VERSION "2021.24.4"

NS_ :

BS_:

BU_: VEH CH Receiver X

BO_ 22 DI_bmsRequest: 1 VEH
 SG_ DI_bmsOpenContactorsRequest : 4|1@1+ (1,0) [0|1] ""  Receiver
 SG_ DI_bmsRequestInterfaceVersion : 0|4@1+ (1,0) [0|15] ""  Receiver

BO_ 470 DI_limits: 5 VEH
 SG_ DI_limitBaseSpeed : 15|1@1+ (1,0) [0|1] ""  Receiver
 SG_ DI_limitClutch : 28|1@1+ (1,0) [0|1] ""  Receiver
 SG_ DI_limitDcCapTemp : 17|1@1+ (1,0) [0|1] ""  Receiver
 SG_ DI_limitDeltaFluidTemp : 5|1@1+ (1,0) [0|1] ""  Receiver
 SG_ DI_limitDiff : 22|1@1+ (1,0) [0|1] ""  Receiver
 SG_ DI_limitDischargePower : 6|1@1+ (1,0) [0|1] ""  Receiver
 SG_ DI_limitDriveTorque : 10|1@1+ (1,0) [0|1] ""  Receiver
 SG_ DI_limitGracefulPowerOff : 23|1@1+ (1,0) [0|1] ""  Receiver
 SG_ DI_limitIBat : 16|1@1+ (1,0) [0|1] ""  Receiver
 SG_ DI_limitIGBTJunctTemp : 24|1@1+ (1,0) [0|1] ""  Receiver
 SG_ DI_limitInverterTemp : 1|1@1+ (1,0) [0|1] ""  Receiver
 SG_ DI_limitLimpMode : 4|1@1+ (1,0) [0|1] ""  Receiver
 SG_ DI_limitMotorCurrent : 8|1@1+ (1,0) [0|1] ""  Receiver
 SG_ DI_limitMotorSpeed : 20|1@1+ (1,0) [0|1] ""  Receiver
 SG_ DI_limitMotorVoltage : 9|1@1+ (1,0) [0|1] ""  Receiver
 SG_ DI_limitObstacleDetection : 29|1@1+ (1,0) [0|1] ""  Receiver
 SG_ DI_limitOilPumpFluidTemp : 26|1@1+ (1,0) [0|1] ""  Receiver
 SG_ DI_limitPCBTemp : 0|1@1+ (1,0) [0|1] ""  Receiver
 SG_ DI_limitPoleTemp : 3|1@1+ (1,0) [0|1] ""  Receiver
 SG_ DI_limitRegenPower : 7|1@1+ (1,0) [0|1] ""  Receiver
 SG_ DI_limitRegenTorque : 11|1@1+ (1,0) [0|1] ""  Receiver
 SG_ DI_limitRotorTemp : 36|1@1+ (1,0) [0|1] ""  Receiver
 SG_ DI_limitShift : 14|1@1+ (1,0) [0|1] ""  Receiver
 SG_ DI_limitShockTorque : 25|1@1+ (1,0) [0|1] ""  Receiver
 SG_ DI_limitStatorFrequency : 27|1@1+ (1,0) [0|1] ""  Receiver
 SG_ DI_limitStatorTemp : 2|1@1+ (1,0) [0|1] ""  Receiver
 SG_ DI_limitTCDrive : 12|1@1+ (1,0) [0|1] ""  Receiver
 SG_ DI_limitTCRegen : 13|1@1+ (1,0) [0|1] ""  Receiver
 SG_ DI_limitVBatHigh : 19|1@1+ (1,0) [0|1] ""  Receiver
 SG_ DI_limitVBatLow : 18|1@1+ (1,0) [0|1] ""  Receiver
 SG_ DI_limitVehicleSpeed : 21|1@1+ (1,0) [0|1] ""  Receiver
 SG_ DI_limitdcLinkCapTemp : 33|1@1+ (1,0) [0|1] ""  Receiver
 SG_ DI_limithvDcCableTemp : 37|1@1+ (1,0) [0|1] ""  Receiver
 SG_ DI_limitnegDcBusbarTemp : 34|1@1+ (1,0) [0|1] ""  Receiver
 SG_ DI_limitphaseOutBusBarWeldTemp : 31|1@1+ (1,0) [0|1] ""  Receiver
 SG_ DI_limitphaseOutBusbarTemp : 30|1@1+ (1,0) [0|1] ""  Receiver
 SG_ DI_limitphaseOutLugTemp : 32|1@1+ (1,0) [0|1] ""  Receiver
 SG_ DI_limitposDcBusbarTemp : 35|1@1+ (1,0) [0|1] ""  Receiver

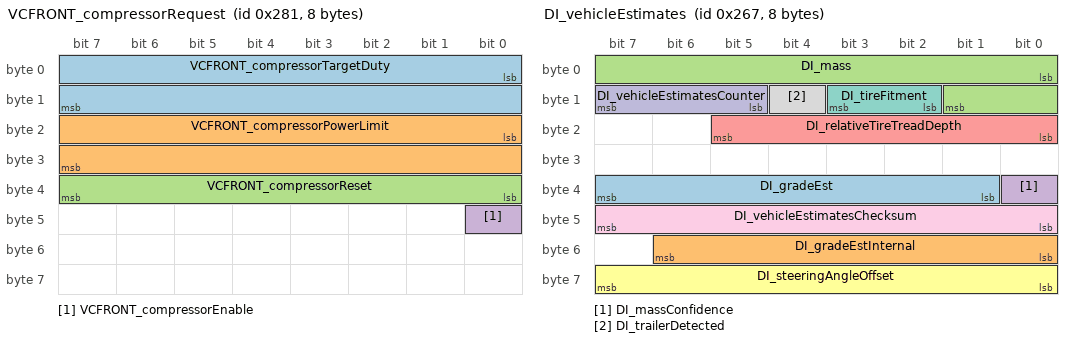
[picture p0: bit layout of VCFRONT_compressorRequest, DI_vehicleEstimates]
BO_ 641 VCFRONT_compressorRequest: 8 VEH
 SG_ VCFRONT_compressorTargetDuty : 0|16@1+ (0.1,0) [0|100] "%"  Receiver
 SG_ VCFRONT_compressorPowerLimit : 16|16@1+ (1,0) [0|65534] "W"  Receiver
 SG_ VCFRONT_compressorReset : 32|8@1+ (1,0) [0|255] ""  Receiver
 SG_ VCFRONT_compressorEnable : 40|1@1+ (1,0) [0|1] ""  Receiver

BO_ 603 APP_environment: 1 CH
 SG_ APP_environmentRainy : 0|1@1+ (1,0) [0|1] "" X
 SG_ APP_environmentSnowy : 1|1@1+ (1,0) [0|1] "" X

BO_ 615 DI_vehicleEstimates: 8 VEH
 SG_ DI_gradeEst : 33|7@1- (1,0) [-40|40] "%"  Receiver
 SG_ DI_gradeEstInternal : 48|7@1- (1,0) [-40|40] "%"  Receiver
 SG_ DI_mass : 0|10@1+ (5,1900) [1900|7010] "kg"  Receiver
 SG_ DI_massConfidence : 32|1@1+ (1,0) [0|1] ""  Receiver
 SG_ DI_relativeTireTreadDepth : 16|6@1- (0.2,0) [-6.2|6.2] "mm"  Receiver
 SG_ DI_steeringAngleOffset : 56|8@1- (0.2,0) [-25.6|25.4] "Deg"  Receiver
 SG_ DI_tireFitment : 10|2@1+ (1,0) [0|3] ""  Receiver
 SG_ DI_trailerDetected : 12|1@1+ (1,0) [0|1] ""  Receiver
 SG_ DI_vehicleEstimatesChecksum : 40|8@1+ (1,0) [0|255] ""  Receiver
 SG_ DI_vehicleEstimatesCounter : 13|3@1+ (1,0) [0|7] ""  Receiver

BO_ 322 VCLEFT_liftgateStatus: 8 VEH
 SG_ VCLEFT_liftgateStatusIndex M : 0|2@1+ (1,0) [0|2] "" X
 SG_ VCLEFT_liftgateLatchRequest m0 : 61|3@1+ (1,0) [0|4] "" X
 SG_ VCLEFT_liftgateMvmntNotAllowedCo m0 : 14|3@1+ (1,0) [0|5] "" X
 SG_ VCLEFT_liftgatePhysicalChimeRequ m0 : 21|3@1+ (1,0) [0|4] "" X
 SG_ VCLEFT_liftgatePosition m1 : 21|7@1- (1,46) [-5|95] "deg" X
 SG_ VCLEFT_liftgatePositionCalibrate m0 : 17|1@1+ (1,0) [0|1] "" X
 SG_ VCLEFT_liftgateRequestSource m0 : 7|3@1+ (1,0) [0|7] "" X
 SG_ VCLEFT_liftgateSpeed m1 : 28|10@1- (0.1,0) [-30|30] "deg/s" X
 SG_ VCLEFT_liftgateState m0 : 3|4@1+ (1,0) [0|12] "" X
 SG_ VCLEFT_liftgateStoppingCondition m0 : 10|4@1+ (1,0) [0|11] "" X
 SG_ VCLEFT_liftgateStrutCurrent m1 : 11|10@1- (0.1,0) [-30|30] "A" X
 SG_ VCLEFT_liftgateStrutDutyCycle m1 : 3|8@1- (1,0) [-100|100] "%" X
 SG_ VCLEFT_liftgateUIChimeRequest m0 : 18|3@1+ (1,0) [0|4] "" X

BO_ 537 VCSEC_TPMSData: 5 CH
 SG_ VCSEC_TPMSDataIndex M : 0|2@1+ (1,0) [0|3] ""  Receiver
 SG_ VCSEC_TPMSBatVoltage0 m0 : 24|8@1+ (0.01,1.5) [1.5|4.04] "V" X
 SG_ VCSEC_TPMSBatVoltage1 m1 : 24|8@1+ (0.01,1.5) [1.5|4.04] "V" X
 SG_ VCSEC_TPMSBatVoltage2 m2 : 24|8@1+ (0.01,1.5) [1.5|4.04] "V" X
 SG_ VCSEC_TPMSBatVoltage3 m3 : 24|8@1+ (0.01,1.5) [1.5|4.04] "V" X
 SG_ VCSEC_TPMSLocation0 m0 : 32|3@1+ (1,0) [0|4] "" X
 SG_ VCSEC_TPMSLocation1 m1 : 32|3@1+ (1,0) [0|4] "" X
 SG_ VCSEC_TPMSLocation2 m2 : 32|3@1+ (1,0) [0|4] "" X
 SG_ VCSEC_TPMSLocation3 m3 : 32|3@1+ (1,0) [0|4] "" X
 SG_ VCSEC_TPMSPressure0 m0 : 8|8@1+ (0.025,0) [0|6.35] "bar" X
 SG_ VCSEC_TPMSPressure1 m1 : 8|8@1+ (0.025,0) [0|6.35] "bar" X
 SG_ VCSEC_TPMSPressure2 m2 : 8|8@1+ (0.025,0) [0|6.35] "bar" X
 SG_ VCSEC_TPMSPressure3 m3 : 8|8@1+ (0.025,0) [0|6.35] "bar" X
 SG_ VCSEC_TPMSTemperature0 m0 : 16|8@1+ (1,-40) [-40|214] "C" X
 SG_ VCSEC_TPMSTemperature1 m1 : 16|8@1+ (1,-40) [-40|214] "C" X
 SG_ VCSEC_TPMSTemperature2 m2 : 16|8@1+ (1,-40) [-40|214] "C" X
 SG_ VCSEC_TPMSTemperature3 m3 : 16|8@1+ (1,-40) [-40|214] "C" X

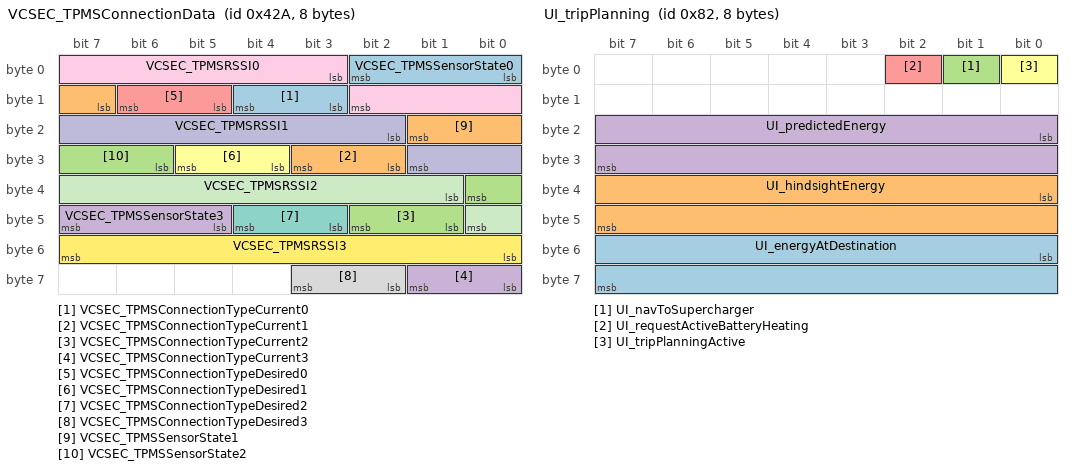
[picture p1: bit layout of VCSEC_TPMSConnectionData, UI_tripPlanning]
BO_ 1066 VCSEC_TPMSConnectionData: 8 VEH
 SG_ VCSEC_TPMSConnectionTypeCurrent0 : 11|2@1+ (1,0) [0|2] "" X
 SG_ VCSEC_TPMSConnectionTypeCurrent1 : 26|2@1+ (1,0) [0|2] "" X
 SG_ VCSEC_TPMSConnectionTypeCurrent2 : 41|2@1+ (1,0) [0|2] "" X
 SG_ VCSEC_TPMSConnectionTypeCurrent3 : 56|2@1+ (1,0) [0|2] "" X
 SG_ VCSEC_TPMSConnectionTypeDesired0 : 13|2@1+ (1,0) [0|2] "" X
 SG_ VCSEC_TPMSConnectionTypeDesired1 : 28|2@1+ (1,0) [0|2] "" X
 SG_ VCSEC_TPMSConnectionTypeDesired2 : 43|2@1+ (1,0) [0|2] "" X
 SG_ VCSEC_TPMSConnectionTypeDesired3 : 58|2@1+ (1,0) [0|2] "" X
 SG_ VCSEC_TPMSRSSI0 : 3|8@1- (1,0) [-127|0] "dBm" X
 SG_ VCSEC_TPMSRSSI1 : 18|8@1- (1,0) [-127|0] "dBm" X
 SG_ VCSEC_TPMSRSSI2 : 33|8@1- (1,0) [-127|0] "dBm" X
 SG_ VCSEC_TPMSRSSI3 : 48|8@1- (1,0) [-127|0] "dBm" X
 SG_ VCSEC_TPMSSensorState0 : 0|3@1+ (1,0) [0|4] "" X
 SG_ VCSEC_TPMSSensorState1 : 15|3@1+ (1,0) [0|4] "" X
 SG_ VCSEC_TPMSSensorState2 : 30|3@1+ (1,0) [0|4] "" X
 SG_ VCSEC_TPMSSensorState3 : 45|3@1+ (1,0) [0|4] "" X

BO_ 994 VCLEFT_lightStatus: 7 VEH
 SG_ VCLEFT_FLMapLightStatus : 6|2@1+ (1,0) [0|3] "" X
 SG_ VCLEFT_FLMapLightSwitchPressed : 14|1@1+ (1,0) [0|1] "" X
 SG_ VCLEFT_FRMapLightStatus : 8|2@1+ (1,0) [0|3] "" X
 SG_ VCLEFT_FRMapLightSwitchPressed : 15|1@1+ (1,0) [0|1] "" X
 SG_ VCLEFT_RLMapLightStatus : 10|2@1+ (1,0) [0|3] "" X
 SG_ VCLEFT_RLMapLightSwitchPressed : 16|1@1+ (1,0) [0|1] "" X
 SG_ VCLEFT_RRMapLightStatus : 12|2@1+ (1,0) [0|3] "" X
 SG_ VCLEFT_RRMapLightSwitchPressed : 17|1@1+ (1,0) [0|1] "" X
 SG_ VCLEFT_brakeLightStatus : 0|2@1+ (1,0) [0|3] "" X
 SG_ VCLEFT_brakeTrailerLightStatus : 22|2@1+ (1,0) [0|3] "" X
 SG_ VCLEFT_dynamicBrakeLightStatus : 44|2@1+ (1,0) [0|2] "" X
 SG_ VCLEFT_fogTrailerLightStatus : 26|2@1+ (1,0) [0|3] "" X
 SG_ VCLEFT_frontRideHeight : 28|8@1- (1,0) [-127|127] "mm" X
 SG_ VCLEFT_leftTurnTrailerLightStatus : 18|2@1+ (1,0) [0|3] "" X
 SG_ VCLEFT_rearRideHeight : 36|8@1- (1,0) [-127|127] "mm" X
 SG_ VCLEFT_reverseTrailerLightStatus : 49|2@1+ (1,0) [0|3] "" X
 SG_ VCLEFT_rideHeightSensorFault : 48|1@1+ (1,0) [0|1] "" X
 SG_ VCLEFT_rightTrnTrailerLightStatus : 20|2@1+ (1,0) [0|3] "" X
 SG_ VCLEFT_tailLightStatus : 2|2@1+ (1,0) [0|3] "" X
 SG_ VCLEFT_tailTrailerLightStatus : 24|2@1+ (1,0) [0|3] "" X
 SG_ VCLEFT_trailerDetected : 46|2@1+ (1,0) [0|3] "" X
 SG_ VCLEFT_turnSignalStatus : 4|2@1+ (1,0) [0|3] "" X

BO_ 513 VCFRONT_logging10Hz2: 8 VEH
 SG_ VCFRONT_logging10Hz2 M : 0|3@1+ (1,0) [0|7] "" X
 SG_ VCFRONT_activeLouverOpenPos m1 : 16|7@1+ (1,0) [0|100] "%" X
 SG_ VCFRONT_activeLouverOpenPosTarg m1 : 8|7@1+ (1,0) [0|100] "%" X
 SG_ VCFRONT_cclExvFlow m3 : 44|10@1+ (0.1,0) [0|100] "%" X
 SG_ VCFRONT_cclExvFlowTarget m5 : 44|10@1+ (0.1,0) [0|100] "%" X
 SG_ VCFRONT_cclExvState m6 : 20|3@1+ (1,0) [0|7] "" X
 SG_ VCFRONT_ccrExvFlow m3 : 54|10@1+ (0.1,0) [0|100] "%" X
 SG_ VCFRONT_ccrExvFlowTarget m5 : 54|10@1+ (0.1,0) [0|100] "%" X
 SG_ VCFRONT_ccrExvState m6 : 24|4@1+ (1,0) [0|7] "" X
 SG_ VCFRONT_chillerExvFlow m3 : 3|10@1+ (0.1,0) [0|100] "%" X
 SG_ VCFRONT_chillerExvFlowTarget m5 : 3|10@1+ (0.1,0) [0|100] "%" X
 SG_ VCFRONT_chillerExvState m6 : 3|4@1+ (1,0) [0|7] "" X
 SG_ VCFRONT_compDemandChiller m2 : 39|7@1+ (1,0) [0|100] "%" X
 SG_ VCFRONT_compDemandEvap m2 : 26|7@1+ (1,0) [0|100] "%" X
 SG_ VCFRONT_compressorState m2 : 24|2@1+ (1,0) [0|3] "" X
 SG_ VCFRONT_coolantValveMode m2 : 61|2@1+ (1,0) [0|3] "" X
 SG_ VCFRONT_evapExvFlow m3 : 13|10@1+ (0.1,0) [0|100] "%" X
 SG_ VCFRONT_evapExvFlowTarget m5 : 13|10@1+ (0.1,0) [0|100] "%" X
 SG_ VCFRONT_evapExvState m6 : 8|4@1+ (1,0) [0|7] "" X
 SG_ VCFRONT_exvFlowTarget m0 : 54|10@1+ (0.1,0) [0|100] "%" X
 SG_ VCFRONT_exvState m2 : 33|4@1+ (1,0) [0|7] "" X
 SG_ VCFRONT_fanDemand m2 : 16|7@1+ (1,0) [0|100] "%" X
 SG_ VCFRONT_hpBatteryLoadType m4 : 16|2@1+ (1,0) [0|2] "" X
 SG_ VCFRONT_hpBlendType m4 : 11|2@1+ (1,0) [0|2] "" X
 SG_ VCFRONT_hpCabinLoadType m4 : 14|2@1+ (1,0) [0|3] "" X
 SG_ VCFRONT_hpDominantLoad m4 : 8|3@1+ (1,0) [0|6] "" X
 SG_ VCFRONT_hpHighSideHX m4 : 3|2@1+ (1,0) [0|3] "" X
 SG_ VCFRONT_hpLowSideHX m4 : 5|2@1+ (1,0) [0|3] "" X
 SG_ VCFRONT_hpQuietModeEnabled m4 : 13|1@1+ (1,0) [0|1] "" X
 SG_ VCFRONT_hpReqCoolantMode m4 : 18|3@1+ (1,0) [0|4] "" X
 SG_ VCFRONT_lccExvFlow m3 : 34|10@1+ (0.1,0) [0|100] "%" X
 SG_ VCFRONT_lccExvFlowTarget m5 : 34|10@1+ (0.1,0) [0|100] "%" X
 SG_ VCFRONT_lccExvState m6 : 16|4@1+ (1,0) [0|8] "" X
 SG_ VCFRONT_pressureRefrigDischargeV m2 : 53|8@1+ (0.125,0) [0|31.75] "bar" X
 SG_ VCFRONT_pressureRefrigLiquid m1 : 40|8@1+ (0.125,0) [0|31.75] "bar" X
 SG_ VCFRONT_pressureRefrigSuctionVit m2 : 46|7@1+ (0.125,0) [0|11.5] "bar" X
 SG_ VCFRONT_pumpBatteryRPMActual m0 : 3|10@1+ (10,0) [0|10000] "rpm" X
 SG_ VCFRONT_pumpPowertrainRPMActual m0 : 13|10@1+ (10,0) [0|10000] "rpm" X
 SG_ VCFRONT_radiatorFanRPMActual m0 : 24|10@1+ (10,0) [0|10000] "rpm" X
 SG_ VCFRONT_recircExvFlow m3 : 24|10@1+ (0.1,0) [0|100] "%" X
 SG_ VCFRONT_recircExvFlowTarget m5 : 24|10@1+ (0.1,0) [0|100] "%" X
 SG_ VCFRONT_recircExvState m6 : 12|3@1+ (1,0) [0|7] "" X
 SG_ VCFRONT_solenoidEvapState m2 : 37|2@1+ (1,0) [0|3] "" X
 SG_ VCFRONT_tempRefrigDischarge m2 : 3|11@1+ (0.125,-40) [-40|150] "C" X
 SG_ VCFRONT_tempRefrigLiquid m1 : 24|11@1+ (0.125,-40) [-40|150] "C" X
 SG_ VCFRONT_tempSuperheatActFiltered m1 : 48|8@1- (0.25,26.5) [-5|58] "C" X
 SG_ VCFRONT_tempSuperheatActual m0 : 34|10@1+ (0.1,-20) [-20|80] "C" X
 SG_ VCFRONT_tempSuperheatTarget m0 : 44|10@1+ (0.1,0) [0|60] "C" X

BO_ 130 UI_tripPlanning: 8 VEH
 SG_ UI_energyAtDestination : 48|16@1- (0.01,0) [-327.67|327.67] "kWh" X
 SG_ UI_hindsightEnergy : 32|16@1- (0.01,0) [-327.67|327.67] "kWh" X
 SG_ UI_navToSupercharger : 1|1@1+ (1,0) [0|1] "" X
 SG_ UI_predictedEnergy : 16|16@1- (0.01,0) [-327.67|327.67] "kWh" X
 SG_ UI_requestActiveBatteryHeating : 2|1@1+ (1,0) [0|1] "" X
 SG_ UI_tripPlanningActive : 0|1@1+ (1,0) [0|1] "" X

BO_ 139 UI_tripPlanning2: 6 VEH
 SG_ UI_maxSpeedToReachDestination : 0|16@1+ (0.01,0) [0|655.34] "m/s" X
 SG_ UI_remainingWeightedRMSSpeed : 16|16@1+ (0.01,0) [0|655.34] "m/s" X
 SG_ UI_timeToDestination : 32|16@1+ (1,0) [0|65534] "s" X

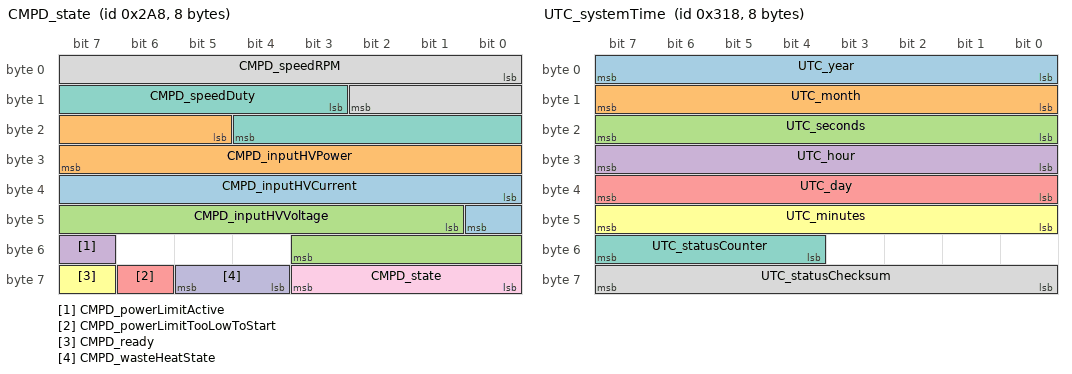
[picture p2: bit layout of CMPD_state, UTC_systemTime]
BO_ 680 CMPD_state: 8 VEH
 SG_ CMPD_inputHVCurrent : 32|9@1+ (0.1,0) [0|50] "A" X
 SG_ CMPD_inputHVPower : 21|11@1+ (10,0) [0|20000] "W" X
 SG_ CMPD_inputHVVoltage : 41|11@1+ (0.5,0) [0|1000] "V" X
 SG_ CMPD_powerLimitActive : 55|1@1+ (1,0) [0|1] "" X
 SG_ CMPD_powerLimitTooLowToStart : 62|1@1+ (1,0) [0|1] "" X
 SG_ CMPD_ready : 63|1@1+ (1,0) [0|1] "" X
 SG_ CMPD_speedDuty : 11|10@1+ (0.1,0) [0|100] "%" X
 SG_ CMPD_speedRPM : 0|11@1+ (10,0) [0|20000] "RPM" X
 SG_ CMPD_state : 56|4@1+ (1,0) [0|15] "" X
 SG_ CMPD_wasteHeatState : 60|2@1+ (1,0) [0|3] "" X

BO_ 1029 VIN_info: 8 VEH
 SG_ VIN_infoIndex M : 0|8@1+ (1,0) [0|255] "" X
 SG_ VIN_B405 m17 : 8|56@1+ (1,0) [0|7.2057594038E+016] "" X
 SG_ VIN_C405 m18 : 8|56@1+ (1,0) [0|7.2057594038E+016] "" X
 SG_ VIN_A405 m16 : 8|56@1+ (1,0) [0|7.2057594038E+016] "" X

BO_ 1025 BMS_brickVoltages: 8 VEH
 SG_ BMS_brickIndex M : 0|8@1+ (1,0) [0|0] ""  Receiver
 SG_ BMS_brickStatus : 8|8@1+ (1,0) [0|0] ""  Receiver
 SG_ BMS_brick0 m0 : 16|16@1+ (0.0001,0) [0|0] "V"  Receiver
 SG_ BMS_brick1 m0 : 32|16@1+ (0.0001,0) [0|0] "V"  Receiver
 SG_ BMS_brick2 m0 : 48|16@1+ (0.0001,0) [0|0] "V"  Receiver
 SG_ BMS_brick3 m1 : 16|16@1+ (0.0001,0) [0|0] "V"  Receiver
 SG_ BMS_brick4 m1 : 32|16@1+ (0.0001,0) [0|0] "V"  Receiver
 SG_ BMS_brick5 m1 : 48|16@1+ (0.0001,0) [0|0] "V"  Receiver
 SG_ BMS_brick6 m2 : 16|16@1+ (0.0001,0) [0|0] "V"  Receiver
 SG_ BMS_brick7 m2 : 32|16@1+ (0.0001,0) [0|0] "V"  Receiver
 SG_ BMS_brick8 m2 : 48|16@1+ (0.0001,0) [0|0] "V"  Receiver
 SG_ BMS_brick9 m3 : 16|16@1+ (0.0001,0) [0|0] "V"  Receiver
 SG_ BMS_brick10 m3 : 32|16@1+ (0.0001,0) [0|0] "V"  Receiver
 SG_ BMS_brick11 m3 : 48|16@1+ (0.0001,0) [0|0] "V"  Receiver
 SG_ BMS_brick12 m4 : 16|16@1+ (0.0001,0) [0|0] "V"  Receiver
 SG_ BMS_brick13 m4 : 32|16@1+ (0.0001,0) [0|0] "V"  Receiver
 SG_ BMS_brick14 m4 : 48|16@1+ (0.0001,0) [0|0] "V"  Receiver
 SG_ BMS_brick15 m5 : 16|16@1+ (0.0001,0) [0|0] "V"  Receiver
 SG_ BMS_brick16 m5 : 32|16@1+ (0.0001,0) [0|0] "V"  Receiver
 SG_ BMS_brick17 m5 : 48|16@1+ (0.0001,0) [0|0] "V"  Receiver
 SG_ BMS_brick18 m6 : 16|16@1+ (0.0001,0) [0|0] "V"  Receiver
 SG_ BMS_brick19 m6 : 32|16@1+ (0.0001,0) [0|0] "V"  Receiver
 SG_ BMS_brick20 m6 : 48|16@1+ (0.0001,0) [0|0] "V"  Receiver
 SG_ BMS_brick21 m7 : 16|16@1+ (0.0001,0) [0|0] "V"  Receiver
 SG_ BMS_brick22 m7 : 32|16@1+ (0.0001,0) [0|0] "V"  Receiver
 SG_ BMS_brick23 m7 : 48|16@1+ (0.0001,0) [0|0] "V"  Receiver
 SG_ BMS_brick24 m8 : 16|16@1+ (0.0001,0) [0|0] "V"  Receiver
 SG_ BMS_brick25 m8 : 32|16@1+ (0.0001,0) [0|0] "V"  Receiver
 SG_ BMS_brick26 m8 : 48|16@1+ (0.0001,0) [0|0] "V"  Receiver
 SG_ BMS_brick27 m9 : 16|16@1+ (0.0001,0) [0|0] "V"  Receiver
 SG_ BMS_brick28 m9 : 32|16@1+ (0.0001,0) [0|0] "V"  Receiver
 SG_ BMS_brick29 m9 : 48|16@1+ (0.0001,0) [0|0] "V"  Receiver
 SG_ BMS_brick30 m10 : 16|16@1+ (0.0001,0) [0|0] "V"  Receiver
 SG_ BMS_brick31 m10 : 32|16@1+ (0.0001,0) [0|0] "V"  Receiver
 SG_ BMS_brick32 m10 : 48|16@1+ (0.0001,0) [0|0] "V"  Receiver
 SG_ BMS_brick34 m11 : 16|16@1+ (0.0001,0) [0|0] "V"  Receiver
 SG_ BMS_brick33 m11 : 32|16@1+ (0.0001,0) [0|0] "V"  Receiver
 SG_ BMS_brick35 m11 : 48|16@1+ (0.0001,0) [0|0] "V"  Receiver
 SG_ BMS_brick36 m12 : 16|16@1+ (0.0001,0) [0|0] "V"  Receiver
 SG_ BMS_brick37 m12 : 32|16@1+ (0.0001,0) [0|0] "V"  Receiver
 SG_ BMS_brick38 m12 : 48|16@1+ (0.0001,0) [0|0] "V"  Receiver
 SG_ BMS_brick39 m13 : 16|16@1+ (0.0001,0) [0|0] "V"  Receiver
 SG_ BMS_brick40 m13 : 32|16@1+ (0.0001,0) [0|0] "V"  Receiver
 SG_ BMS_brick41 m13 : 48|16@1+ (0.0001,0) [0|0] "V"  Receiver
 SG_ BMS_brick42 m14 : 16|16@1+ (0.0001,0) [0|0] "V"  Receiver
 SG_ BMS_brick43 m14 : 32|16@1+ (0.0001,0) [0|0] "V"  Receiver
 SG_ BMS_brick44 m14 : 48|16@1+ (0.0001,0) [0|0] "V"  Receiver
 SG_ BMS_brick45 m15 : 16|16@1+ (0.0001,0) [0|0] "V"  Receiver
 SG_ BMS_brick46 m15 : 32|16@1+ (0.0001,0) [0|0] "V"  Receiver
 SG_ BMS_brick47 m15 : 48|16@1+ (0.0001,0) [0|0] "V"  Receiver
 SG_ BMS_brick48 m16 : 16|16@1+ (0.0001,0) [0|0] "V"  Receiver
 SG_ BMS_brick49 m16 : 32|16@1+ (0.0001,0) [0|0] "V"  Receiver
 SG_ BMS_brick50 m16 : 48|16@1+ (0.0001,0) [0|0] "V"  Receiver
 SG_ BMS_brick51 m17 : 16|16@1+ (0.0001,0) [0|0] "V"  Receiver
 SG_ BMS_brick52 m17 : 32|16@1+ (0.0001,0) [0|0] "V"  Receiver
 SG_ BMS_brick53 m17 : 48|16@1+ (0.0001,0) [0|0] "V"  Receiver
 SG_ BMS_brick54 m18 : 16|16@1+ (0.0001,0) [0|0] "V"  Receiver
 SG_ BMS_brick55 m18 : 32|16@1+ (0.0001,0) [0|0] "V"  Receiver
 SG_ BMS_brick56 m18 : 48|16@1+ (0.0001,0) [0|0] "V"  Receiver
 SG_ BMS_brick57 m19 : 16|16@1+ (0.0001,0) [0|0] "V"  Receiver
 SG_ BMS_brick58 m19 : 32|16@1+ (0.0001,0) [0|0] "V"  Receiver
 SG_ BMS_brick59 m19 : 48|16@1+ (0.0001,0) [0|0] "V"  Receiver
 SG_ BMS_brick60 m20 : 16|16@1+ (0.0001,0) [0|0] "V"  Receiver
 SG_ BMS_brick61 m20 : 32|16@1+ (0.0001,0) [0|0] "V"  Receiver
 SG_ BMS_brick62 m20 : 48|16@1+ (0.0001,0) [0|0] "V"  Receiver
 SG_ BMS_brick63 m21 : 16|16@1+ (0.0001,0) [0|0] "V"  Receiver
 SG_ BMS_brick64 m21 : 32|16@1+ (0.0001,0) [0|0] "V"  Receiver
 SG_ BMS_brick65 m21 : 48|16@1+ (0.0001,0) [0|0] "V"  Receiver
 SG_ BMS_brick66 m22 : 16|16@1+ (0.0001,0) [0|0] "V"  Receiver
 SG_ BMS_brick67 m22 : 32|16@1+ (0.0001,0) [0|0] "V"  Receiver
 SG_ BMS_brick68 m22 : 48|16@1+ (0.0001,0) [0|0] "V"  Receiver
 SG_ BMS_brick69 m23 : 16|16@1+ (0.0001,0) [0|0] "V"  Receiver
 SG_ BMS_brick70 m23 : 32|16@1+ (0.0001,0) [0|0] "V"  Receiver
 SG_ BMS_brick71 m23 : 48|16@1+ (0.0001,0) [0|0] "V"  Receiver
 SG_ BMS_brick72 m24 : 16|16@1+ (0.0001,0) [0|0] "V"  Receiver
 SG_ BMS_brick73 m24 : 32|16@1+ (0.0001,0) [0|0] "V"  Receiver
 SG_ BMS_brick74 m24 : 48|16@1+ (0.0001,0) [0|0] "V"  Receiver
 SG_ BMS_brick75 m25 : 16|16@1+ (0.0001,0) [0|0] "V"  Receiver
 SG_ BMS_brick76 m25 : 32|16@1+ (0.0001,0) [0|0] "V"  Receiver
 SG_ BMS_brick77 m25 : 48|16@1+ (0.0001,0) [0|0] "V"  Receiver
 SG_ BMS_brick78 m26 : 16|16@1+ (0.0001,0) [0|0] "V"  Receiver
 SG_ BMS_brick79 m26 : 32|16@1+ (0.0001,0) [0|0] "V"  Receiver
 SG_ BMS_brick80 m26 : 48|16@1+ (0.0001,0) [0|0] "V"  Receiver
 SG_ BMS_brick81 m27 : 16|16@1+ (0.0001,0) [0|0] "V"  Receiver
 SG_ BMS_brick82 m27 : 32|16@1+ (0.0001,0) [0|0] "V"  Receiver
 SG_ BMS_brick83 m27 : 48|16@1+ (0.0001,0) [0|0] "V"  Receiver
 SG_ BMS_brick84 m28 : 16|16@1+ (0.0001,0) [0|0] "V"  Receiver
 SG_ BMS_brick85 m28 : 32|16@1+ (0.0001,0) [0|0] "V"  Receiver
 SG_ BMS_brick86 m28 : 48|16@1+ (0.0001,0) [0|0] "V"  Receiver
 SG_ BMS_brick87 m29 : 16|16@1+ (0.0001,0) [0|0] "V"  Receiver
 SG_ BMS_brick88 m29 : 32|16@1+ (0.0001,0) [0|0] "V"  Receiver
 SG_ BMS_brick89 m29 : 48|16@1+ (0.0001,0) [0|0] "V"  Receiver
 SG_ BMS_brick90 m30 : 16|16@1+ (0.0001,0) [0|0] "V"  Receiver
 SG_ BMS_brick91 m30 : 32|16@1+ (0.0001,0) [0|0] "V"  Receiver
 SG_ BMS_brick92 m30 : 48|16@1+ (0.0001,0) [0|0] "V"  Receiver
 SG_ BMS_brick93 m31 : 16|16@1+ (0.0001,0) [0|0] "V"  Receiver
 SG_ BMS_brick94 m31 : 32|16@1+ (0.0001,0) [0|0] "V"  Receiver
 SG_ BMS_brick95 m31 : 48|16@1+ (0.0001,0) [0|0] "V"  Receiver
 SG_ BMS_brick96 m32 : 16|16@1+ (0.0001,0) [0|0] "V"  Receiver
 SG_ BMS_brick97 m32 : 32|16@1+ (0.0001,0) [0|0] "V"  Receiver
 SG_ BMS_brick98 m32 : 48|16@1+ (0.0001,0) [0|0] "V"  Receiver
 SG_ BMS_brick99 m33 : 16|16@1+ (0.0001,0) [0|0] "V"  Receiver
 SG_ BMS_brick100 m33 : 32|16@1+ (0.0001,0) [0|0] "V"  Receiver
 SG_ BMS_brick101 m33 : 48|16@1+ (0.0001,0) [0|0] "V"  Receiver
 SG_ BMS_brick102 m34 : 16|16@1+ (0.0001,0) [0|0] "V"  Receiver
 SG_ BMS_brick103 m34 : 32|16@1+ (0.0001,0) [0|0] "V"  Receiver
 SG_ BMS_brick104 m34 : 48|16@1+ (0.0001,0) [0|0] "V"  Receiver
 SG_ BMS_brick105 m35 : 16|16@1+ (0.0001,0) [0|0] "V"  Receiver
 SG_ BMS_brick106 m35 : 32|16@1+ (0.0001,0) [0|0] "V"  Receiver
 SG_ BMS_brick107 m35 : 48|16@1+ (0.0001,0) [0|0] "V"  Receiver

BO_ 792 UTC_systemTime: 8 VEH
 SG_ UTC_year: 0|8@1+ (1,0) [0|0] "" X
 SG_ UTC_month: 8|8@1+ (1,0) [0|0] "" X
 SG_ UTC_seconds: 16|8@1+ (1,0) [0|0] "" X
 SG_ UTC_hour: 24|8@1+ (1,0) [0|0] "" X
 SG_ UTC_day: 32|8@1+ (1,0) [0|0] "" X
 SG_ UTC_minutes: 40|8@1+ (1,0) [0|0] "" X
 SG_ UTC_statusCounter: 52|4@1+ (1,0) [0|0] "" X
 SG_ UTC_statusChecksum: 56|8@1+ (1,0) [0|0] "" X

BO_ 1320 UTC_unixTime: 4 VEH
 SG_ UTC_unixTime : 0|32@0+ (1,0) [0|0] "sec" X

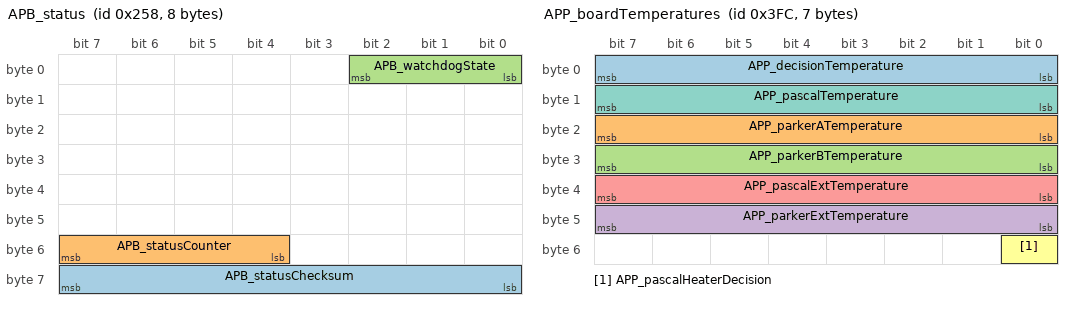
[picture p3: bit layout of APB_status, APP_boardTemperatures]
BO_ 600 APB_status: 8 CH
 SG_ APB_statusChecksum: 56|8@1+ (1,0) [0|0] "" X
 SG_ APB_statusCounter: 52|4@1+ (1,0) [0|0] "" X
 SG_ APB_watchdogState: 0|3@1+ (1,0) [0|0] "" X

BO_ 1020 APP_boardTemperatures: 7 CH
 SG_ APP_decisionTemperature: 0|8@1+ (1,-128) [0|0] "C" X
 SG_ APP_parkerATemperature: 16|8@1+ (1,-128) [0|0] "C" X
 SG_ APP_parkerBTemperature: 24|8@1+ (1,-128) [0|0] "C" X
 SG_ APP_parkerExtTemperature: 40|8@1+ (1,-128) [0|0] "C" X
 SG_ APP_pascalExtTemperature: 32|8@1+ (1,-128) [0|0] "C" X
 SG_ APP_pascalHeaterDecision: 48|1@1+ (1,0) [0|0] "" X
 SG_ APP_pascalTemperature: 8|8@1+ (1,-128) [0|0] "C" X

BO_ 1012 APP_camCalibrationStatus: 6 CH
 SG_ APP_cameraPosition M: 0|4@1+ (1,0) [0|0] "" X
 SG_ APP_mainCamExtPitchCal m1: 8|9@1+ (0.05,-12.5) [0|0] "deg" X
 SG_ APP_mainCamExtYawCal m1: 17|9@1+ (0.05,-12.5) [0|0] "deg" X
 SG_ APP_mainCalibTime m1: 26|7@1+ (1,0) [0|0] "min" X
 SG_ APP_mainCalibProgress m1: 33|7@1+ (1,0) [0|0] "percent" X
 SG_ APP_mainCalibrated m1: 40|1@1+ (1,0) [0|0] "" X
 SG_ APP_narrowCamExtPitchCal m2: 8|9@1+ (0.05,-12.5) [0|0] "deg" X
 SG_ APP_narrowCamExtYawCal m2: 17|9@1+ (0.05,-12.5) [0|0] "deg" X
 SG_ APP_narrowCalibTime m2: 26|7@1+ (1,0) [0|0] "min" X
 SG_ APP_narrowCalibProgress m2: 33|7@1+ (1,0) [0|0] "percent" X
 SG_ APP_narrowCalibrated m2: 40|1@1+ (1,0) [0|0] "" X
 SG_ APP_fisheyeCamExtPitchCal m3: 8|9@1+ (0.05,-12.5) [0|0] "deg" X
 SG_ APP_fisheyeCamExtYawCal m3: 17|9@1+ (0.05,-12.5) [0|0] "deg" X
 SG_ APP_fisheyeCalibTime m3: 26|7@1+ (1,0) [0|0] "min" X
 SG_ APP_fisheyeCalibProgress m3: 33|7@1+ (1,0) [0|0] "percent" X
 SG_ APP_fisheyeCalibrated m3: 40|1@1+ (1,0) [0|0] "" X
 SG_ APP_lPillarCamExtPitchCal m4: 8|9@1+ (0.05,-12.5) [0|0] "deg" X
 SG_ APP_lPillarCamExtYawCal m4: 17|9@1+ (0.05,-12.5) [0|0] "deg" X
 SG_ APP_lPillarCalibTime m4: 26|7@1+ (1,0) [0|0] "min" X
 SG_ APP_lPillarCalibProgress m4: 33|7@1+ (1,0) [0|0] "percent" X
 SG_ APP_lPillarCalibrated m4: 40|1@1+ (1,0) [0|0] "" X
 SG_ APP_rPillarCamExtPitchCal m5: 8|9@1+ (0.05,-12.5) [0|0] "deg" X
 SG_ APP_rPillarCamExtYawCal m5: 17|9@1+ (0.05,-12.5) [0|0] "deg" X
 SG_ APP_rPillarCalibTime m5: 26|7@1+ (1,0) [0|0] "min" X
 SG_ APP_rPillarCalibProgress m5: 33|7@1+ (1,0) [0|0] "percent" X
 SG_ APP_rPillarCalibrated m5: 40|1@1+ (1,0) [0|0] "" X
 SG_ APP_lRepeatCamExtPitchCal m6: 8|9@1+ (0.05,-12.5) [0|0] "deg" X
 SG_ APP_lRepeatCamExtYawCal m6: 17|9@1+ (0.05,-12.5) [0|0] "deg" X
 SG_ APP_lRepeatCalibTime m6: 26|7@1+ (1,0) [0|0] "min" X
 SG_ APP_lRepeatCalibProgress m6: 33|7@1+ (1,0) [0|0] "percent" X
 SG_ APP_lRepeatCalibrated m6: 40|1@1+ (1,0) [0|0] "" X
 SG_ APP_rRepeatCamExtPitchCal m7: 8|9@1+ (0.05,-12.5) [0|0] "deg" X
 SG_ APP_rRepeatCamExtYawCal m7: 17|9@1+ (0.05,-12.5) [0|0] "deg" X
 SG_ APP_rRepeatCalibTime m7: 26|7@1+ (1,0) [0|0] "min" X
 SG_ APP_rRepeatCalibProgress m7: 33|7@1+ (1,0) [0|0] "percent" X
 SG_ APP_rRepeatCalibrated m7: 40|1@1+ (1,0) [0|0] "" X
 SG_ APP_backupCamExtPitchCal m8: 8|9@1+ (0.05,-12.5) [0|0] "deg" X
 SG_ APP_backupCamExtYawCal m8: 17|9@1+ (0.05,-12.5) [0|0] "deg" X
 SG_ APP_backupCalibTime m8: 26|7@1+ (1,0) [0|0] "min" X
 SG_ APP_backupCalibProgress m8: 33|7@1+ (1,0) [0|0] "percent" X
 SG_ APP_backupCalibrated m8: 40|1@1+ (1,0) [0|0] "" X

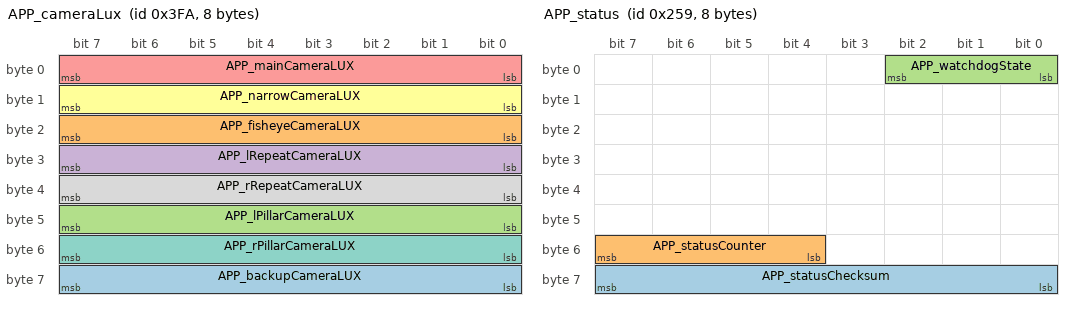
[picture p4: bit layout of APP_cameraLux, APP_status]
BO_ 1018 APP_cameraLux: 8 CH
 SG_ APP_backupCameraLUX: 56|8@1+ (50,0) [0|0] "lux" X
 SG_ APP_fisheyeCameraLUX: 16|8@1+ (50,0) [0|0] "lux" X
 SG_ APP_lPillarCameraLUX: 40|8@1+ (50,0) [0|0] "lux" X
 SG_ APP_lRepeatCameraLUX: 24|8@1+ (50,0) [0|0] "lux" X
 SG_ APP_mainCameraLUX: 0|8@1+ (50,0) [0|0] "lux" X
 SG_ APP_narrowCameraLUX: 8|8@1+ (50,0) [0|0] "lux" X
 SG_ APP_rPillarCameraLUX: 48|8@1+ (50,0) [0|0] "lux" X
 SG_ APP_rRepeatCameraLUX: 32|8@1+ (50,0) [0|0] "lux" X

BO_ 1040 APP_cameraStatus: 1 CH
 SG_ APP_backupCameraFeedGood: 0|1@1+ (1,0) [0|0] "" X
 SG_ APP_backupCameraFrameRate: 1|6@1+ (1,0) [0|0] "" X

BO_ 1353 APP_info: 8 CH
 SG_ APP_infoIndex M: 0|8@1+ (1,0) [0|0] "" X
 SG_ APP_buildType m0: 8|8@1+ (1,0) [0|0] "" X
 SG_ APP_infoAppFwGitHashBytes m1: 10|54@1+ (4,0) [0|0] "" X
 SG_ APP_infoAppApGitHashBytes m2: 10|54@1+ (4,0) [0|0] "" X

BO_ 601 APP_status: 8 CH
 SG_ APP_statusChecksum: 56|8@1+ (1,0) [0|0] "" X
 SG_ APP_statusCounter: 52|4@1+ (1,0) [0|0] "" X
 SG_ APP_watchdogState: 0|3@1+ (1,0) [0|0] "" X

BO_ 809 APP_warningMatrix0: 8 CH
 SG_ APP_w001_DEPRECATED: 0|1@1+ (1,0) [0|0] "" X
 SG_ APP_w002_ldwDisabled: 1|1@1+ (1,0) [0|0] "" X
 SG_ APP_w003_isaDisabled: 2|1@1+ (1,0) [0|0] "" X
 SG_ APP_w004_accDisabled: 3|1@1+ (1,0) [0|0] "" X
 SG_ APP_w005_fcwCancelled: 4|1@1+ (1,0) [0|0] "" X
 SG_ APP_w006_aebCancelled: 5|1@1+ (1,0) [0|0] "" X
 SG_ APP_w007_ahlbDisabled: 6|1@1+ (1,0) [0|0] "" X
 SG_ APP_w008_parkDisabled: 7|1@1+ (1,0) [0|0] "" X
 SG_ APP_w009_aebFault: 8|1@1+ (1,0) [0|0] "" X
 SG_ APP_w010_radcCalibIssue: 9|1@1+ (1,0) [0|0] "" X
 SG_ APP_w011_scaEvent: 10|1@1+ (1,0) [0|0] "" X
 SG_ APP_w012_Cam_BootFailure: 11|1@1+ (1,0) [0|0] "" X
 SG_ APP_w013_Cam_Watchdog: 12|1@1+ (1,0) [0|0] "" X
 SG_ APP_w014_swAssert: 13|1@1+ (1,0) [0|0] "" X
 SG_ APP_w015_Camera_Failsafes: 14|1@1+ (1,0) [0|0] "" X
 SG_ APP_w016_aeb_e_event: 15|1@1+ (1,0) [0|0] "" X
 SG_ APP_w017_Cam_Msg_MIA: 16|1@1+ (1,0) [0|0] "" X
 SG_ APP_w018_ECU_Power_Issue: 17|1@1+ (1,0) [0|0] "" X
 SG_ APP_w019_ECU_Stack_Overflow: 18|1@1+ (1,0) [0|0] "" X
 SG_ APP_w020_ECU_checkstopError: 19|1@1+ (1,0) [0|0] "" X
 SG_ APP_w021_ECU_Temperature_Issue: 20|1@1+ (1,0) [0|0] "" X
 SG_ APP_w022_ECU_EEPROM_Failure: 21|1@1+ (1,0) [0|0] "" X
 SG_ APP_w023_ECU_Cam_Statemismatc: 22|1@1+ (1,0) [0|0] "" X
 SG_ APP_w024_ECU_Watchdog_Reset: 23|1@1+ (1,0) [0|0] "" X
 SG_ APP_w025_LC_Steering_Override: 24|1@1+ (1,0) [0|0] "" X
 SG_ APP_w026_ECU_timingIssue: 25|1@1+ (1,0) [0|0] "" X
 SG_ APP_w027_ECU_Reset_Fault: 26|1@1+ (1,0) [0|0] "" X
 SG_ APP_w028_spi_rx_error: 27|1@1+ (1,0) [0|0] "" X
 SG_ APP_w029_spi_tx_error: 28|1@1+ (1,0) [0|0] "" X
 SG_ APP_w030_Heater_Issue: 29|1@1+ (1,0) [0|0] "" X
 SG_ APP_w031_canRxError: 30|1@1+ (1,0) [0|0] "" X
 SG_ APP_w032_canTxError: 31|1@1+ (1,0) [0|0] "" X
 SG_ APP_w033_gtwMia: 32|1@1+ (1,0) [0|0] "" X
 SG_ APP_w034_sccmMia: 33|1@1+ (1,0) [0|0] "" X
 SG_ APP_w035_espMia: 34|1@1+ (1,0) [0|0] "" X
 SG_ APP_w036_bdyMia: 35|1@1+ (1,0) [0|0] "" X
 SG_ APP_w037_camTacIssue: 36|1@1+ (1,0) [0|0] "" X
 SG_ APP_w038_camFailure: 37|1@1+ (1,0) [0|0] "" X
 SG_ APP_w039_sdm_rcm_Mia: 38|1@1+ (1,0) [0|0] "" X
 SG_ APP_w040_autopilotAngleSaturated: 39|1@1+ (1,0) [0|0] "" X
 SG_ APP_w041_autopilotRateSaturated: 40|1@1+ (1,0) [0|0] "" X
 SG_ APP_w042_autopilotAborting: 41|1@1+ (1,0) [0|0] "" X
 SG_ APP_w043_camLongRunTime: 42|1@1+ (1,0) [0|0] "" X
 SG_ APP_w044_appMobileyeFailure: 43|1@1+ (1,0) [0|0] "" X
 SG_ APP_w045_radMia: 44|1@1+ (1,0) [0|0] "" X
 SG_ APP_w046_eepromRecordAbsent: 45|1@1+ (1,0) [0|0] "" X
 SG_ APP_w047_edrEvent: 46|1@1+ (1,0) [0|0] "" X
 SG_ APP_w048_APP_Features_Disabled: 47|1@1+ (1,0) [0|0] "" X
 SG_ APP_w049_eyeqVersionMismatch: 48|1@1+ (1,0) [0|0] "" X
 SG_ APP_w050_aeb_event: 49|1@1+ (1,0) [0|0] "" X
 SG_ APP_w051_radcEcuIssue: 50|1@1+ (1,0) [0|0] "" X
 SG_ APP_w052_radcSensorIssue: 51|1@1+ (1,0) [0|0] "" X
 SG_ APP_w053_radcCommIssue: 52|1@1+ (1,0) [0|0] "" X
 SG_ APP_w054_camAutofix: 53|1@1+ (1,0) [0|0] "" X
 SG_ APP_w055_radcVersionMismatch: 54|1@1+ (1,0) [0|0] "" X
 SG_ APP_w056_diMia: 55|1@1+ (1,0) [0|0] "" X
 SG_ APP_w057_mcuMia: 56|1@1+ (1,0) [0|0] "" X
 SG_ APP_w058_epbMia: 57|1@1+ (1,0) [0|0] "" X
 SG_ APP_w059_parkMia: 58|1@1+ (1,0) [0|0] "" X
 SG_ APP_w060_fcw_event: 59|1@1+ (1,0) [0|0] "" X
 SG_ APP_w061_airSuspensionMia: 60|1@1+ (1,0) [0|0] "" X
 SG_ APP_w062_radcAlignment: 61|1@1+ (1,0) [0|0] "" X
 SG_ APP_w063_parkVersionMismatch: 62|1@1+ (1,0) [0|0] "" X
 SG_ APP_w064_epasMia: 63|1@1+ (1,0) [0|0] "" X

BO_ 873 APP_warningMatrix1: 8 CH
 SG_ APP_w065_deserializerOvercurrent: 0|1@1+ (1,0) [0|0] "" X
 SG_ APP_w066_deserializerLockLost: 1|1@1+ (1,0) [0|0] "" X
 SG_ APP_w067_steeringAlignment: 2|1@1+ (1,0) [0|0] "" X
 SG_ APP_w068_vlInconsistency: 3|1@1+ (1,0) [0|0] "" X
 SG_ APP_w069_apcSpaceMasked: 4|1@1+ (1,0) [0|0] "" X
 SG_ APP_w070_apcIncompleteCal: 5|1@1+ (1,0) [0|0] "" X
 SG_ APP_w071_selfparkStarted: 6|1@1+ (1,0) [0|0] "" X
 SG_ APP_w072_selfparkComplete: 7|1@1+ (1,0) [0|0] "" X
 SG_ APP_w073_issueEscalatedLDW: 8|1@1+ (1,0) [0|0] "" X
 SG_ APP_w074_inPathStationaryObst: 9|1@1+ (1,0) [0|0] "" X
 SG_ APP_w075_scMia: 10|1@1+ (1,0) [0|0] "" X
 SG_ APP_w076_mobilEyeSetC: 11|1@1+ (1,0) [0|0] "" X
 SG_ APP_w077_pmmActive: 12|1@1+ (1,0) [0|0] "" X
 SG_ APP_w078_pmmActive2: 13|1@1+ (1,0) [0|0] "" X
 SG_ APP_w079_edrAvailable: 14|1@1+ (1,0) [0|0] "" X
 SG_ APP_w080_accFailedActivation: 15|1@1+ (1,0) [0|0] "" X
 SG_ APP_w081_pmmActiveBraking: 16|1@1+ (1,0) [0|0] "" X
 SG_ APP_w082_inPathFSviolation: 17|1@1+ (1,0) [0|0] "" X
 SG_ APP_w083_inPathRADObject: 18|1@1+ (1,0) [0|0] "" X
 SG_ APP_w084_pmmIPSO: 19|1@1+ (1,0) [0|0] "" X
 SG_ APP_w085_pmmSteering: 20|1@1+ (1,0) [0|0] "" X
 SG_ APP_w086_robCollision: 21|1@1+ (1,0) [0|0] "" X
 SG_ APP_w087_DEPRECATED: 22|1@1+ (1,0) [0|0] "" X
 SG_ APP_w088_DEPRECATED: 23|1@1+ (1,0) [0|0] "" X
 SG_ APP_w089_DEPRECATED: 24|1@1+ (1,0) [0|0] "" X
 SG_ APP_w090_DEPRECATED: 25|1@1+ (1,0) [0|0] "" X
 SG_ APP_w091_DEPRECATED: 26|1@1+ (1,0) [0|0] "" X
 SG_ APP_w092_DEPRECATED: 27|1@1+ (1,0) [0|0] "" X
 SG_ APP_w093_DEPRECATED: 28|1@1+ (1,0) [0|0] "" X
 SG_ APP_w094_DEPRECATED: 29|1@1+ (1,0) [0|0] "" X
 SG_ APP_w095_DEPRECATED: 30|1@1+ (1,0) [0|0] "" X
 SG_ APP_w096_DEPRECATED: 31|1@1+ (1,0) [0|0] "" X
 SG_ APP_w097_DEPRECATED: 32|1@1+ (1,0) [0|0] "" X
 SG_ APP_w098_DEPRECATED: 33|1@1+ (1,0) [0|0] "" X
 SG_ APP_w099_DEPRECATED: 34|1@1+ (1,0) [0|0] "" X
 SG_ APP_w100_DEPRECATED: 35|1@1+ (1,0) [0|0] "" X
 SG_ APP_w101_DEPRECATED: 36|1@1+ (1,0) [0|0] "" X
 SG_ APP_w102_DEPRECATED: 37|1@1+ (1,0) [0|0] "" X
 SG_ APP_w103_robExperimentalAEB: 38|1@1+ (1,0) [0|0] "" X
 SG_ APP_w104_DEPRECATED: 39|1@1+ (1,0) [0|0] "" X
 SG_ APP_w105_DEPRECATED: 40|1@1+ (1,0) [0|0] "" X
 SG_ APP_w106_torsionBarOffset: 41|1@1+ (1,0) [0|0] "" X

BO_ 1065 APP_warningMatrix2: 8 CH
 SG_ APP_w129_mainCamExtNotCal: 0|1@1+ (1,0) [0|0] "" X
 SG_ APP_w130_narrowCamExtNotCal: 1|1@1+ (1,0) [0|0] "" X
 SG_ APP_w131_mainCamCalSaved: 2|1@1+ (1,0) [0|0] "" X
 SG_ APP_w132_narrowCamCalSaved: 3|1@1+ (1,0) [0|0] "" X
 SG_ APP_w133_mainCamInitFault: 4|1@1+ (1,0) [0|0] "" X
 SG_ APP_w134_narrowCamInitFault: 5|1@1+ (1,0) [0|0] "" X
 SG_ APP_w135_fisheyeCamInitFault: 6|1@1+ (1,0) [0|0] "" X
 SG_ APP_w136_lPillarCamInitFault: 7|1@1+ (1,0) [0|0] "" X
 SG_ APP_w137_rPillarCamInitFault: 8|1@1+ (1,0) [0|0] "" X
 SG_ APP_w138_lRepeatCamInitFault: 9|1@1+ (1,0) [0|0] "" X
 SG_ APP_w139_rRepeatCamInitFault: 10|1@1+ (1,0) [0|0] "" X
 SG_ APP_w140_backupCamInitFault: 11|1@1+ (1,0) [0|0] "" X
 SG_ APP_w141_ECU_Thermal_Issue: 12|1@1+ (1,0) [0|0] "" X
 SG_ APP_w142_fwdCamPitchProblem: 13|1@1+ (1,0) [0|0] "" X
 SG_ APP_w143_IDF_event: 14|1@1+ (1,0) [0|0] "" X
 SG_ APP_w144_fanctrldError: 15|1@1+ (1,0) [0|0] "" X
 SG_ APP_w145_camSelfCalIssue: 16|1@1+ (1,0) [0|0] "" X
 SG_ APP_w146_telemetryProblem: 17|1@1+ (1,0) [0|0] "" X
 SG_ APP_w147_selfieCamInitFault: 18|1@1+ (1,0) [0|0] "" X
 SG_ APP_w148_overlayActive: 19|1@1+ (1,0) [0|0] "" X
 SG_ APP_w149_diskFull: 20|1@1+ (1,0) [0|0] "" X
 SG_ APP_w150_diMiaPartyBus: 21|1@1+ (1,0) [0|0] "" X
 SG_ APP_w151_epasMiaPartyBus: 22|1@1+ (1,0) [0|0] "" X
 SG_ APP_w152_espMiaPartyBus: 23|1@1+ (1,0) [0|0] "" X
 SG_ APP_w153_rcmMiaPartyBus: 24|1@1+ (1,0) [0|0] "" X
 SG_ APP_w154_vcleftMiaPartyBus: 25|1@1+ (1,0) [0|0] "" X
 SG_ APP_w155_vcrightMiaPartyBus: 26|1@1+ (1,0) [0|0] "" X
 SG_ APP_w156_epblMiaVehBus: 27|1@1+ (1,0) [0|0] "" X
 SG_ APP_w157_sccmMiaVehBus: 28|1@1+ (1,0) [0|0] "" X
 SG_ APP_w158_vcfrontMiaVehBus: 29|1@1+ (1,0) [0|0] "" X
 SG_ APP_w159_vcleftMiaVehBus: 30|1@1+ (1,0) [0|0] "" X
 SG_ APP_w160_vcrightMiaVehBus: 31|1@1+ (1,0) [0|0] "" X
 SG_ APP_w161_backupCameraUnavailable: 32|1@1+ (1,0) [0|0] "" X
 SG_ APP_w162_mainCameraTypeError: 33|1@1+ (1,0) [0|0] "" X
 SG_ APP_w163_narrowCameraTypeError: 34|1@1+ (1,0) [0|0] "" X
 SG_ APP_w164_fisheyeCameraTypeError: 35|1@1+ (1,0) [0|0] "" X
 SG_ APP_w165_lPillarCameraTypeError: 36|1@1+ (1,0) [0|0] "" X
 SG_ APP_w166_rPillarCameraTypeError: 37|1@1+ (1,0) [0|0] "" X
 SG_ APP_w167_lRepeatCameraTypeError: 38|1@1+ (1,0) [0|0] "" X
 SG_ APP_w168_rRepeatCameraTypeError: 39|1@1+ (1,0) [0|0] "" X
 SG_ APP_w169_backupCameraTypeError: 40|1@1+ (1,0) [0|0] "" X
 SG_ APP_w170_selfieCameraTypeError: 41|1@1+ (1,0) [0|0] "" X
 SG_ APP_w171_appHighCoolantFlowReq: 42|1@1+ (1,0) [0|0] "" X
 SG_ APP_w172_fisheyeCamExtNotCal: 43|1@1+ (1,0) [0|0] "" X
 SG_ APP_w173_lPillarCamExtNotCal: 44|1@1+ (1,0) [0|0] "" X
 SG_ APP_w174_rPillarCamExtNotCal: 45|1@1+ (1,0) [0|0] "" X
 SG_ APP_w175_lRepeatCamExtNotCal: 46|1@1+ (1,0) [0|0] "" X
 SG_ APP_w176_rRepeatCamExtNotCal: 47|1@1+ (1,0) [0|0] "" X
 SG_ APP_w177_fisheyeCamCalSaved: 48|1@1+ (1,0) [0|0] "" X
 SG_ APP_w178_lPillarCamCalSaved: 49|1@1+ (1,0) [0|0] "" X
 SG_ APP_w179_rPillarCamCalSaved: 50|1@1+ (1,0) [0|0] "" X
 SG_ APP_w180_lRepeatCamCalSaved: 51|1@1+ (1,0) [0|0] "" X
 SG_ APP_w181_rRepeatCamCalSaved: 52|1@1+ (1,0) [0|0] "" X
 SG_ APP_w182_mainCameraStreamExit: 53|1@1+ (1,0) [0|0] "" X
 SG_ APP_w183_narrowCameraStreamExit: 54|1@1+ (1,0) [0|0] "" X
 SG_ APP_w184_fisheyeCameraStreamExit: 55|1@1+ (1,0) [0|0] "" X
 SG_ APP_w185_lPillarCameraStreamExit: 56|1@1+ (1,0) [0|0] "" X
 SG_ APP_w186_rPillarCameraStreamExit: 57|1@1+ (1,0) [0|0] "" X
 SG_ APP_w187_lRepeatCameraStreamExit: 58|1@1+ (1,0) [0|0] "" X
 SG_ APP_w188_rRepeatCameraStreamExit: 59|1@1+ (1,0) [0|0] "" X
 SG_ APP_w189_backupCameraStreamExit: 60|1@1+ (1,0) [0|0] "" X
 SG_ APP_w190_selfieCameraStreamExit: 61|1@1+ (1,0) [0|0] "" X
 SG_ APP_w191_autopilotAborting: 62|1@1+ (1,0) [0|0] "" X
 SG_ APP_w192_emergencySpeakerFail: 63|1@1+ (1,0) [0|0] "" X

BO_ 1081 APP_warningMatrix3: 8 CH
 SG_ APP_w193_camWindshieldUnclean: 0|1@1+ (1,0) [0|0] "" X
 SG_ APP_w194_accDriverResumeRqrd: 1|1@1+ (1,0) [0|0] "" X
 SG_ APP_w195_scwUnavailable: 2|1@1+ (1,0) [0|0] "" X
 SG_ APP_w196_stopSignWarning: 3|1@1+ (1,0) [0|0] "" X
 SG_ APP_w197_redLightWarning: 4|1@1+ (1,0) [0|0] "" X
 SG_ APP_w198_tsrUnavailable: 5|1@1+ (1,0) [0|0] "" X
 SG_ APP_w199_apcAbort: 6|1@1+ (1,0) [0|0] "" X
 SG_ APP_w200_lcSlowdown: 7|1@1+ (1,0) [0|0] "" X
 SG_ APP_w201_lcAborting: 8|1@1+ (1,0) [0|0] "" X
 SG_ APP_w202_scwNoisyEnvironment: 9|1@1+ (1,0) [0|0] "" X
 SG_ APP_w203_apcActivation: 10|1@1+ (1,0) [0|0] "" X
 SG_ APP_w204_apcFinalFront: 11|1@1+ (1,0) [0|0] "" X
 SG_ APP_w205_apcFinalRear: 12|1@1+ (1,0) [0|0] "" X
 SG_ APP_w206_autosteerNotEnabled: 13|1@1+ (1,0) [0|0] "" X
 SG_ APP_w207_autosteerUnavailable: 14|1@1+ (1,0) [0|0] "" X
 SG_ APP_w208_rackDetected: 15|1@1+ (1,0) [0|0] "" X
 SG_ APP_w209_autoSummonRequest: 16|1@1+ (1,0) [0|0] "" X
 SG_ APP_w210_camObstrcted: 17|1@1+ (1,0) [0|0] "" X
 SG_ APP_w211_accNoSeatBelt: 18|1@1+ (1,0) [0|0] "" X
 SG_ APP_w212_lcUnavailableStrikeOut: 19|1@1+ (1,0) [0|0] "" X
 SG_ APP_w213_autosteerStruckOut: 20|1@1+ (1,0) [0|0] "" X
 SG_ APP_w214_driverNotIntracting: 21|1@1+ (1,0) [0|0] "" X
 SG_ APP_w215_contDriverNotIntracting: 22|1@1+ (1,0) [0|0] "" X
 SG_ APP_w216_driverOverriding: 23|1@1+ (1,0) [0|0] "" X
 SG_ APP_w217_lcUnavailableSpeeding: 24|1@1+ (1,0) [0|0] "" X
 SG_ APP_w218_lcSpeedExceededLimit: 25|1@1+ (1,0) [0|0] "" X
 SG_ APP_w219_lcTempUnavailableSpeed: 26|1@1+ (1,0) [0|0] "" X
 SG_ APP_w220_lcTempUnavailableRoad: 27|1@1+ (1,0) [0|0] "" X
 SG_ APP_w221_accRadarBlind: 28|1@1+ (1,0) [0|0] "" X
 SG_ APP_w222_accCameraBlind: 29|1@1+ (1,0) [0|0] "" X
 SG_ APP_w223_accObjectInPath: 30|1@1+ (1,0) [0|0] "" X
 SG_ APP_w224_accCameraCalibration: 31|1@1+ (1,0) [0|0] "" X
 SG_ APP_w225_lcDegradedVisSpeedLmt: 32|1@1+ (1,0) [0|0] "" X
 SG_ APP_w226_lcCamCalNeededSpeedLmt: 33|1@1+ (1,0) [0|0] "" X
 SG_ APP_w227_virtualWallBlocked: 34|1@1+ (1,0) [0|0] "" X
 SG_ APP_w228_DEPRECATED: 35|1@1+ (1,0) [0|0] "" X
 SG_ APP_w229_alcUltrasoundDamaged: 36|1@1+ (1,0) [0|0] "" X
 SG_ APP_w230_alcUltrasoundBlocked: 37|1@1+ (1,0) [0|0] "" X

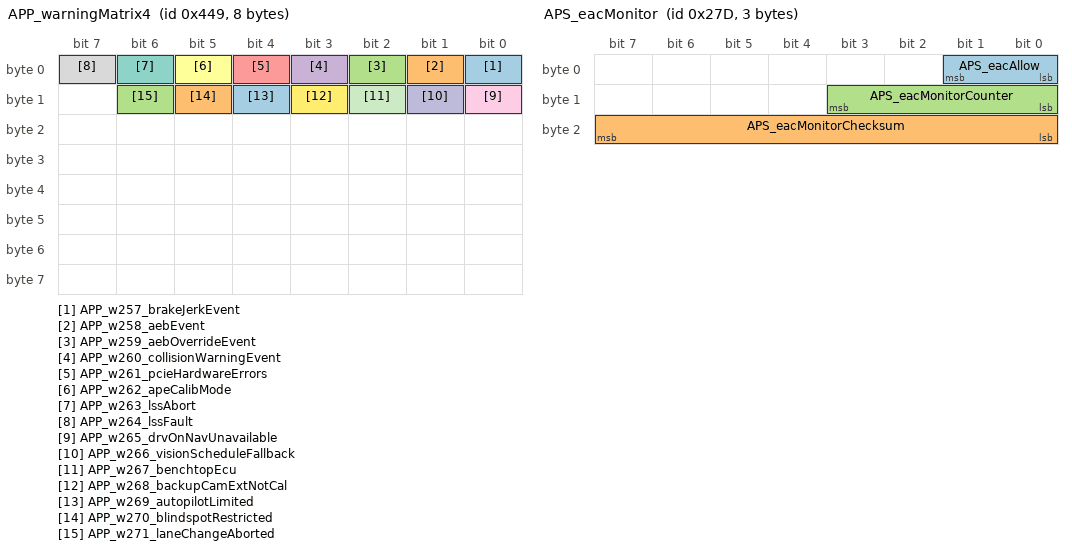
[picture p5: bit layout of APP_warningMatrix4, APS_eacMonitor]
BO_ 1097 APP_warningMatrix4: 8 CH
 SG_ APP_w257_brakeJerkEvent: 0|1@1+ (1,0) [0|0] "" X
 SG_ APP_w258_aebEvent: 1|1@1+ (1,0) [0|0] "" X
 SG_ APP_w259_aebOverrideEvent: 2|1@1+ (1,0) [0|0] "" X
 SG_ APP_w260_collisionWarningEvent: 3|1@1+ (1,0) [0|0] "" X
 SG_ APP_w261_pcieHardwareErrors: 4|1@1+ (1,0) [0|0] "" X
 SG_ APP_w262_apeCalibMode: 5|1@1+ (1,0) [0|0] "" X
 SG_ APP_w263_lssAbort: 6|1@1+ (1,0) [0|0] "" X
 SG_ APP_w264_lssFault: 7|1@1+ (1,0) [0|0] "" X
 SG_ APP_w265_drvOnNavUnavailable: 8|1@1+ (1,0) [0|0] "" X
 SG_ APP_w266_visionScheduleFallback: 9|1@1+ (1,0) [0|0] "" X
 SG_ APP_w267_benchtopEcu: 10|1@1+ (1,0) [0|0] "" X
 SG_ APP_w268_backupCamExtNotCal: 11|1@1+ (1,0) [0|0] "" X
 SG_ APP_w269_autopilotLimited: 12|1@1+ (1,0) [0|0] "" X
 SG_ APP_w270_blindspotRestricted: 13|1@1+ (1,0) [0|0] "" X
 SG_ APP_w271_laneChangeAborted: 14|1@1+ (1,0) [0|0] "" X

BO_ 637 APS_eacMonitor: 3 VEH
 SG_ APS_eacAllow: 0|2@1+ (1,0) [0|0] "" X
 SG_ APS_eacMonitorChecksum: 16|8@1+ (1,0) [0|0] "" X
 SG_ APS_eacMonitorCounter: 8|4@1+ (1,0) [0|0] "" X

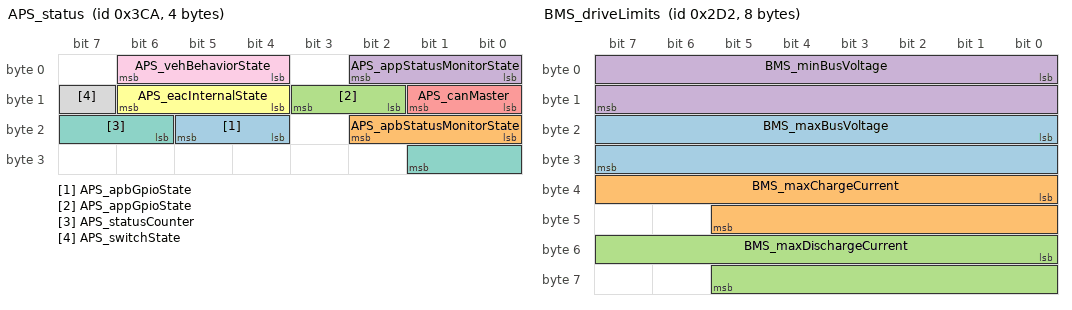
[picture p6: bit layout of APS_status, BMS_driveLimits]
BO_ 970 APS_status: 4 CH
 SG_ APS_apbGpioState: 20|2@1+ (1,0) [0|0] "" X
 SG_ APS_apbStatusMonitorState: 16|3@1+ (1,0) [0|0] "" X
 SG_ APS_appGpioState: 10|2@1+ (1,0) [0|0] "" X
 SG_ APS_appStatusMonitorState: 0|3@1+ (1,0) [0|0] "" X
 SG_ APS_canMaster: 8|2@1+ (1,0) [0|0] "" X
 SG_ APS_eacInternalState: 12|3@1+ (1,0) [0|0] "" X
 SG_ APS_statusCounter: 22|4@1+ (1,0) [0|0] "" X
 SG_ APS_switchState: 15|1@1+ (1,0) [0|0] "" X
 SG_ APS_vehBehaviorState: 4|3@1+ (1,0) [0|0] "" X

BO_ 811 APS_warningMatrix0: 8 CH
 SG_ APS_w001_DEPRECATED: 0|1@1+ (1,0) [0|0] "" X
 SG_ APS_w002_ldwDisabled: 1|1@1+ (1,0) [0|0] "" X
 SG_ APS_w003_isaDisabled: 2|1@1+ (1,0) [0|0] "" X
 SG_ APS_w004_accDisabled: 3|1@1+ (1,0) [0|0] "" X
 SG_ APS_w005_fcwCancelled: 4|1@1+ (1,0) [0|0] "" X
 SG_ APS_w006_aebCancelled: 5|1@1+ (1,0) [0|0] "" X
 SG_ APS_w007_ahlbDisabled: 6|1@1+ (1,0) [0|0] "" X
 SG_ APS_w008_parkDisabled: 7|1@1+ (1,0) [0|0] "" X
 SG_ APS_w009_aebFault: 8|1@1+ (1,0) [0|0] "" X
 SG_ APS_w010_radcCalibIssue: 9|1@1+ (1,0) [0|0] "" X
 SG_ APS_w011_scaEvent: 10|1@1+ (1,0) [0|0] "" X
 SG_ APS_w012_Cam_BootFailure: 11|1@1+ (1,0) [0|0] "" X
 SG_ APS_w013_Cam_Watchdog: 12|1@1+ (1,0) [0|0] "" X
 SG_ APS_w014_swAssert: 13|1@1+ (1,0) [0|0] "" X
 SG_ APS_w015_Camera_Failsafes: 14|1@1+ (1,0) [0|0] "" X
 SG_ APS_w016_aeb_e_event: 15|1@1+ (1,0) [0|0] "" X
 SG_ APS_w017_Cam_Msg_MIA: 16|1@1+ (1,0) [0|0] "" X
 SG_ APS_w018_ECU_Power_Issue: 17|1@1+ (1,0) [0|0] "" X
 SG_ APS_w019_ECU_Stack_Overflow: 18|1@1+ (1,0) [0|0] "" X
 SG_ APS_w020_ECU_checkstopError: 19|1@1+ (1,0) [0|0] "" X
 SG_ APS_w021_ECU_Temperature_Issue: 20|1@1+ (1,0) [0|0] "" X
 SG_ APS_w022_ECU_EEPROM_Failure: 21|1@1+ (1,0) [0|0] "" X
 SG_ APS_w023_ECU_Cam_Statemismatc: 22|1@1+ (1,0) [0|0] "" X
 SG_ APS_w024_ECU_Watchdog_Reset: 23|1@1+ (1,0) [0|0] "" X
 SG_ APS_w025_LC_Steering_Override: 24|1@1+ (1,0) [0|0] "" X
 SG_ APS_w026_ECU_timingIssue: 25|1@1+ (1,0) [0|0] "" X
 SG_ APS_w027_ECU_Reset_Fault: 26|1@1+ (1,0) [0|0] "" X
 SG_ APS_w028_spi_rx_error: 27|1@1+ (1,0) [0|0] "" X
 SG_ APS_w029_spi_tx_error: 28|1@1+ (1,0) [0|0] "" X
 SG_ APS_w030_Heater_Issue: 29|1@1+ (1,0) [0|0] "" X
 SG_ APS_w031_canRxError: 30|1@1+ (1,0) [0|0] "" X
 SG_ APS_w032_canTxError: 31|1@1+ (1,0) [0|0] "" X
 SG_ APS_w033_gtwMia: 32|1@1+ (1,0) [0|0] "" X
 SG_ APS_w034_sccmMia: 33|1@1+ (1,0) [0|0] "" X
 SG_ APS_w035_espMia: 34|1@1+ (1,0) [0|0] "" X
 SG_ APS_w036_bdyMia: 35|1@1+ (1,0) [0|0] "" X
 SG_ APS_w037_camTacIssue: 36|1@1+ (1,0) [0|0] "" X
 SG_ APS_w038_camFailure: 37|1@1+ (1,0) [0|0] "" X
 SG_ APS_w039_sdm_rcm_Mia: 38|1@1+ (1,0) [0|0] "" X
 SG_ APS_w040_autopilotAngleSaturated: 39|1@1+ (1,0) [0|0] "" X
 SG_ APS_w041_autopilotRateSaturated: 40|1@1+ (1,0) [0|0] "" X
 SG_ APS_w042_autopilotAborting: 41|1@1+ (1,0) [0|0] "" X
 SG_ APS_w043_camLongRunTime: 42|1@1+ (1,0) [0|0] "" X
 SG_ APS_w044_appMobileyeFailure: 43|1@1+ (1,0) [0|0] "" X
 SG_ APS_w045_radMia: 44|1@1+ (1,0) [0|0] "" X
 SG_ APS_w046_eepromRecordAbsent: 45|1@1+ (1,0) [0|0] "" X
 SG_ APS_w047_edrEvent: 46|1@1+ (1,0) [0|0] "" X
 SG_ APS_w048_DAS_Features_Disabled: 47|1@1+ (1,0) [0|0] "" X
 SG_ APS_w049_eyeqVersionMismatch: 48|1@1+ (1,0) [0|0] "" X
 SG_ APS_w050_aeb_event: 49|1@1+ (1,0) [0|0] "" X
 SG_ APS_w051_radcEcuIssue: 50|1@1+ (1,0) [0|0] "" X
 SG_ APS_w052_radcSensorIssue: 51|1@1+ (1,0) [0|0] "" X
 SG_ APS_w053_radcCommIssue: 52|1@1+ (1,0) [0|0] "" X
 SG_ APS_w054_camAutofix: 53|1@1+ (1,0) [0|0] "" X
 SG_ APS_w055_radcVersionMismatch: 54|1@1+ (1,0) [0|0] "" X
 SG_ APS_w056_diMia: 55|1@1+ (1,0) [0|0] "" X
 SG_ APS_w057_mcuMia: 56|1@1+ (1,0) [0|0] "" X
 SG_ APS_w058_epbMia: 57|1@1+ (1,0) [0|0] "" X
 SG_ APS_w059_parkMia: 58|1@1+ (1,0) [0|0] "" X
 SG_ APS_w060_fcw_event: 59|1@1+ (1,0) [0|0] "" X
 SG_ APS_w061_tasMia: 60|1@1+ (1,0) [0|0] "" X
 SG_ APS_w062_radcAlignment: 61|1@1+ (1,0) [0|0] "" X
 SG_ APS_w063_parkVersionMismatch: 62|1@1+ (1,0) [0|0] "" X
 SG_ APS_w064_epasMia: 63|1@1+ (1,0) [0|0] "" X

BO_ 876 APS_warningMatrix1: 8 CH
 SG_ APS_w065_deserializerOvercurrent: 0|1@1+ (1,0) [0|0] "" X
 SG_ APS_w066_deserializerLockLost: 1|1@1+ (1,0) [0|0] "" X
 SG_ APS_w067_steeringAlignment: 2|1@1+ (1,0) [0|0] "" X
 SG_ APS_w068_vlInconsistency: 3|1@1+ (1,0) [0|0] "" X
 SG_ APS_w069_apcSpaceMasked: 4|1@1+ (1,0) [0|0] "" X
 SG_ APS_w070_apcIncompleteCal: 5|1@1+ (1,0) [0|0] "" X
 SG_ APS_w071_selfparkStarted: 6|1@1+ (1,0) [0|0] "" X
 SG_ APS_w072_selfparkComplete: 7|1@1+ (1,0) [0|0] "" X
 SG_ APS_w073_issueEscalatedLDW: 8|1@1+ (1,0) [0|0] "" X
 SG_ APS_w074_inPathStationaryObst: 9|1@1+ (1,0) [0|0] "" X
 SG_ APS_w075_scMia: 10|1@1+ (1,0) [0|0] "" X
 SG_ APS_w076_mobilEyeSetC: 11|1@1+ (1,0) [0|0] "" X
 SG_ APS_w077_pmmActive: 12|1@1+ (1,0) [0|0] "" X
 SG_ APS_w078_pmmActive2: 13|1@1+ (1,0) [0|0] "" X
 SG_ APS_w079_edrAvailable: 14|1@1+ (1,0) [0|0] "" X
 SG_ APS_w080_accFailedActivation: 15|1@1+ (1,0) [0|0] "" X
 SG_ APS_w081_pmmActiveBraking: 16|1@1+ (1,0) [0|0] "" X
 SG_ APS_w082_inPathFSviolation: 17|1@1+ (1,0) [0|0] "" X
 SG_ APS_w083_inPathRADObject: 18|1@1+ (1,0) [0|0] "" X
 SG_ APS_w084_pmmIPSO: 19|1@1+ (1,0) [0|0] "" X
 SG_ APS_w085_pmmSteering: 20|1@1+ (1,0) [0|0] "" X
 SG_ APS_w086_robCollision: 21|1@1+ (1,0) [0|0] "" X
 SG_ APS_w087_DEPRECATED: 22|1@1+ (1,0) [0|0] "" X
 SG_ APS_w088_DEPRECATED: 23|1@1+ (1,0) [0|0] "" X
 SG_ APS_w089_DEPRECATED: 24|1@1+ (1,0) [0|0] "" X
 SG_ APS_w090_DEPRECATED: 25|1@1+ (1,0) [0|0] "" X
 SG_ APS_w091_DEPRECATED: 26|1@1+ (1,0) [0|0] "" X
 SG_ APS_w092_DEPRECATED: 27|1@1+ (1,0) [0|0] "" X
 SG_ APS_w093_DEPRECATED: 28|1@1+ (1,0) [0|0] "" X
 SG_ APS_w094_DEPRECATED: 29|1@1+ (1,0) [0|0] "" X
 SG_ APS_w095_DEPRECATED: 30|1@1+ (1,0) [0|0] "" X
 SG_ APS_w096_DEPRECATED: 31|1@1+ (1,0) [0|0] "" X
 SG_ APS_w097_DEPRECATED: 32|1@1+ (1,0) [0|0] "" X
 SG_ APS_w098_DEPRECATED: 33|1@1+ (1,0) [0|0] "" X
 SG_ APS_w099_DEPRECATED: 34|1@1+ (1,0) [0|0] "" X
 SG_ APS_w100_DEPRECATED: 35|1@1+ (1,0) [0|0] "" X
 SG_ APS_w101_DEPRECATED: 36|1@1+ (1,0) [0|0] "" X
 SG_ APS_w102_DEPRECATED: 37|1@1+ (1,0) [0|0] "" X
 SG_ APS_w103_robExperimentalAEB: 38|1@1+ (1,0) [0|0] "" X
 SG_ APS_w104_DEPRECATED: 39|1@1+ (1,0) [0|0] "" X
 SG_ APS_w105_DEPRECATED: 40|1@1+ (1,0) [0|0] "" X
 SG_ APS_w106_torsionBarOffset: 41|1@1+ (1,0) [0|0] "" X

BO_ 1113 APS_warningMatrix2: 8 CH
 SG_ APS_w129_ECU_Power_Issue: 0|1@1+ (1,0) [0|0] "" X
 SG_ APS_w130_ECU_Thermal_Issue: 1|1@1+ (1,0) [0|0] "" X
 SG_ APS_w131_trap_exception: 2|1@1+ (1,0) [0|0] "" X
 SG_ APS_w132_appVersionMismatch: 3|1@1+ (1,0) [0|0] "" X
 SG_ APS_w133_VEHSwitchError: 4|1@1+ (1,0) [0|0] "" X
 SG_ APS_w134_appMia: 5|1@1+ (1,0) [0|0] "" X
 SG_ APS_w135_appCritical: 6|1@1+ (1,0) [0|0] "" X
 SG_ APS_w136_gpsDisabled: 7|1@1+ (1,0) [0|0] "" X
 SG_ APS_w137_gpsFaultReset: 8|1@1+ (1,0) [0|0] "" X
 SG_ APS_w138_gpsComIssue: 9|1@1+ (1,0) [0|0] "" X
 SG_ APS_w139_udpBufferOverflow: 10|1@1+ (1,0) [0|0] "" X
 SG_ APS_w140_vcfrontMiaVEH: 11|1@1+ (1,0) [0|0] "" X
 SG_ APS_w141_rcmMiaPartyBus: 12|1@1+ (1,0) [0|0] "" X
 SG_ APS_w142_diMiaPartyBus: 13|1@1+ (1,0) [0|0] "" X
 SG_ APS_w143_espMiaPartyBus: 14|1@1+ (1,0) [0|0] "" X
 SG_ APS_w144_vcleftMiaPartyBus: 15|1@1+ (1,0) [0|0] "" X
 SG_ APS_w145_vcrightMiaPartyBus: 16|1@1+ (1,0) [0|0] "" X
 SG_ APS_w146_epas3pMiaPartyBus: 17|1@1+ (1,0) [0|0] "" X
 SG_ APS_w147_vcleftMiaVehBus: 18|1@1+ (1,0) [0|0] "" X
 SG_ APS_w148_vcrightMiaVehBus: 19|1@1+ (1,0) [0|0] "" X
 SG_ APS_w149_epblMiaVehBus: 20|1@1+ (1,0) [0|0] "" X
 SG_ APS_w150_sccmMiaVehBus: 21|1@1+ (1,0) [0|0] "" X
 SG_ APS_w151_apRecovered: 22|1@1+ (1,0) [0|0] "" X
 SG_ APS_w152_gpsFusionStatus: 23|1@1+ (1,0) [0|0] "" X
 SG_ APS_w153_eacInhibit: 24|1@1+ (1,0) [0|0] "" X
 SG_ APS_w155_VEHLwipError: 26|1@1+ (1,0) [0|0] "" X
 SG_ APS_w156_lwipAssert: 27|1@1+ (1,0) [0|0] "" X
 SG_ APS_w157_autopilotReboot: 28|1@1+ (1,0) [0|0] "" X
 SG_ APS_w158_apbMia: 29|1@1+ (1,0) [0|0] "" X
 SG_ APS_w159_apbCritical: 30|1@1+ (1,0) [0|0] "" X
 SG_ APS_w160_apbVersionMismatch: 31|1@1+ (1,0) [0|0] "" X
 SG_ APS_w161_gpsAntennaDisconnected: 32|1@1+ (1,0) [0|0] "" X

BO_ 848 APS_warningMatrix3: 8 CH
 SG_ APS_w193_camWindshieldUnclean: 0|1@1+ (1,0) [0|0] "" X
 SG_ APS_w194_accDriverResumeRqrd: 1|1@1+ (1,0) [0|0] "" X
 SG_ APS_w195_scwUnavailable: 2|1@1+ (1,0) [0|0] "" X
 SG_ APS_w196_stopSignWarning: 3|1@1+ (1,0) [0|0] "" X
 SG_ APS_w197_redLightWarning: 4|1@1+ (1,0) [0|0] "" X
 SG_ APS_w198_tsrUnavailable: 5|1@1+ (1,0) [0|0] "" X
 SG_ APS_w199_apcAbort: 6|1@1+ (1,0) [0|0] "" X
 SG_ APS_w200_lcSlowdown: 7|1@1+ (1,0) [0|0] "" X
 SG_ APS_w201_lcAborting: 8|1@1+ (1,0) [0|0] "" X
 SG_ APS_w202_scwNoisyEnvironment: 9|1@1+ (1,0) [0|0] "" X
 SG_ APS_w203_apcActivation: 10|1@1+ (1,0) [0|0] "" X
 SG_ APS_w204_apcFinalFront: 11|1@1+ (1,0) [0|0] "" X
 SG_ APS_w205_apcFinalRear: 12|1@1+ (1,0) [0|0] "" X
 SG_ APS_w206_autosteerNotEnabled: 13|1@1+ (1,0) [0|0] "" X
 SG_ APS_w207_autosteerUnavailable: 14|1@1+ (1,0) [0|0] "" X
 SG_ APS_w208_rackDetected: 15|1@1+ (1,0) [0|0] "" X
 SG_ APS_w209_autoSummonRequest: 16|1@1+ (1,0) [0|0] "" X
 SG_ APS_w210_camObstrcted: 17|1@1+ (1,0) [0|0] "" X
 SG_ APS_w211_accNoSeatBelt: 18|1@1+ (1,0) [0|0] "" X
 SG_ APS_w212_lcUnavailableStrikeOut: 19|1@1+ (1,0) [0|0] "" X
 SG_ APS_w213_autosteerStruckOut: 20|1@1+ (1,0) [0|0] "" X
 SG_ APS_w214_driverNotIntracting: 21|1@1+ (1,0) [0|0] "" X
 SG_ APS_w215_contDriverNotIntracting: 22|1@1+ (1,0) [0|0] "" X
 SG_ APS_w216_driverOverriding: 23|1@1+ (1,0) [0|0] "" X
 SG_ APS_w217_lcUnavailableSpeeding: 24|1@1+ (1,0) [0|0] "" X
 SG_ APS_w218_lcSpeedExceededLimit: 25|1@1+ (1,0) [0|0] "" X
 SG_ APS_w219_lcTempUnavailableSpeed: 26|1@1+ (1,0) [0|0] "" X
 SG_ APS_w220_lcTempUnavailableRoad: 27|1@1+ (1,0) [0|0] "" X
 SG_ APS_w221_accRadarBlind: 28|1@1+ (1,0) [0|0] "" X
 SG_ APS_w222_accCameraBlind: 29|1@1+ (1,0) [0|0] "" X
 SG_ APS_w223_accObjectInPath: 30|1@1+ (1,0) [0|0] "" X
 SG_ APS_w224_accCameraCalibration: 31|1@1+ (1,0) [0|0] "" X
 SG_ APS_w225_lcDegradedVisSpeedLmt: 32|1@1+ (1,0) [0|0] "" X
 SG_ APS_w226_lcCamCalNeededSpeedLmt: 33|1@1+ (1,0) [0|0] "" X
 SG_ APS_w227_virtualWallBlocked: 34|1@1+ (1,0) [0|0] "" X
 SG_ APS_w228_DEPRECATED: 35|1@1+ (1,0) [0|0] "" X
 SG_ APS_w229_alcUltrasoundDamaged: 36|1@1+ (1,0) [0|0] "" X
 SG_ APS_w230_alcUltrasoundBlocked: 37|1@1+ (1,0) [0|0] "" X

BO_ 800 BMS_alertMatrix: 8 VEH
 SG_ BMS_matrixIndex M: 0|4@1+ (1,0) [0|0] "" X
 SG_ BMS_a017_SW_Brick_OV m0: 20|1@1+ (1,0) [0|0] "" X
 SG_ BMS_a018_SW_Brick_UV m0: 21|1@1+ (1,0) [0|0] "" X
 SG_ BMS_a019_SW_Module_OT m0: 22|1@1+ (1,0) [0|0] "" X
 SG_ BMS_a021_SW_Dr_Limits_Regulation m0: 24|1@1+ (1,0) [0|0] "" X
 SG_ BMS_a022_SW_Over_Current m0: 25|1@1+ (1,0) [0|0] "" X
 SG_ BMS_a023_SW_Stack_OV m0: 26|1@1+ (1,0) [0|0] "" X
 SG_ BMS_a024_SW_Islanded_Brick m0: 27|1@1+ (1,0) [0|0] "" X
 SG_ BMS_a025_SW_PwrBalance_Anomaly m0: 28|1@1+ (1,0) [0|0] "" X
 SG_ BMS_a026_SW_HFCurrent_Anomaly m0: 29|1@1+ (1,0) [0|0] "" X
 SG_ BMS_a034_SW_Passive_Isolation m0: 37|1@1+ (1,0) [0|0] "" X
 SG_ BMS_a035_SW_Isolation m0: 38|1@1+ (1,0) [0|0] "" X
 SG_ BMS_a036_SW_HvpHvilFault m0: 39|1@1+ (1,0) [0|0] "" X
 SG_ BMS_a037_SW_Flood_Port_Open m0: 40|1@1+ (1,0) [0|0] "" X
 SG_ BMS_a039_SW_DC_Link_Over_Voltage m0: 42|1@1+ (1,0) [0|0] "" X
 SG_ BMS_a041_SW_Power_On_Reset m0: 44|1@1+ (1,0) [0|0] "" X
 SG_ BMS_a042_SW_MPU_Error m0: 45|1@1+ (1,0) [0|0] "" X
 SG_ BMS_a043_SW_Watch_Dog_Reset m0: 46|1@1+ (1,0) [0|0] "" X
 SG_ BMS_a044_SW_Assertion m0: 47|1@1+ (1,0) [0|0] "" X
 SG_ BMS_a045_SW_Exception m0: 48|1@1+ (1,0) [0|0] "" X
 SG_ BMS_a046_SW_Task_Stack_Usage m0: 49|1@1+ (1,0) [0|0] "" X
 SG_ BMS_a047_SW_Task_Stack_Overflow m0: 50|1@1+ (1,0) [0|0] "" X
 SG_ BMS_a048_SW_Log_Upload_Request m0: 51|1@1+ (1,0) [0|0] "" X
 SG_ BMS_a050_SW_Brick_Voltage_MIA m0: 53|1@1+ (1,0) [0|0] "" X
 SG_ BMS_a051_SW_HVC_Vref_Bad m0: 54|1@1+ (1,0) [0|0] "" X
 SG_ BMS_a052_SW_PCS_MIA m0: 55|1@1+ (1,0) [0|0] "" X
 SG_ BMS_a053_SW_ThermalModel_Sanity m0: 56|1@1+ (1,0) [0|0] "" X
 SG_ BMS_a054_SW_Ver_Supply_Fault m0: 57|1@1+ (1,0) [0|0] "" X
 SG_ BMS_a059_SW_Pack_Voltage_Sensing m0: 62|1@1+ (1,0) [0|0] "" X
 SG_ BMS_a060_SW_Leakage_Test_Failure m0: 63|1@1+ (1,0) [0|0] "" X
 SG_ BMS_a061_robinBrickOverVoltage m1: 4|1@1+ (1,0) [0|0] "" X
 SG_ BMS_a062_SW_BrickV_Imbalance m1: 5|1@1+ (1,0) [0|0] "" X
 SG_ BMS_a063_SW_ChargePort_Fault m1: 6|1@1+ (1,0) [0|0] "" X
 SG_ BMS_a064_SW_SOC_Imbalance m1: 7|1@1+ (1,0) [0|0] "" X
 SG_ BMS_a069_SW_Low_Power m1: 12|1@1+ (1,0) [0|0] "" X
 SG_ BMS_a071_SW_SM_TransCon_Not_Met m1: 14|1@1+ (1,0) [0|0] "" X
 SG_ BMS_a075_SW_Chg_Disable_Failure m1: 18|1@1+ (1,0) [0|0] "" X
 SG_ BMS_a076_SW_Dch_While_Charging m1: 19|1@1+ (1,0) [0|0] "" X
 SG_ BMS_a077_SW_Charger_Regulation m1: 20|1@1+ (1,0) [0|0] "" X
 SG_ BMS_a081_SW_Ctr_Close_Blocked m1: 24|1@1+ (1,0) [0|0] "" X
 SG_ BMS_a082_SW_Ctr_Force_Open m1: 25|1@1+ (1,0) [0|0] "" X
 SG_ BMS_a083_SW_Ctr_Close_Failure m1: 26|1@1+ (1,0) [0|0] "" X
 SG_ BMS_a084_SW_Sleep_Wake_Aborted m1: 27|1@1+ (1,0) [0|0] "" X
 SG_ BMS_a087_SW_Feim_Test_Blocked m1: 30|1@1+ (1,0) [0|0] "" X
 SG_ BMS_a088_SW_VcFront_MIA_InDrive m1: 31|1@1+ (1,0) [0|0] "" X
 SG_ BMS_a089_SW_VcFront_MIA m1: 32|1@1+ (1,0) [0|0] "" X
 SG_ BMS_a090_SW_Gateway_MIA m1: 33|1@1+ (1,0) [0|0] "" X
 SG_ BMS_a091_SW_ChargePort_MIA m1: 34|1@1+ (1,0) [0|0] "" X
 SG_ BMS_a092_SW_ChargePort_Mia_On_Hvs m1: 35|1@1+ (1,0) [0|0] "" X
 SG_ BMS_a094_SW_Drive_Inverter_MIA m1: 37|1@1+ (1,0) [0|0] "" X
 SG_ BMS_a099_SW_BMB_Communication m1: 42|1@1+ (1,0) [0|0] "" X
 SG_ BMS_a105_SW_One_Module_Tsense m1: 48|1@1+ (1,0) [0|0] "" X
 SG_ BMS_a106_SW_All_Module_Tsense m1: 49|1@1+ (1,0) [0|0] "" X
 SG_ BMS_a107_SW_Stack_Voltage_MIA m1: 50|1@1+ (1,0) [0|0] "" X
 SG_ BMS_a121_SW_NVRAM_Config_Error m2: 4|1@1+ (1,0) [0|0] "" X
 SG_ BMS_a122_SW_BMS_Therm_Irrational m2: 5|1@1+ (1,0) [0|0] "" X
 SG_ BMS_a123_SW_Internal_Isolation m2: 6|1@1+ (1,0) [0|0] "" X
 SG_ BMS_a127_SW_shunt_SNA m2: 10|1@1+ (1,0) [0|0] "" X
 SG_ BMS_a128_SW_shunt_MIA m2: 11|1@1+ (1,0) [0|0] "" X
 SG_ BMS_a129_SW_VSH_Failure m2: 12|1@1+ (1,0) [0|0] "" X
 SG_ BMS_a130_IO_CAN_Error m2: 13|1@1+ (1,0) [0|0] "" X
 SG_ BMS_a131_Bleed_FET_Failure m2: 14|1@1+ (1,0) [0|0] "" X
 SG_ BMS_a132_HW_BMB_OTP_Uncorrctbl m2: 15|1@1+ (1,0) [0|0] "" X
 SG_ BMS_a134_SW_Delayed_Ctr_Off m2: 17|1@1+ (1,0) [0|0] "" X
 SG_ BMS_a136_SW_Module_OT_Warning m2: 19|1@1+ (1,0) [0|0] "" X
 SG_ BMS_a137_SW_Brick_UV_Warning m2: 20|1@1+ (1,0) [0|0] "" X
 SG_ BMS_a138_SW_Brick_OV_Warning m2: 21|1@1+ (1,0) [0|0] "" X
 SG_ BMS_a139_SW_DC_Link_V_Irrational m2: 22|1@1+ (1,0) [0|0] "" X
 SG_ BMS_a141_SW_BMB_Status_Warning m2: 24|1@1+ (1,0) [0|0] "" X
 SG_ BMS_a144_Hvp_Config_Mismatch m2: 27|1@1+ (1,0) [0|0] "" X
 SG_ BMS_a145_SW_SOC_Change m2: 28|1@1+ (1,0) [0|0] "" X
 SG_ BMS_a146_SW_Brick_Overdischarged m2: 29|1@1+ (1,0) [0|0] "" X
 SG_ BMS_a149_SW_Missing_Config_Block m2: 32|1@1+ (1,0) [0|0] "" X
 SG_ BMS_a151_SW_external_isolation m2: 34|1@1+ (1,0) [0|0] "" X
 SG_ BMS_a156_SW_BMB_Vref_bad m2: 39|1@1+ (1,0) [0|0] "" X
 SG_ BMS_a157_SW_HVP_HVS_Comms m2: 40|1@1+ (1,0) [0|0] "" X
 SG_ BMS_a158_SW_HVP_HVI_Comms m2: 41|1@1+ (1,0) [0|0] "" X
 SG_ BMS_a159_SW_HVP_ECU_Error m2: 42|1@1+ (1,0) [0|0] "" X
 SG_ BMS_a161_SW_DI_Open_Request m2: 44|1@1+ (1,0) [0|0] "" X
 SG_ BMS_a162_SW_No_Power_For_Support m2: 45|1@1+ (1,0) [0|0] "" X
 SG_ BMS_a163_SW_Contactor_Mismatch m2: 46|1@1+ (1,0) [0|0] "" X
 SG_ BMS_a164_SW_Uncontrolled_Regen m2: 47|1@1+ (1,0) [0|0] "" X
 SG_ BMS_a165_SW_Pack_Partial_Weld m2: 48|1@1+ (1,0) [0|0] "" X
 SG_ BMS_a166_SW_Pack_Full_Weld m2: 49|1@1+ (1,0) [0|0] "" X
 SG_ BMS_a167_SW_FC_Partial_Weld m2: 50|1@1+ (1,0) [0|0] "" X
 SG_ BMS_a168_SW_FC_Full_Weld m2: 51|1@1+ (1,0) [0|0] "" X
 SG_ BMS_a169_SW_FC_Pack_Weld m2: 52|1@1+ (1,0) [0|0] "" X
 SG_ BMS_a170_SW_Limp_Mode m2: 53|1@1+ (1,0) [0|0] "" X
 SG_ BMS_a171_SW_Stack_Voltage_Sense m2: 54|1@1+ (1,0) [0|0] "" X
 SG_ BMS_a174_SW_Charge_Failure m2: 57|1@1+ (1,0) [0|0] "" X
 SG_ BMS_a176_SW_GracefulPowerOff m2: 59|1@1+ (1,0) [0|0] "" X
 SG_ BMS_a179_SW_Hvp_12V_Fault m2: 62|1@1+ (1,0) [0|0] "" X
 SG_ BMS_a180_SW_ECU_reset_blocked m2: 63|1@1+ (1,0) [0|0] "" X

BO_ 818 BMS_bmbMinMax: 6 VEH
 SG_ BMS_bmbMinMaxMultiplexer M: 0|2@1+ (1,0) [0|0] "" X
 SG_ BMS_thermistorNumTMax m0: 2|4@1+ (1,0) [0|0] "" X
 SG_ BMS_thermistorNumTMin m0: 8|4@1+ (1,0) [0|0] "" X
 SG_ BMS_thermistorTMax m0: 16|8@1+ (0.5,-40) [0|0] "DegC" X
 SG_ BMS_thermistorTMin m0: 24|8@1+ (0.5,-40) [0|0] "DegC" X
 SG_ BMS_modelTMax m0: 32|8@1+ (0.5,-40) [0|0] "DegC" X
 SG_ BMS_modelTMin m0: 40|8@1+ (0.5,-40) [0|0] "DegC" X
 SG_ BMS_brickVoltageMax m1: 2|12@1+ (0.002,0) [0|0] "V" X
 SG_ BMS_brickVoltageMin m1: 16|12@1+ (0.002,0) [0|0] "V" X
 SG_ BMS_brickNumVoltageMax m1: 32|7@1+ (1,1) [0|0] "" X
 SG_ BMS_brickNumVoltageMin m1: 40|7@1+ (1,1) [0|0] "" X

BO_ 690 BMS_chargerRequest: 3 VEH
 SG_ BMS_acChargeEnable: 17|1@1+ (1,0) [0|0] "" X
 SG_ BMS_acChargePowerRequest: 0|16@1+ (0.001,0) [0|0] "kW" X
 SG_ BMS_pcsClearFaultRequest: 16|1@1+ (1,0) [0|0] "" X

BO_ 722 BMS_driveLimits: 8 VEH
 SG_ BMS_maxBusVoltage: 16|16@1+ (0.01,0) [0|0] "V" X
 SG_ BMS_maxChargeCurrent: 32|14@1+ (0.1,0) [0|0] "A" X
 SG_ BMS_maxDischargeCurrent: 48|14@1+ (0.128,0) [0|0] "A" X
 SG_ BMS_minBusVoltage: 0|16@1+ (0.01,0) [0|0] "V" X

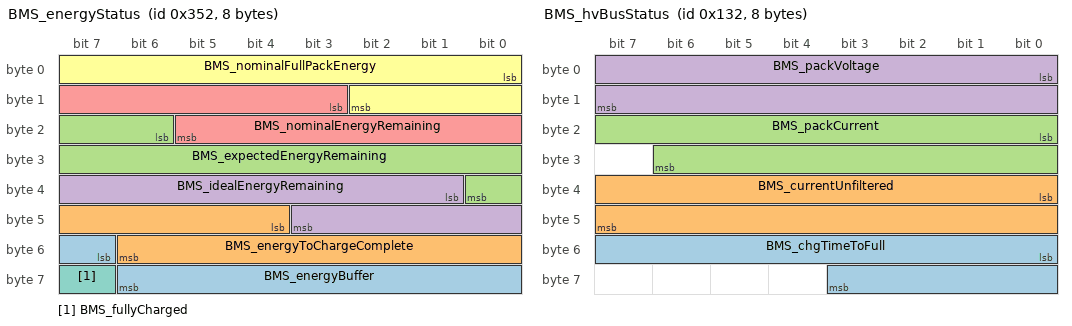
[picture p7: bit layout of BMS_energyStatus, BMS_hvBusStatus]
BO_ 850 BMS_energyStatus: 8 VEH
 SG_ BMS_energyBuffer: 55|8@1+ (0.1,0) [0|0] "KWh" X
 SG_ BMS_energyToChargeComplete: 44|11@1+ (0.1,0) [0|0] "KWh" X
 SG_ BMS_expectedEnergyRemaining: 22|11@1+ (0.1,0) [0|0] "KWh" X
 SG_ BMS_idealEnergyRemaining: 33|11@1+ (0.1,0) [0|0] "KWh" X
 SG_ BMS_nominalEnergyRemaining: 11|11@1+ (0.1,0) [0|0] "KWh" X
 SG_ BMS_nominalFullPackEnergy: 0|11@1+ (0.1,0) [0|0] "KWh" X
 SG_ BMS_fullyCharged : 63|1@1+ (1,0) [0|1] "" X

BO_ 306 BMS_hvBusStatus: 8 VEH
 SG_ BMS_chgTimeToFull: 48|12@1+ (0.0166667,0) [0|0] "Hours" X
 SG_ BMS_currentUnfiltered: 32|16@1- (-0.05,822) [0|0] "A" X
 SG_ BMS_packCurrent: 16|15@1- (-0.1,0) [0|0] "A" X
 SG_ BMS_packVoltage: 0|16@1+ (0.01,0) [0|0] "V" X

BO_ 768 BMS_info: 8 VEH
 SG_ BMS_infoIndex M: 0|8@1+ (1,0) [0|0] "" X
 SG_ BMS_buildType m10: 8|3@1+ (1,0) [0|0] "" X
 SG_ BMS_buildConfigId m10: 16|16@1+ (1,0) [0|0] "" X
 SG_ BMS_hardwareId m10: 32|16@1+ (1,0) [0|0] "" X
 SG_ BMS_componentId m10: 48|16@1+ (1,0) [0|0] "" X
 SG_ BMS_pcbaId m11: 16|8@1+ (1,0) [0|0] "" X
 SG_ BMS_assemblyId m11: 24|8@1+ (1,0) [0|0] "" X
 SG_ BMS_usageId m11: 32|16@1+ (1,0) [0|0] "" X
 SG_ BMS_subUsageId m11: 48|16@1+ (1,0) [0|0] "" X
 SG_ BMS_platformType m13: 8|8@1+ (1,0) [0|0] "" X
 SG_ BMS_appCrc m13: 32|32@1+ (1,0) [0|0] "" X
 SG_ BMS_appGitHash m17: 10|54@1+ (4,0) [0|0] "" X
 SG_ BMS_bootGitHash m18: 10|54@1+ (4,0) [0|0] "" X
 SG_ BMS_bootUdsProtoVersion m20: 8|8@1+ (1,0) [0|0] "" X
 SG_ BMS_bootCrc m20: 32|32@1+ (1,0) [0|0] "" X

BO_ 978 BMS_kwhCounter: 8 VEH
 SG_ BMS_kwhChargeTotal: 32|32@1+ (0.001,0) [0|0] "KWh" X
 SG_ BMS_kwhDischargeTotal: 0|32@1+ (0.001,0) [0|0] "KWh" X

BO_ 1010 BMS_kwhCountersMultiplexed: 8 VEH
 SG_ BMS_kwhCounter_Id M: 0|4@1+ (1,0) [0|0] "" X
 SG_ BMS_acChargerKwhTotal m0: 8|32@1+ (0.001,0) [0|0] "KWh" X
 SG_ BMS_dcChargerKwhTotal m1: 8|32@1+ (0.001,0) [0|0] "KWh" X
 SG_ BMS_kwhRegenChargeTotal m2: 8|32@1+ (0.001,0) [0|0] "KWh" X
 SG_ BMS_kwhDriveDischargeTotal m3: 8|32@1+ (0.001,0) [0|0] "KWh" X

BO_ 594 BMS_powerAvailable: 8 VEH
 SG_ BMS_hvacPowerBudget: 50|10@1+ (0.02,0) [0|0] "kW" X
 SG_ BMS_maxDischargePower: 16|16@1+ (0.01,0) [0|0] "kW" X
 SG_ BMS_maxRegenPower: 0|16@1+ (0.01,0) [0|0] "kW" X
 SG_ BMS_maxStationaryHeatPower: 32|10@1+ (0.01,0) [0|0] "kW" X
 SG_ BMS_powerLimitsState: 48|1@1+ (1,0) [0|0] "" X
 SG_ BMS_inverterTQF : 56|2@1+ (1,0) [0|3] "" X

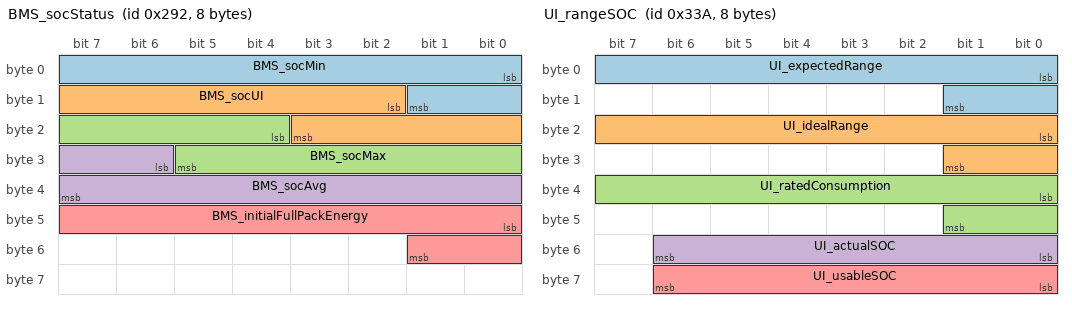
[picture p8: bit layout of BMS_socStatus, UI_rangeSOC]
BO_ 658 BMS_socStatus: 8 VEH
 SG_ BMS_socMin: 0|10@1+ (0.1,0) [0|0] "%" X
 SG_ BMS_socUI: 10|10@1+ (0.1,0) [0|0] "%" X
 SG_ BMS_socMax: 20|10@1+ (0.1,0) [0|0] "%" X
 SG_ BMS_socAvg: 30|10@1+ (0.1,0) [0|0] "%" X
 SG_ BMS_initialFullPackEnergy: 40|10@1+ (0.1,0) [0|102.3] "kWh" X

BO_ 826 UI_rangeSOC: 8 VEH
 SG_ UI_expectedRange : 0|10@1+ (1.6,0) [0|1023] "km" X
 SG_ UI_idealRange : 16|10@1+ (1.6,0) [0|1023] "km" X
 SG_ UI_ratedConsumption : 32|10@1+ (0.625,0) [0|1023] "Wh/km" X
 SG_ UI_actualSOC : 48|7@1+ (1,0) [0|127] "%" X
 SG_ UI_usableSOC : 56|7@1+ (1,0) [0|127] "%" X

BO_ 530 BMS_status: 8 VEH
 SG_ BMS_activeHeatingWorthwhile: 5|1@1+ (1,0) [0|0] "" X
 SG_ BMS_chargeRequest: 29|1@1+ (1,0) [0|0] "" X
 SG_ BMS_chargeRetryCount: 49|4@1+ (1,0) [0|0] "" X
 SG_ BMS_chgPowerAvailable: 38|11@1+ (0.125,0) [0|0] "kW" X
 SG_ BMS_contactorState: 8|3@1+ (1,0) [0|0] "" X
 SG_ BMS_cpMiaOnHvs: 6|1@1+ (1,0) [0|0] "" X
 SG_ BMS_diLimpRequest: 35|1@1+ (1,0) [0|0] "" X
 SG_ BMS_ecuLogUploadRequest: 54|2@1+ (1,0) [0|0] "" X
 SG_ BMS_hvState: 16|3@1+ (1,0) [0|0] "" X
 SG_ BMS_hvacPowerRequest: 0|1@1+ (1,0) [0|0] "" X
 SG_ BMS_isolationResistance: 19|10@1+ (10,0) [0|0] "kOhm" X
 SG_ BMS_keepWarmRequest: 30|1@1+ (1,0) [0|0] "" X
 SG_ BMS_minPackTemperature: 56|8@1+ (0.5,-40) [0|0] "DegC" X
 SG_ BMS_notEnoughPowerForDrive: 1|1@1+ (1,0) [0|0] "" X
 SG_ BMS_notEnoughPowerForSupport: 2|1@1+ (1,0) [0|0] "" X
 SG_ BMS_okToShipByAir: 36|1@1+ (1,0) [0|0] "" X
 SG_ BMS_okToShipByLand: 37|1@1+ (1,0) [0|0] "" X
 SG_ BMS_pcsPwmEnabled: 53|1@1+ (1,0) [0|0] "" X
 SG_ BMS_preconditionAllowed: 3|1@1+ (1,0) [0|0] "" X
 SG_ BMS_state: 11|4@1+ (1,0) [0|0] "" X
 SG_ BMS_uiChargeStatus: 32|3@1+ (1,0) [0|0] "" X
 SG_ BMS_updateAllowed: 4|1@1+ (1,0) [0|0] "" X

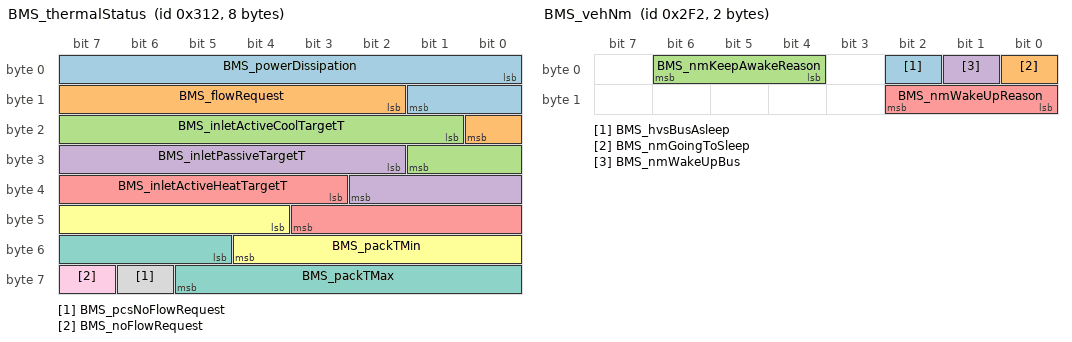
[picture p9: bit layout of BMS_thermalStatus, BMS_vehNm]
BO_ 786 BMS_thermalStatus: 8 VEH
 SG_ BMS_powerDissipation: 0|10@1+ (0.02,0) [0|0] "kW" X
 SG_ BMS_flowRequest: 10|7@1+ (0.3,0) [0|0] "LPM" X
 SG_ BMS_inletActiveCoolTargetT: 17|9@1+ (0.25,-25) [0|0] "DegC" X
 SG_ BMS_inletPassiveTargetT: 26|9@1+ (0.25,-25) [0|0] "DegC" X
 SG_ BMS_inletActiveHeatTargetT: 35|9@1+ (0.25,-25) [0|0] "DegC" X
 SG_ BMS_packTMin : 44|9@1+ (0.25,-25) [-25|100] "DegC" X
 SG_ BMS_packTMax : 53|9@1+ (0.25,-25) [-25|100] "DegC" X
 SG_ BMS_pcsNoFlowRequest: 62|1@1+ (1,0) [0|0] "" X
 SG_ BMS_noFlowRequest: 63|1@1+ (1,0) [0|0] "" X

BO_ 754 BMS_vehNm: 2 VEH
 SG_ BMS_hvsBusAsleep: 2|1@1+ (1,0) [0|0] "" X
 SG_ BMS_nmGoingToSleep: 0|1@1+ (1,0) [0|0] "" X
 SG_ BMS_nmKeepAwakeReason: 4|3@1+ (1,0) [0|0] "" X
 SG_ BMS_nmWakeUpBus: 1|1@1+ (1,0) [0|0] "" X
 SG_ BMS_nmWakeUpReason: 8|3@1+ (1,0) [0|0] "" X

BO_ 1132 CC_alertMatrix1: 8 VEH
 SG_ CC_a001_gndMonIntrptLineSide: 0|1@1+ (1,0) [0|0] "" X
 SG_ CC_a002_gndMonIntrptLoadSide: 1|1@1+ (1,0) [0|0] "" X
 SG_ CC_a003_CCIDTripped: 2|1@1+ (1,0) [0|0] "" X
 SG_ CC_a004_CCIDSelfTestFault: 3|1@1+ (1,0) [0|0] "" X
 SG_ CC_a005_groundedNeutral: 4|1@1+ (1,0) [0|0] "" X
 SG_ CC_a006_inputOverCurrent: 5|1@1+ (1,0) [0|0] "" X
 SG_ CC_a007_inputOverVoltage: 6|1@1+ (1,0) [0|0] "" X
 SG_ CC_a008_inputUnderVoltage: 7|1@1+ (1,0) [0|0] "" X
 SG_ CC_a009_inputMiswired: 8|1@1+ (1,0) [0|0] "" X
 SG_ CC_a010_contactorWelded: 9|1@1+ (1,0) [0|0] "" X
 SG_ CC_a011_ambientOT: 10|1@1+ (1,0) [0|0] "" X
 SG_ CC_a012_wallPlugOT: 11|1@1+ (1,0) [0|0] "" X
 SG_ CC_a013_vehConnOT: 12|1@1+ (1,0) [0|0] "" X
 SG_ CC_a014_mcuSelfTestFault: 13|1@1+ (1,0) [0|0] "" X
 SG_ CC_a015_PilotAFault: 14|1@1+ (1,0) [0|0] "" X
 SG_ CC_a016_PilotBFault: 15|1@1+ (1,0) [0|0] "" X
 SG_ CC_a017_PilotCFault: 16|1@1+ (1,0) [0|0] "" X
 SG_ CC_a018_PilotDFault: 17|1@1+ (1,0) [0|0] "" X
 SG_ CC_a019_proxDisconnected: 18|1@1+ (1,0) [0|0] "" X
 SG_ CC_a020_3vRailIncorrect: 19|1@1+ (1,0) [0|0] "" X
 SG_ CC_a021_CB_noMaster: 20|1@1+ (1,0) [0|0] "" X
 SG_ CC_a022_CB_tooManyMasters: 21|1@1+ (1,0) [0|0] "" X
 SG_ CC_a023_CB_tooManySlaves: 22|1@1+ (1,0) [0|0] "" X
 SG_ CC_a024_CB_masterISetTooLow: 23|1@1+ (1,0) [0|0] "" X
 SG_ CC_a025_evseTemp: 24|1@1+ (1,0) [0|0] "" X
 SG_ CC_a026_wallPlugTemp: 25|1@1+ (1,0) [0|0] "" X
 SG_ CC_a027_vehicleHandleTemp: 26|1@1+ (1,0) [0|0] "" X
 SG_ CC_a028_CB_rotarySelect: 27|1@1+ (1,0) [0|0] "" X
 SG_ CC_a029_PilotFFault: 28|1@1+ (1,0) [0|0] "" X
 SG_ CC_a030_masterSlaveMismatch: 29|1@1+ (1,0) [0|0] "" X

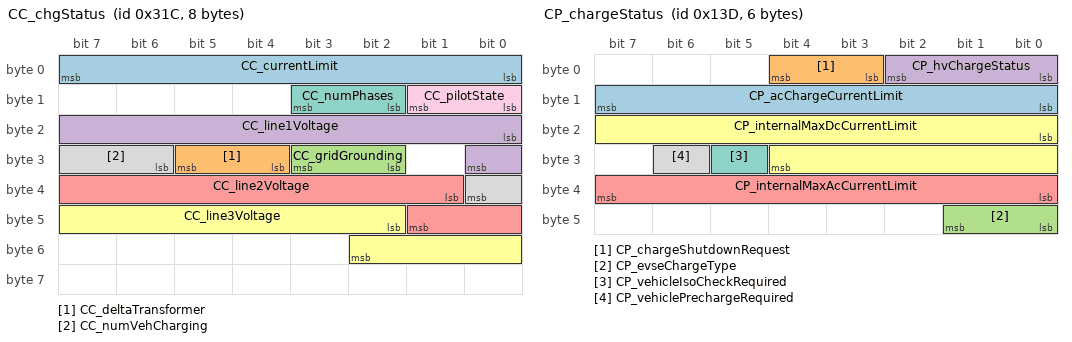
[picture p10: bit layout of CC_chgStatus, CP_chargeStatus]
BO_ 796 CC_chgStatus: 8 VEH
 SG_ CC_currentLimit: 0|8@1+ (0.5,0) [0|0] "A" X
 SG_ CC_deltaTransformer: 28|2@1+ (1,0) [0|0] "" X
 SG_ CC_gridGrounding: 26|2@1+ (1,0) [0|0] "" X
 SG_ CC_line1Voltage: 16|9@1+ (1,0) [0|0] "V" X
 SG_ CC_line2Voltage: 33|9@1+ (1,0) [0|0] "V" X
 SG_ CC_line3Voltage: 42|9@1+ (1,0) [0|0] "V" X
 SG_ CC_numPhases: 10|2@1+ (1,0) [0|0] "" X
 SG_ CC_numVehCharging: 30|3@1+ (1,0) [0|0] "" X
 SG_ CC_pilotState: 8|2@1+ (1,0) [0|0] "" X

BO_ 797 CC_chgStatus2: 8 VEH
 SG_ CC_chgStatus2Index M: 0|8@1+ (1,0) [0|0] "" X
 SG_ CC_buttonState m0: 8|1@1+ (1,0) [0|0] "" X

BO_ 812 CC_logData: 8 VEH
 SG_ CC_logIndex M: 0|8@1+ (1,0) [0|0] "" X
 SG_ CC_activeConnectorID m0: 8|8@1+ (1,0) [0|0] "" X
 SG_ CC_temperature1 m0: 16|8@1- (1,88) [0|0] "DegC" X
 SG_ CC_temperature2 m0: 24|8@1- (1,88) [0|0] "DegC" X
 SG_ CC_temperature3 m0: 32|8@1- (1,88) [0|0] "DegC" X
 SG_ CC_contactor1Closed m0: 40|2@1+ (1,0) [0|0] "" X
 SG_ CC_contactor2Closed m0: 42|2@1+ (1,0) [0|0] "" X
 SG_ CC_temperature4 m0: 44|8@1- (1,88) [0|0] "DegC" X
 SG_ CC_conn1Current m1: 8|8@1+ (0.5,0) [0|0] "A" X
 SG_ CC_conn2Current m2: 8|8@1+ (0.5,0) [0|0] "A" X
 SG_ CC_conn3Current m3: 8|8@1+ (0.5,0) [0|0] "A" X
 SG_ CC_conn4Current m4: 8|8@1+ (0.5,0) [0|0] "A" X
 SG_ CC_lifetimei2t m10: 32|32@1+ (0.1,0) [0|0] "A2h" X
 SG_ CC_lifetimeCtrCycles m11: 8|28@1+ (1,0) [0|0] "" X
 SG_ CC_lifetimeCtrCyclesLoaded m11: 36|28@1+ (1,0) [0|0] "" X
 SG_ CC_lifetimeAlertCount m12: 8|28@1+ (1,0) [0|0] "" X
 SG_ CC_lifetimVEHermalFoldbacks m12: 36|28@1+ (1,0) [0|0] "" X
 SG_ CC_lifetimeAvgStartupTemp m13: 36|28@1- (0.1,0) [0|0] "degC" X

BO_ 867 CMP_info: 8 VEH
 SG_ CMP_infoIndex M: 0|8@1+ (1,0) [0|0] "" X
 SG_ CMP_infoBuildType m10: 8|8@1+ (1,0) [0|0] "" X
 SG_ CMP_infoBuildConfigId m10: 16|16@1+ (1,0) [0|0] "" X
 SG_ CMP_infoHardwareId m10: 32|16@1+ (1,0) [0|0] "" X
 SG_ CMP_infoComponentId m10: 48|16@1+ (1,0) [0|0] "" X
 SG_ CMP_infoPcbaId m11: 16|8@1+ (1,0) [0|0] "" X
 SG_ CMP_infoAssemblyId m11: 24|8@1+ (1,0) [0|0] "" X
 SG_ CMP_infoUsageId m11: 32|16@1+ (1,0) [0|0] "" X
 SG_ CMP_infoSubUsageId m11: 48|16@1+ (1,0) [0|0] "" X
 SG_ CMP_infoBootUdsProtoVersion m20: 8|8@1+ (1,0) [0|0] "" X
 SG_ CMP_infoBootCrc m20: 32|32@1+ (1,0) [0|0] "" X
 SG_ CMP_infoPlatformType m13: 8|8@1+ (1,0) [0|0] "" X
 SG_ CMP_infoAppCrc m13: 32|32@1+ (1,0) [0|0] "" X

BO_ 798 CP_alertMatrix: 8 VEH
 SG_ CP_matrixIndex M: 0|4@1+ (1,0) [0|0] "" X
 SG_ CP_a001_canRx m0: 4|1@1+ (1,0) [0|0] "" X
 SG_ CP_a002_canTx m0: 5|1@1+ (1,0) [0|0] "" X
 SG_ CP_a003_canError m0: 6|1@1+ (1,0) [0|0] "" X
 SG_ CP_a004_proximityRationality m0: 7|1@1+ (1,0) [0|0] "" X
 SG_ CP_a005_gbdcLiveDisconnect m0: 8|1@1+ (1,0) [0|0] "" X
 SG_ CP_a006_lostCommsBMS m0: 9|1@1+ (1,0) [0|0] "" X
 SG_ CP_a007_watchdog m0: 10|1@1+ (1,0) [0|0] "" X
 SG_ CP_a008_memoryError m0: 11|1@1+ (1,0) [0|0] "" X
 SG_ CP_a009_coverOpen m0: 12|1@1+ (1,0) [0|0] "" X
 SG_ CP_a010_pilotRationality m0: 13|1@1+ (1,0) [0|0] "" X
 SG_ CP_a011_eeprom m0: 14|1@1+ (1,0) [0|0] "" X
 SG_ CP_a012_ledDriver m0: 15|1@1+ (1,0) [0|0] "" X
 SG_ CP_a013_lostCommsGTW m0: 16|1@1+ (1,0) [0|0] "" X
 SG_ CP_a014_lostCommsCHG m0: 17|1@1+ (1,0) [0|0] "" X
 SG_ CP_a015_apsVov m0: 18|1@1+ (1,0) [0|0] "" X
 SG_ CP_a016_apsVuv m0: 19|1@1+ (1,0) [0|0] "" X
 SG_ CP_a017_fiveVov m0: 20|1@1+ (1,0) [0|0] "" X
 SG_ CP_a018_fiveVuv m0: 21|1@1+ (1,0) [0|0] "" X
 SG_ CP_a019_threeVov m0: 22|1@1+ (1,0) [0|0] "" X
 SG_ CP_a020_threeVuv m0: 23|1@1+ (1,0) [0|0] "" X
 SG_ CP_a021_zeroVov m0: 24|1@1+ (1,0) [0|0] "" X
 SG_ CP_a022_zeroVuv m0: 25|1@1+ (1,0) [0|0] "" X
 SG_ CP_a023_gbdcSessionFailed m0: 26|1@1+ (1,0) [0|0] "" X
 SG_ CP_a024_ledsUC m0: 27|1@1+ (1,0) [0|0] "" X
 SG_ CP_a025_ledsOC m0: 28|1@1+ (1,0) [0|0] "" X
 SG_ CP_a026_networkManagement m0: 29|1@1+ (1,0) [0|0] "" X
 SG_ CP_a027_doorSensorOutOfSpec m0: 30|1@1+ (1,0) [0|0] "" X
 SG_ CP_a028_insertEnableMismatch m0: 31|1@1+ (1,0) [0|0] "" X
 SG_ CP_a029_doorClosedProxPilot m0: 32|1@1+ (1,0) [0|0] "" X
 SG_ CP_a030_busOff m0: 33|1@1+ (1,0) [0|0] "" X
 SG_ CP_a031_doorClosedCommandedOpen m0: 34|1@1+ (1,0) [0|0] "" X
 SG_ CP_a032_doorOpenExpectedClosed m0: 35|1@1+ (1,0) [0|0] "" X
 SG_ CP_a033_spiOpen m0: 36|1@1+ (1,0) [0|0] "" X
 SG_ CP_a034_calibrationIncomplete m0: 37|1@1+ (1,0) [0|0] "" X
 SG_ CP_a035_latchMovement_1 m0: 38|1@1+ (1,0) [0|0] "" X
 SG_ CP_a036_latchNotDisengaged m0: 39|1@1+ (1,0) [0|0] "" X
 SG_ CP_a037_latchNotEngaged m0: 40|1@1+ (1,0) [0|0] "" X
 SG_ CP_a038_latchNotBlocking m0: 41|1@1+ (1,0) [0|0] "" X
 SG_ CP_a039_latchMovement_2 m0: 42|1@1+ (1,0) [0|0] "" X
 SG_ CP_a040_doNotUse m0: 43|1@1+ (1,0) [0|0] "" X
 SG_ CP_a041_doorSensorUnplugged m0: 44|1@1+ (1,0) [0|0] "" X
 SG_ CP_a042_doorAssemblyBroken m0: 45|1@1+ (1,0) [0|0] "" X
 SG_ CP_a043_doorPotIrrational m0: 46|1@1+ (1,0) [0|0] "" X
 SG_ CP_a044_lostCommsHVP m0: 47|1@1+ (1,0) [0|0] "" X
 SG_ CP_a045_lostCommsVCSEC m0: 48|1@1+ (1,0) [0|0] "" X
 SG_ CP_a046_lostCommsEVSE m0: 49|1@1+ (1,0) [0|0] "" X
 SG_ CP_a047_lostCommsVCFRONT m0: 50|1@1+ (1,0) [0|0] "" X
 SG_ CP_a048_lostCommsUI m0: 51|1@1+ (1,0) [0|0] "" X
 SG_ CP_a049_multipleCablesDetected m0: 52|1@1+ (1,0) [0|0] "" X
 SG_ CP_a050_latchNotConnected m0: 53|1@1+ (1,0) [0|0] "" X
 SG_ CP_a051_doorInductiveSensorMIA m0: 54|1@1+ (1,0) [0|0] "" X
 SG_ CP_a052_evseNotSupported m0: 55|1@1+ (1,0) [0|0] "" X
 SG_ CP_a053_proxLatchedNoPilot m0: 56|1@1+ (1,0) [0|0] "" X
 SG_ CP_a054_cableNotSecured m0: 57|1@1+ (1,0) [0|0] "" X
 SG_ CP_a055_chargeStoppedNoPilot m0: 58|1@1+ (1,0) [0|0] "" X
 SG_ CP_a056_proxDisconnected m0: 59|1@1+ (1,0) [0|0] "" X
 SG_ CP_a057_evseFaulted m0: 60|1@1+ (1,0) [0|0] "" X
 SG_ CP_a058_acChargingBlocked m0: 61|1@1+ (1,0) [0|0] "" X
 SG_ CP_a059_swcanError m0: 62|1@1+ (1,0) [0|0] "" X
 SG_ CP_a060_lostCommsPCS m0: 63|1@1+ (1,0) [0|0] "" X
 SG_ CP_a061_uhfReceiverMIA m1: 4|1@1+ (1,0) [0|0] "" X
 SG_ CP_a062_scOutOfService m1: 5|1@1+ (1,0) [0|0] "" X
 SG_ CP_a063_scUpdateInProgress m1: 6|1@1+ (1,0) [0|0] "" X
 SG_ CP_a064_superchargingBlocked m1: 7|1@1+ (1,0) [0|0] "" X
 SG_ CP_a065_selfTestFailed m1: 8|1@1+ (1,0) [0|0] "" X
 SG_ CP_a066_proxLatchedIdlePilot m1: 9|1@1+ (1,0) [0|0] "" X
 SG_ CP_a067_gbdcConnFault m1: 10|1@1+ (1,0) [0|0] "" X
 SG_ CP_a068_doorSensorMismatch m1: 11|1@1+ (1,0) [0|0] "" X
 SG_ CP_a069_doorInductiveSensorError m1: 12|1@1+ (1,0) [0|0] "" X
 SG_ CP_a256_unused m1: 13|1@1+ (1,0) [0|0] "" X

BO_ 317 CP_chargeStatus: 6 VEH
 SG_ CP_acChargeCurrentLimit : 8|8@1+ (0.5,0) [0|127.5] "A"  Receiver
 SG_ CP_chargeShutdownRequest : 3|2@1+ (1,0) [0|2] ""  Receiver
 SG_ CP_evseChargeType : 40|2@1+ (1,0) [0|2] ""  Receiver
 SG_ CP_hvChargeStatus : 0|3@1+ (1,0) [0|6] ""  Receiver
 SG_ CP_internalMaxAcCurrentLimit : 32|8@1+ (0.5,0) [0|127.5] "A"  Receiver
 SG_ CP_internalMaxDcCurrentLimit : 16|13@1+ (0.146502,0) [0|1200] "A"  Receiver
 SG_ CP_vehicleIsoCheckRequired : 29|1@1+ (1,0) [0|1] ""  Receiver
 SG_ CP_vehiclePrechargeRequired : 30|1@1+ (1,0) [0|1] ""  Receiver

BO_ 541 CP_evseStatus: 8 VEH
 SG_ CP_acChargeRetriesExceeded: 41|1@1+ (1,0) [0|0] "" X
 SG_ CP_acChargeState: 60|2@1+ (1,0) [0|0] "" X
 SG_ CP_acNumRetries: 42|2@1+ (1,0) [0|0] "" X
 SG_ CP_cableCurrentLimit: 24|7@1+ (1,0) [0|0] "A" X
 SG_ CP_cableType: 16|3@1+ (1,0) [0|0] "" X
 SG_ CP_digitalCommsAttempts: 32|2@1+ (1,0) [0|0] "" X
 SG_ CP_digitalCommsEstablished: 37|1@1+ (1,0) [0|0] "" X
 SG_ CP_evseAccept: 0|1@1+ (1,0) [0|0] "" X
 SG_ CP_evseChargeType: 38|2@1+ (1,0) [0|0] "" X
 SG_ CP_evseRequest: 1|1@1+ (1,0) [0|0] "" X
 SG_ CP_gbState: 48|5@1+ (1,0) [0|0] "" X
 SG_ CP_gbdcChargeAttempts: 58|2@1+ (1,0) [0|0] "" X
 SG_ CP_gbdcFailureReason: 56|2@1+ (1,0) [0|0] "" X
 SG_ CP_gbdcStopChargeReason: 53|3@1+ (1,0) [0|0] "" X
 SG_ CP_lineVoltageRequested: 2|1@1+ (1,0) [0|0] "" X
 SG_ CP_pilot: 5|3@1+ (1,0) [0|0] "" X
 SG_ CP_pilotCurrent: 8|8@1+ (0.5,0) [0|0] "A" X
 SG_ CP_proximity: 3|2@1+ (1,0) [0|0] "" X
 SG_ CP_stopChargeRequest: 40|1@1+ (1,0) [0|0] "" X
 SG_ CP_teslaSwcanState: 34|3@1+ (1,0) [0|0] "" X
 SG_ CP_vehiclePrechargeRequired: 44|1@1+ (1,0) [0|0] "" X

BO_ 1342 CP_info: 8 VEH
 SG_ CP_infoIndex M: 0|8@1+ (1,0) [0|0] "" X
 SG_ CP_buildType m10: 8|3@1+ (1,0) [0|0] "" X
 SG_ CP_buildConfigId m10: 16|16@1+ (1,0) [0|0] "" X
 SG_ CP_hardwareId m10: 32|16@1+ (1,0) [0|0] "" X
 SG_ CP_componentId m10: 48|16@1+ (1,0) [0|0] "" X
 SG_ CP_pcbaId m11: 16|8@1+ (1,0) [0|0] "" X
 SG_ CP_assemblyId m11: 24|8@1+ (1,0) [0|0] "" X
 SG_ CP_usageId m11: 32|16@1+ (1,0) [0|0] "" X
 SG_ CP_subUsageId m11: 48|16@1+ (1,0) [0|0] "" X
 SG_ CP_platformType m13: 8|8@1+ (1,0) [0|0] "" X
 SG_ CP_appCrc m13: 32|32@1+ (1,0) [0|0] "" X
 SG_ CP_appGitHash m17: 10|54@1+ (4,0) [0|0] "" X
 SG_ CP_bootGitHash m18: 10|54@1+ (4,0) [0|0] "" X
 SG_ CP_bootUdsProtoVersion m20: 8|8@1+ (1,0) [0|0] "" X
 SG_ CP_bootCrc m20: 32|32@1+ (1,0) [0|0] "" X

BO_ 1885 CP_sensorData: 8 VEH
 SG_ CP_sensorDataSelect M : 0|4@1+ (1,0) [0|12] ""  Receiver
 SG_ CP_UHF_chipState m6 : 4|3@1+ (1,0) [0|7] ""  Receiver
 SG_ CP_UHF_fifoData m6 : 32|8@1+ (1,0) [0|255] ""  Receiver
 SG_ CP_UHF_rssi m6 : 8|8@1+ (1,0) [0|255] ""  Receiver
 SG_ CP_UHF_rxNumBytes m6 : 24|8@1+ (1,0) [0|255] ""  Receiver
 SG_ CP_UHF_rxOverflow m6 : 16|1@1+ (1,0) [0|1] ""  Receiver
 SG_ CP_UHF_selfTestRssi m6 : 40|8@1+ (1,0) [0|255] ""  Receiver
 SG_ CP_backCover2Counts m5 : 32|16@1+ (0.0015259,0) [0|100] "%"  Receiver
 SG_ CP_backCoverCounts m5 : 16|16@1+ (0.0015259,0) [0|100] "%"  Receiver
 SG_ CP_boardTemperature m1 : 32|8@1+ (1.29411764706,-50) [-50|280.0000000003] "C"  Receiver
 SG_ CP_doorCountsDebounced m0 : 24|16@1+ (0.00152590219,0) [0|100.00000002165] "%"  Receiver
 SG_ CP_doorCountsFiltered m0 : 8|16@1+ (0.00152590219,0) [0|100.00000002165] "%"  Receiver
 SG_ CP_doorI m2 : 16|12@1+ (0.0025,0) [0|10.2375] "A"  Receiver
 SG_ CP_doorLastRequestMaxI m2 : 28|12@1+ (0.0025,0) [0|10.2375] "A"  Receiver
 SG_ CP_doorPot m2 : 4|12@1+ (0.025,0) [0|100] "%"  Receiver
 SG_ CP_faultLineV m5 : 4|12@1+ (0.00114,0) [0|4.65524] "V"  Receiver
 SG_ CP_inductiveSensor_raw m4 : 4|28@1+ (1,0) [0|268435455] ""  Receiver
 SG_ CP_inlet1HarnessIdState m12 : 4|2@1+ (1,0) [0|2] ""  Receiver
 SG_ CP_inlet1HarnessIdValue m12 : 8|3@1+ (1,0) [0|7] ""  Receiver
 SG_ CP_inlet1HarnessV m12 : 16|14@1+ (0.001,0) [0|13.3] "V"  Receiver
 SG_ CP_inlet2HarnessIdState m12 : 30|2@1+ (1,0) [0|2] ""  Receiver
 SG_ CP_inlet2HarnessIdValue m12 : 32|3@1+ (1,0) [0|7] ""  Receiver
 SG_ CP_inlet2HarnessV m12 : 40|14@1+ (0.001,0) [0|13.3] "V"  Receiver
 SG_ CP_latch2I m3 : 16|12@1+ (0.0025,0) [0|10.2375] "A"  Receiver
 SG_ CP_latchI m3 : 4|12@1+ (0.0025,0) [0|10.2375] "A"  Receiver
 SG_ CP_pilotHighValue m9 : 40|12@1- (0.01,0) [-20.48|20.47] "V"  Receiver
 SG_ CP_pilotHighValue_intervalMax10s m10 : 28|12@1- (0.01,0) [-20.48|20.47] "V"  Receiver
 SG_ CP_pilotHighValue_intervalMin10s m10 : 40|12@1- (0.01,0) [-20.48|20.47] "V"  Receiver
 SG_ CP_pilotLowValue m9 : 28|12@1- (0.01,0) [-20.48|20.47] "V"  Receiver
 SG_ CP_pilotLowValue_intervalMax10s m10 : 4|12@1- (0.01,0) [-20.48|20.47] "V"  Receiver
 SG_ CP_pilotLowValue_intervalMin10s m10 : 16|12@1- (0.01,0) [-20.48|20.47] "V"  Receiver
 SG_ CP_pilotPeriod m9 : 16|12@1+ (1,0) [0|4095] ""  Receiver
 SG_ CP_pilotPulseWidth m9 : 4|12@1+ (1,0) [0|4095] ""  Receiver
 SG_ CP_pinTemperature1 m1 : 8|8@1+ (0.8039215686,-55) [-55|149.99] "C"  Receiver
 SG_ CP_pinTemperature2 m1 : 16|8@1+ (0.8039215686,-55) [-55|149.99] "C"  Receiver
 SG_ CP_pinTemperature3 m1 : 24|8@1+ (0.8039215686,-55) [-55|149.99] "C"  Receiver
 SG_ CP_proxConn1Sense m8 : 56|1@1+ (1,0) [0|1] ""  Receiver
 SG_ CP_proxEn m8 : 57|1@1+ (1,0) [0|1] ""  Receiver
 SG_ CP_proximityV m8 : 8|16@1+ (0.0001,0) [0|6.5535] "V"  Receiver
 SG_ CP_proximityV_GBCC1 m11 : 8|14@1+ (0.001,0) [0|13.3] "V"  Receiver
 SG_ CP_proximityV_GBCC2 m11 : 24|14@1+ (0.001,0) [0|13.3] "V"  Receiver
 SG_ CP_proximityV_intervalMax10s m8 : 40|16@1+ (0.0001,0) [0|6.5535] "V"  Receiver
 SG_ CP_proximityV_intervalMin10s m8 : 24|16@1+ (0.0001,0) [0|6.5535] "V"  Receiver
 SG_ CP_refVoltage m7 : 8|8@1+ (0.0070588235,0) [0|1.7999999925] "V"  Receiver

BO_ 605 CP_status: 8 VEH
 SG_ CP_UHF_controlState : 38|4@1+ (1,0) [0|10] ""  Receiver
 SG_ CP_UHF_handleFound : 42|1@1+ (1,0) [0|1] ""  Receiver
 SG_ CP_apsVoltage : 24|8@1+ (0.0715686,0) [0|18.249] "V" Vector__XXX
 SG_ CP_chargeCablePresent : 3|1@1+ (1,0) [0|1] ""  odin
 SG_ CP_chargeCableSecured : 4|1@1+ (1,0) [0|1] ""  Receiver
 SG_ CP_chargeCableState : 14|2@1+ (1,0) [0|2] ""  Receiver
 SG_ CP_chargeDoorOpen : 10|1@1+ (1,0) [0|1] ""  Receiver
 SG_ CP_chargeDoorOpenUI : 51|1@1+ (1,0) [0|1] ""  Receiver
 SG_ CP_coldWeatherMode : 60|1@1+ (1,0) [0|1] ""  Receiver
 SG_ CP_coverClosed : 63|1@1+ (1,0) [0|1] ""  Receiver
 SG_ CP_doorButtonPressed : 32|1@1+ (1,0) [0|1] ""  Receiver
 SG_ CP_doorControlState : 11|3@1+ (1,0) [0|6] ""  Receiver
 SG_ CP_doorOpenRequested : 43|1@1+ (1,0) [0|1] ""  Receiver
 SG_ CP_faultLineSensed : 44|1@1+ (1,0) [0|1] ""  Receiver
 SG_ CP_hvInletExposed : 61|1@1+ (1,0) [0|1] ""  Receiver
 SG_ CP_inductiveDoorState : 45|3@1+ (1,0) [0|7] ""  Receiver
 SG_ CP_inductiveSensorState : 48|3@1+ (1,0) [0|7] ""  Receiver
 SG_ CP_insertEnableLine : 2|1@1+ (1,0) [0|1] ""  Receiver
 SG_ CP_latch2ControlState : 19|3@1+ (1,0) [0|5] ""  Receiver
 SG_ CP_latch2State : 8|2@1+ (1,0) [0|3] ""  Receiver
 SG_ CP_latchControlState : 16|3@1+ (1,0) [0|5] ""  Receiver
 SG_ CP_latchEngaged : 62|1@1+ (1,0) [0|1] ""  Receiver
 SG_ CP_latchState : 5|2@1+ (1,0) [0|3] ""  Receiver
 SG_ CP_ledColor : 33|4@1+ (1,0) [0|10] ""  Receiver
 SG_ CP_numAlertsSet : 53|7@1+ (1,0) [0|127] ""  Receiver
 SG_ CP_permanentPowerRequest : 7|1@1+ (1,0) [0|1] ""  Receiver
 SG_ CP_swcanRelayClosed : 37|1@1+ (1,0) [0|1] ""  Receiver
 SG_ CP_type : 0|2@1+ (1,0) [0|3] ""  Receiver
 SG_ CP_vehicleUnlockRequest : 52|1@1+ (1,0) [0|1] ""  Receiver

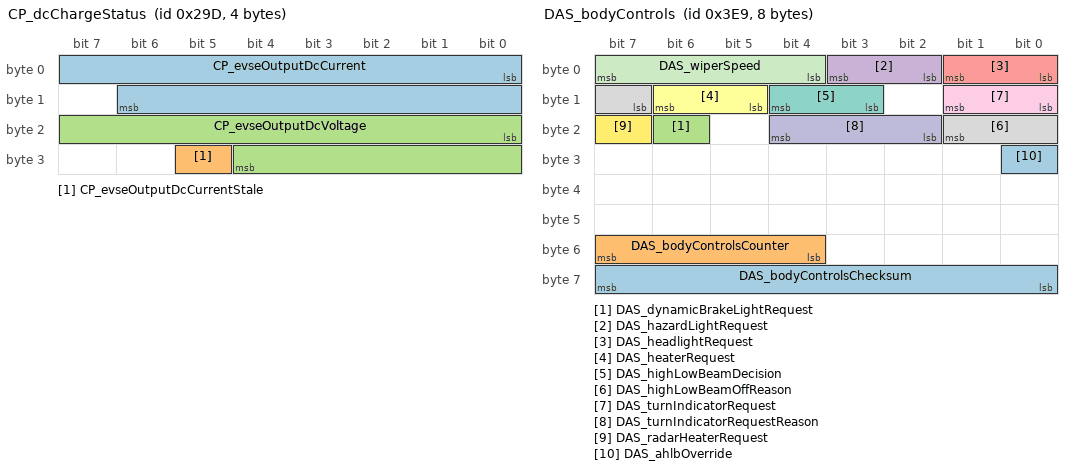
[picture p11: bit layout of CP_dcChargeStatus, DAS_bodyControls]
BO_ 669 CP_dcChargeStatus: 4 VEH
 SG_ CP_evseOutputDcCurrent : 0|15@1- (0.0732467,0) [-1200|1200] "A" X
 SG_ CP_evseOutputDcCurrentStale : 29|1@1+ (1,0) [0|1] "" X
 SG_ CP_evseOutputDcVoltage : 16|13@1+ (0.0732422,0) [0|599.927] "V" X

BO_ 583 DAS_autopilotDebug: 8 VEH
 SG_ DAS_autopilotAbortReason: 32|8@1+ (1,0) [0|255] "" X
 SG_ DAS_behaviorReport: 16|6@1+ (1,0) [0|43] "" X
 SG_ DAS_cameraContext: 30|2@1+ (1,0) [0|0] "" X
 SG_ DAS_constructionZone: 23|1@1+ (1,0) [0|0] "" X
 SG_ DAS_controlDistance: 24|6@1+ (2,0) [0|0] "m" X
 SG_ DAS_controlTarget: 12|1@1+ (1,0) [0|0] "" X
 SG_ DAS_controllerHealth: 21|2@1+ (1,0) [0|0] "" X
 SG_ DAS_controllerRef: 9|3@1+ (1,0) [0|0] "" X
 SG_ DAS_forkState: 45|5@1+ (1,0) [0|0] "" X
 SG_ DAS_laneChangeState: 50|6@1+ (1,0) [0|0] "" X
 SG_ DAS_lastWatchdogCode: 56|7@1+ (1,0) [0|0] "" X
 SG_ DAS_mapAvailability: 8|1@1+ (1,0) [0|0] "" X
 SG_ DAS_missionPlan: 0|2@1+ (1,0) [0|0] "" X
 SG_ DAS_roadEstimator: 0|2@1+ (1,0) [0|0] "" X
 SG_ DAS_arbiterBehavior : 2|3@1+ (1,0) [0|4] "" X
 SG_ DAS_rqstedBehaviorStatus: 40|5@1+ (1,0) [0|0] "" X

BO_ 1001 DAS_bodyControls: 8 VEH
 SG_ DAS_bodyControlsChecksum: 56|8@1+ (1,0) [0|0] "" X
 SG_ DAS_bodyControlsCounter: 52|4@1+ (1,0) [0|0] "" X
 SG_ DAS_dynamicBrakeLightRequest : 22|1@1+ (1,0) [0|1] "" X
 SG_ DAS_hazardLightRequest: 2|2@1+ (1,0) [0|0] "" X
 SG_ DAS_headlightRequest: 0|2@1+ (1,0) [0|0] "" X
 SG_ DAS_heaterRequest : 13|2@1+ (1,0) [0|2] "" X
 SG_ DAS_highLowBeamDecision: 11|2@1+ (1,0) [0|0] "" X
 SG_ DAS_highLowBeamOffReason: 15|3@1+ (1,0) [0|0] "" X
 SG_ DAS_turnIndicatorRequest: 8|2@1+ (1,0) [0|0] "" X
 SG_ DAS_turnIndicatorRequestReason: 18|3@1+ (1,0) [0|0] "" X
 SG_ DAS_wiperSpeed: 4|4@1+ (1,0) [0|0] "" X
 SG_ DAS_radarHeaterRequest : 23|1@1+ (1,0) [0|1] "" X
 SG_ DAS_ahlbOverride : 24|1@1+ (1,0) [0|1] "" X

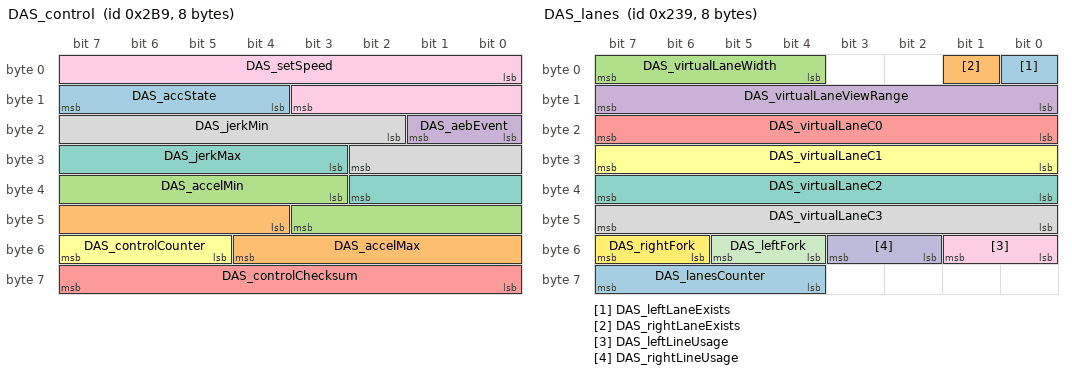
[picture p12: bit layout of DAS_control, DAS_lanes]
BO_ 697 DAS_control: 8 CH
 SG_ DAS_accState: 12|4@1+ (1,0) [0|0] "" X
 SG_ DAS_accelMax: 44|9@1+ (0.04,-15) [0|0] "m/s^2" X
 SG_ DAS_accelMin: 35|9@1+ (0.04,-15) [0|0] "m/s^2" X
 SG_ DAS_aebEvent: 16|2@1+ (1,0) [0|0] "" X
 SG_ DAS_controlChecksum: 56|8@1+ (1,0) [0|0] "" X
 SG_ DAS_controlCounter: 53|3@1+ (1,0) [0|0] "" X
 SG_ DAS_jerkMax: 27|8@1+ (0.034,0) [0|0] "m/s^3" X
 SG_ DAS_jerkMin: 18|9@1+ (0.018,-9.1) [0|0] "m/s^3" X
 SG_ DAS_setSpeed: 0|12@1+ (0.1,0) [0|0] "kph" X

BO_ 1337 DAS_info: 8 CH
 SG_ DAS_infoIndex M: 0|8@1+ (1,0) [0|0] "" X
 SG_ DAS_infoBuildType m10: 8|8@1+ (1,0) [0|0] "" X
 SG_ DAS_infoBuildConfigID m10: 16|16@1+ (1,0) [0|0] "" X
 SG_ DAS_infoHardwareID m10: 32|16@1+ (1,0) [0|0] "" X
 SG_ DAS_infoComponentID m10: 48|16@1+ (1,0) [0|0] "" X
 SG_ DAS_infoPcbaID m11: 16|8@1+ (1,0) [0|0] "" X
 SG_ DAS_infoAssemblyID m11: 24|8@1+ (1,0) [0|0] "" X
 SG_ DAS_infoUsageID m11: 32|16@1+ (1,0) [0|0] "" X
 SG_ DAS_infoSubUsageID m11: 48|16@1+ (1,0) [0|0] "" X
 SG_ DAS_infoApplicationCRC m13: 32|32@1+ (1,0) [0|0] "" X
 SG_ DAS_infoBootloaderSvnRevision m14: 8|24@1+ (1,0) [0|0] "" X
 SG_ DAS_infoEyeQBootCRC m16: 16|32@1+ (1,0) [0|0] "" X
 SG_ DAS_infoAppGitHashBytes m17: 10|54@1+ (4,0) [0|0] "" X
 SG_ DAS_infoBootGitHashBytes m18: 10|54@1+ (4,0) [0|0] "" X
 SG_ DAS_infoPlatformType m19: 8|8@1+ (1,0) [0|0] "" X
 SG_ DAS_infoMajorVersion m19: 16|8@1+ (1,0) [0|0] "" X
 SG_ DAS_infoBranchOrigin m19: 24|8@1+ (1,0) [0|0] "" X
 SG_ DAS_infoMaturity m19: 32|8@1+ (1,0) [0|0] "" X
 SG_ DAS_infoHardwareRevision m19: 40|8@1+ (1,0) [0|0] "" X
 SG_ DAS_infoBootUdsProtoVersion m20: 8|8@1+ (1,0) [0|0] "" X
 SG_ DAS_infoBootloaderCRC m20: 32|32@1+ (1,0) [0|0] "" X
 SG_ DAS_infoEyeQAppCRC m23: 16|32@1+ (1,0) [0|0] "" X
 SG_ DAS_infoEyeQFfsCRC m24: 16|32@1+ (1,0) [0|0] "" X

BO_ 569 DAS_lanes: 8 CH
 SG_ DAS_leftLaneExists: 0|1@1+ (1,0) [0|0] "" X
 SG_ DAS_rightLaneExists: 1|1@1+ (1,0) [0|0] "" X
 SG_ DAS_virtualLaneWidth: 4|4@1+ (0.3125,2) [0|0] "m" X
 SG_ DAS_virtualLaneViewRange: 8|8@1+ (1,0) [0|0] "m" X
 SG_ DAS_virtualLaneC0: 16|8@1+ (3.5,-350) [0|0] "cm" X
 SG_ DAS_virtualLaneC1: 24|8@1+ (0.092,-11.46) [0|0] "deg" X
 SG_ DAS_virtualLaneC2: 32|8@1+ (2e-05,-0.0025) [0|0] "m-1" X
 SG_ DAS_virtualLaneC3: 40|8@1+ (2.4e-07,-3e-05) [0|0] "m-2" X
 SG_ DAS_leftLineUsage: 48|2@1+ (1,0) [0|0] "" X
 SG_ DAS_rightLineUsage: 50|2@1+ (1,0) [0|0] "" X
 SG_ DAS_leftFork: 52|2@1+ (1,0) [0|0] "" X
 SG_ DAS_rightFork: 54|2@1+ (1,0) [0|0] "" X
 SG_ DAS_lanesCounter: 60|4@1+ (1,0) [0|0] "" X

BO_ 777 DAS_object: 8 CH
 SG_ DAS_objectId M: 0|3@1+ (1,0) [0|0] "" X
 SG_ DAS_leadVehType m0: 3|3@1+ (1,0) [0|0] "" X
 SG_ DAS_leadVehRelevantForControl m0: 7|1@1+ (1,0) [0|0] "" X
 SG_ DAS_leadVehDx m0: 8|8@1+ (0.5,0) [0|0] "m" X
 SG_ DAS_leadVehVxRel m0: 16|4@1+ (4,-30) [0|0] "m/s" X
 SG_ DAS_leadVehDy m0: 20|7@1+ (0.35,-22.05) [0|0] "m" X
 SG_ DAS_leadVehId m0: 27|7@1+ (1,0) [0|0] "" X
 SG_ DAS_leadVeh2Type m0: 34|3@1+ (1,0) [0|0] "" X
 SG_ DAS_leadVeh2RelevantForControl m0: 38|1@1+ (1,0) [0|0] "" X
 SG_ DAS_leadVeh2Dx m0: 39|8@1+ (0.5,0) [0|0] "m" X
 SG_ DAS_leadVeh2VxRel m0: 47|4@1+ (4,-30) [0|0] "m/s" X
 SG_ DAS_leadVeh2Dy m0: 51|7@1+ (0.35,-22.05) [0|0] "m" X
 SG_ DAS_leadVeh2Id m0: 58|6@1+ (1,0) [0|0] "" X
 SG_ DAS_leftVehType m1: 3|3@1+ (1,0) [0|0] "" X
 SG_ DAS_leftVehRelevantForControl m1: 7|1@1+ (1,0) [0|0] "" X
 SG_ DAS_leftVehDx m1: 8|8@1+ (0.5,0) [0|0] "m" X
 SG_ DAS_leftVehVxRel m1: 16|4@1+ (4,-30) [0|0] "m/s" X
 SG_ DAS_leftVehDy m1: 20|7@1+ (0.35,-22.05) [0|0] "m" X
 SG_ DAS_leftVehId m1: 27|7@1+ (1,0) [0|0] "" X
 SG_ DAS_leftVeh2Type m1: 34|3@1+ (1,0) [0|0] "" X
 SG_ DAS_leftVeh2RelevantForControl m1: 38|1@1+ (1,0) [0|0] "" X
 SG_ DAS_leftVeh2Dx m1: 39|8@1+ (0.5,0) [0|0] "m" X
 SG_ DAS_leftVeh2VxRel m1: 47|4@1+ (4,-30) [0|0] "m/s" X
 SG_ DAS_leftVeh2Dy m1: 51|7@1+ (0.35,-22.05) [0|0] "m" X
 SG_ DAS_leftVeh2Id m1: 58|6@1+ (1,0) [0|0] "" X
 SG_ DAS_rightVehType m2: 3|3@1+ (1,0) [0|0] "" X
 SG_ DAS_rightVehRelevantForControl m2: 7|1@1+ (1,0) [0|0] "" X
 SG_ DAS_rightVehDx m2: 8|8@1+ (0.5,0) [0|0] "m" X
 SG_ DAS_rightVehVxRel m2: 16|4@1+ (4,-30) [0|0] "m/s" X
 SG_ DAS_rightVehDy m2: 20|7@1+ (0.35,-22.05) [0|0] "m" X
 SG_ DAS_rightVehId m2: 27|7@1+ (1,0) [0|0] "" X
 SG_ DAS_rightVeh2Type m2: 34|3@1+ (1,0) [0|0] "" X
 SG_ DAS_rightVeh2RelevantForControl m2: 38|1@1+ (1,0) [0|0] "" X
 SG_ DAS_rightVeh2Dx m2: 39|8@1+ (0.5,0) [0|0] "m" X
 SG_ DAS_rightVeh2VxRel m2: 47|4@1+ (4,-30) [0|0] "m/s" X
 SG_ DAS_rightVeh2Dy m2: 51|7@1+ (0.35,-22.05) [0|0] "m" X
 SG_ DAS_rightVeh2Id m2: 58|6@1+ (1,0) [0|0] "" X
 SG_ DAS_cutinVehType m3: 3|3@1+ (1,0) [0|0] "" X
 SG_ DAS_cutinVehRelevantForControl m3: 7|1@1+ (1,0) [0|0] "" X
 SG_ DAS_cutinVehDx m3: 8|8@1+ (0.5,0) [0|0] "m" X
 SG_ DAS_cutinVehVxRel m3: 16|4@1+ (4,-30) [0|0] "m/s" X
 SG_ DAS_cutinVehDy m3: 20|7@1+ (0.35,-22.05) [0|0] "m" X
 SG_ DAS_cutinVehId m3: 27|7@1+ (1,0) [0|0] "" X
 SG_ DAS_roadSignColor m4: 3|3@1+ (1,0) [0|0] "" X
 SG_ DAS_roadSignId m4: 6|8@1+ (1,0) [0|0] "" X
 SG_ DAS_roadSignStopLineDist m4: 14|10@1+ (0.2,-20) [0|0] "m" X
 SG_ DAS_roadSignControlActive m4: 24|1@1+ (1,0) [0|0] "" X
 SG_ DAS_roadSignSource m4: 25|2@1+ (1,0) [0|0] "" X
 SG_ DAS_roadSignArrow m4: 27|3@1+ (1,0) [0|0] "" X
 SG_ DAS_roadSignOrientation m4: 30|2@1+ (1,0) [0|0] "" X
 SG_ DAS_leadVehHeading m5: 8|8@1+ (0.0245437,-3.14159) [0|0] "rad" X
 SG_ DAS_leadVeh2Heading m5: 16|8@1+ (0.0245437,-3.14159) [0|0] "rad" X
 SG_ DAS_leftVehHeading m5: 24|8@1+ (0.0245437,-3.14159) [0|0] "rad" X
 SG_ DAS_leftVeh2Heading m5: 32|8@1+ (0.0245437,-3.14159) [0|0] "rad" X
 SG_ DAS_rightVehHeading m5: 40|8@1+ (0.0245437,-3.14159) [0|0] "rad" X
 SG_ DAS_rightVeh2Heading m5: 48|8@1+ (0.0245437,-3.14159) [0|0] "rad" X
 SG_ DAS_cutinVehHeading m5: 56|8@1+ (0.0245437,-3.14159) [0|0] "rad" X

BO_ 921 DAS_status: 8 CH
 SG_ DAS_autoLaneChangeState: 46|5@1+ (1,0) [0|0] "" X
 SG_ DAS_autoParked: 25|1@1+ (1,0) [0|0] "" X
 SG_ DAS_autoparkReady: 24|1@1+ (1,0) [0|0] "" X
 SG_ DAS_autoparkWaitingForBrake: 26|1@1+ (1,0) [0|0] "" X
 SG_ DAS_autopilotHandsOnState: 42|4@1+ (1,0) [0|0] "" X
 SG_ DAS_autopilotState: 0|4@1+ (1,0) [0|0] "" X
 SG_ DAS_blindSpotRearLeft: 4|2@1+ (1,0) [0|0] "" X
 SG_ DAS_blindSpotRearRight: 6|2@1+ (1,0) [0|0] "" X
 SG_ DAS_csaState: 35|2@1+ (1,0) [0|0] "" X
 SG_ DAS_fleetSpeedState: 40|2@1+ (1,0) [0|0] "" X
 SG_ DAS_forwardCollisionWarning: 22|2@1+ (1,0) [0|0] "" X
 SG_ DAS_fusedSpeedLimit: 8|5@1+ (5,0) [0|0] "kph/mph" X
 SG_ DAS_heaterState: 21|1@1+ (1,0) [0|0] "" X
 SG_ DAS_laneDepartureWarning: 37|3@1+ (1,0) [0|0] "" X
 SG_ DAS_sideCollisionAvoid: 30|2@1+ (1,0) [0|0] "" X
 SG_ DAS_sideCollisionInhibit: 34|1@1+ (1,0) [0|0] "" X
 SG_ DAS_sideCollisionWarning: 32|2@1+ (1,0) [0|0] "" X
 SG_ DAS_statusChecksum: 56|8@1+ (1,0) [0|0] "" X
 SG_ DAS_statusCounter: 52|4@1+ (1,0) [0|0] "" X
 SG_ DAS_summonAvailable: 51|1@1+ (1,0) [0|0] "" X
 SG_ DAS_summonClearedGate: 15|1@1+ (1,0) [0|0] "" X
 SG_ DAS_summonFwdLeashReached: 28|1@1+ (1,0) [0|0] "" X
 SG_ DAS_summonObstacle: 14|1@1+ (1,0) [0|0] "" X
 SG_ DAS_summonRvsLeashReached: 29|1@1+ (1,0) [0|0] "" X
 SG_ DAS_suppressSpeedWarning: 13|1@1+ (1,0) [0|0] "" X
 SG_ DAS_visionOnlySpeedLimit: 16|5@1+ (5,0) [0|0] "kph/mph" X

BO_ 905 DAS_status2: 8 CH
 SG_ DAS_ACC_report: 26|5@1+ (1,0) [0|0] "" X
 SG_ DAS_accSpeedLimit: 0|10@1+ (0.2,0) [0|0] "mph" X
 SG_ DAS_activationFailureStatus: 14|2@1+ (1,0) [0|0] "" X
 SG_ DAS_driverInteractionLevel: 38|2@1+ (1,0) [0|0] "" X
 SG_ DAS_longCollisionWarning: 48|4@1+ (1,0) [0|0] "" X
 SG_ DAS_lssState: 31|3@1+ (1,0) [0|0] "" X
 SG_ DAS_pmmCameraFaultReason: 24|2@1+ (1,0) [0|0] "" X
 SG_ DAS_pmmLoggingRequest: 13|1@1+ (1,0) [0|0] "" X
 SG_ DAS_pmmObstacleSeverity: 10|3@1+ (1,0) [0|0] "" X
 SG_ DAS_pmmRadarFaultReason: 19|2@1+ (1,0) [0|0] "" X
 SG_ DAS_pmmSysFaultReason: 21|3@1+ (1,0) [0|0] "" X
 SG_ DAS_pmmUltrasonicsFaultReason: 16|3@1+ (1,0) [0|0] "" X
 SG_ DAS_ppOffsetDesiredRamp: 40|8@1+ (0.01,-1.28) [0|0] "m" X
 SG_ DAS_radarTelemetry: 34|2@1+ (1,0) [0|0] "" X
 SG_ DAS_robState: 36|2@1+ (1,0) [0|0] "" X
 SG_ DAS_status2Checksum: 56|8@1+ (1,0) [0|0] "" X
 SG_ DAS_status2Counter: 52|4@1+ (1,0) [0|0] "" X

BO_ 937 DAS_telemetry: 8 VEH
 SG_ DAS_telemetryMultiplexer M: 0|8@1+ (1,0) [0|0] "" X
 SG_ DAS_telLeftLaneType m0: 8|3@1+ (1,0) [0|0] "" X
 SG_ DAS_telRightLaneType m0: 11|3@1+ (1,0) [0|0] "" X
 SG_ DAS_telLeftMarkerQuality m0: 14|2@1+ (1,0) [0|0] "" X
 SG_ DAS_telRightMarkerQuality m0: 16|2@1+ (1,0) [0|0] "" X
 SG_ DAS_telLeftMarkerColor m0: 18|2@1+ (1,0) [0|0] "" X
 SG_ DAS_telRightMarkerColor m0: 20|2@1+ (1,0) [0|0] "" X
 SG_ DAS_telLeftLaneCrossing m0: 22|1@1+ (1,0) [0|0] "" X
 SG_ DAS_telRightLaneCrossing m0: 23|1@1+ (1,0) [0|0] "" X
 SG_ DAS_MCPObserved m1: 8|1@1+ (1,0) [0|0] "" X
 SG_ DAS_accReengaged m1: 9|1@1+ (1,0) [0|0] "" X
 SG_ DAS_pedestrianInFOVBeforeIntr m1: 10|1@1+ (1,0) [0|0] "" X
 SG_ DAS_pedestrianInFOVAfterIntr m1: 11|1@1+ (1,0) [0|0] "" X
 SG_ DAS_camFreeSpaceBeforeIntr m1: 12|1@1+ (1,0) [0|0] "" X
 SG_ DAS_camFreeSpaceAfterIntr m1: 13|1@1+ (1,0) [0|0] "" X
 SG_ DAS_timeOfIntervention m1: 14|6@1+ (0.25,0) [0|0] "s" X
 SG_ DAS_timeOfFirstPedestrian m1: 20|6@1+ (0.25,0) [0|0] "s" X
 SG_ DAS_timeOfACCReengaging m1: 26|6@1+ (0.25,0) [0|0] "s" X
 SG_ DAS_durationOfPrevACCStandstill m1: 32|6@1+ (0.5,0) [0|0] "s" X
 SG_ DAS_maxAbsSteeringWheelAngle m1: 38|7@1+ (2,0) [0|0] "degrees" X
 SG_ DAS_targetRelvelAtIntervention m1: 45|6@1+ (0.25,-2) [0|0] "m/s" X
 SG_ DAS_targetDistAtIntervention m1: 51|6@1+ (0.5,0) [0|0] "m" X
 SG_ DAS_egoSpeedAtIntervention m1: 57|6@1+ (0.5,0) [0|0] "m/s" X
 SG_ DAS_stopSignLongitudinalDist m2: 8|10@1+ (0.1,0) [0|0] "m" X
 SG_ DAS_stopSignLateralDist m2: 18|8@1+ (0.25,-32) [0|0] "m" X
 SG_ DAS_stopSignHeight m2: 26|6@1+ (0.1,0) [0|0] "m" X
 SG_ DAS_stopSignStopLineDistance m2: 32|10@1+ (0.1,-20) [0|0] "m" X
 SG_ DAS_stopSignCIPVDistance m2: 42|6@1+ (0.5,0) [0|0] "m" X
 SG_ DAS_stopSignHostAccel m2: 48|10@1+ (0.01,-5) [0|0] "m/s^2" X
 SG_ DAS_stopSignCrossingWarning m2: 58|1@1+ (1,0) [0|0] "" X
 SG_ DAS_stopSignIndex m2: 59|4@1+ (1,0) [0|0] "" X
 SG_ DAS_csaOverride m7: 10|1@1+ (1,0) [0|0] "" X
 SG_ DAS_csaIntState m7: 11|3@1+ (1,0) [0|0] "" X
 SG_ DAS_csaEnableSpeed m7: 14|12@1+ (0.05,-25) [0|0] "MPH" X
 SG_ DAS_csaDisableSpeed m7: 26|12@1+ (0.05,-25) [0|0] "MPH" X
 SG_ DAS_csaFiltCurv m7: 40|16@1- (1e-06,0) [0|0] "1/m" X
 SG_ DAS_csaMeasLatAccel m7: 56|8@1+ (0.08,-10.24) [0|0] "m/s^2" X
 SG_ DAS_soCamCipvStatus m8: 8|2@1+ (1,0) [0|0] "" X
 SG_ DAS_soRad5Status m8: 10|2@1+ (1,0) [0|0] "" X
 SG_ DAS_soRad1Status m8: 12|2@1+ (1,0) [0|0] "" X
 SG_ DAS_soCamCipvDx m8: 14|6@1+ (2,0) [0|0] "m" X
 SG_ DAS_soRad1Dx m8: 20|6@1+ (2,0) [0|0] "m" X
 SG_ DAS_soRad5Dx m8: 26|6@1+ (2,0) [0|0] "m" X
 SG_ DAS_soCamCipvDy m8: 32|5@1+ (0.4,-6.4) [0|0] "m" X
 SG_ DAS_soRad5Dy m8: 37|5@1+ (0.4,-6.4) [0|0] "m" X
 SG_ DAS_soCamCipvVx m8: 42|5@1+ (1,0) [0|0] "m/s" X
 SG_ DAS_soRad5ObstProb m8: 47|4@1+ (0.0625,0) [0|0] "probability" X
 SG_ DAS_soRad5Dz m8: 51|6@1+ (0.25,-5) [0|0] "m" X
 SG_ DAS_soRad5powerdB m8: 57|7@1+ (2,0) [0|0] "dB" X
 SG_ DAS_assPrevSetSpeed m9: 8|8@1+ (0.25,0) [0|0] "m/s" X
 SG_ DAS_assNewSetSpeed m9: 16|8@1+ (0.25,0) [0|0] "m/s" X
 SG_ DAS_assFusedSpeedLimit m9: 24|6@1+ (1,0) [0|0] "m/s" X
 SG_ DAS_assAutosteerActive m9: 30|1@1+ (1,0) [0|0] "" X
 SG_ DAS_assSmartSpeedActive m9: 31|1@1+ (1,0) [0|0] "" X

BO_ 986 DAS_telemetryEvent: 8 VEH
 SG_ DAS_TE_multiplexer M: 0|5@1+ (1,0) [0|0] "" X
 SG_ DAS_TE_counter m0: 5|3@1+ (1,0) [0|0] "" X
 SG_ DAS_TE_eventID m0: 8|16@1+ (1,0) [0|0] "" X
 SG_ DAS_TE_eventType m0: 24|6@1+ (1,0) [0|0] "" X
 SG_ DAS_TE_lcAbortReason m0: 32|5@1+ (1,0) [0|0] "" X
 SG_ DAS_TE_llCounter m1: 5|3@1+ (1,0) [0|0] "" X
 SG_ DAS_TE_llC0 m1: 8|10@1- (0.02,0) [0|0] "m" X
 SG_ DAS_TE_llC1 m1: 18|9@1- (0.00195313,0) [0|0] "rad" X
 SG_ DAS_TE_llC2 m1: 27|14@1- (4e-06,0) [0|0] "1/m" X
 SG_ DAS_TE_llC3 m1: 41|14@1- (1.6e-08,0) [0|0] "1/m2" X
 SG_ DAS_TE_llQlty m1: 55|1@1+ (1,0) [0|0] "" X
 SG_ DAS_TE_llRange m1: 56|7@1+ (1,0) [0|0] "m" X
 SG_ DAS_TE_llFuse m1: 63|1@1+ (1,0) [0|0] "" X
 SG_ DAS_TE_rlCounter m2: 5|3@1+ (1,0) [0|0] "" X
 SG_ DAS_TE_rlC0 m2: 8|10@1- (0.02,0) [0|0] "m" X
 SG_ DAS_TE_rlC1 m2: 18|9@1- (0.00195313,0) [0|0] "rad" X
 SG_ DAS_TE_rlC2 m2: 27|14@1- (4e-06,0) [0|0] "1/m" X
 SG_ DAS_TE_rlC3 m2: 41|14@1- (1.6e-08,0) [0|0] "1/m2" X
 SG_ DAS_TE_rlQlty m2: 55|1@1+ (1,0) [0|0] "" X
 SG_ DAS_TE_rlRange m2: 56|7@1+ (1,0) [0|0] "m" X
 SG_ DAS_TE_rlFuse m2: 63|1@1+ (1,0) [0|0] "" X
 SG_ DAS_TE_hppCounter m3: 5|3@1+ (1,0) [0|0] "" X
 SG_ DAS_TE_hppC0 m3: 8|10@1- (0.02,0) [0|0] "m" X
 SG_ DAS_TE_hppC1 m3: 18|9@1- (0.00195313,0) [0|0] "rad" X
 SG_ DAS_TE_hppC2 m3: 27|14@1- (4e-06,0) [0|0] "1/m" X
 SG_ DAS_TE_hppC3 m3: 41|14@1- (1.6e-08,0) [0|0] "1/m2" X
 SG_ DAS_TE_hppQlty m3: 55|1@1+ (1,0) [0|0] "" X
 SG_ DAS_TE_hppRange m3: 56|7@1+ (1,0) [0|0] "m" X
 SG_ DAS_TE_hppFuse m3: 63|1@1+ (1,0) [0|0] "" X
 SG_ DAS_TE_navCounter m4: 5|3@1+ (1,0) [0|0] "" X
 SG_ DAS_TE_navC0 m4: 8|10@1- (0.02,0) [0|0] "m" X
 SG_ DAS_TE_navC1 m4: 18|9@1- (0.00195313,0) [0|0] "rad" X
 SG_ DAS_TE_navC2 m4: 27|14@1- (4e-06,0) [0|0] "1/m" X
 SG_ DAS_TE_navC3 m4: 41|14@1- (1.6e-08,0) [0|0] "1/m2" X
 SG_ DAS_TE_navQlty m4: 55|1@1+ (1,0) [0|0] "" X
 SG_ DAS_TE_navRange m4: 56|7@1+ (1,0) [0|0] "m" X
 SG_ DAS_TE_navFuse m4: 63|1@1+ (1,0) [0|0] "" X
 SG_ DAS_TE_vlCounter m5: 5|3@1+ (1,0) [0|0] "" X
 SG_ DAS_TE_vlC0 m5: 8|10@1- (0.02,0) [0|0] "m" X
 SG_ DAS_TE_vlC1 m5: 18|9@1- (0.00195313,0) [0|0] "rad" X
 SG_ DAS_TE_vlC2 m5: 27|14@1- (4e-06,0) [0|0] "1/m" X
 SG_ DAS_TE_vlC3 m5: 41|14@1- (1.6e-08,0) [0|0] "1/m2" X
 SG_ DAS_TE_vlQlty m5: 55|1@1+ (1,0) [0|0] "" X
 SG_ DAS_TE_vlRange m5: 56|7@1+ (1,0) [0|0] "m" X
 SG_ DAS_TE_vlFuse m5: 63|1@1+ (1,0) [0|0] "" X
 SG_ DAS_TE_accCounter m6: 5|3@1+ (1,0) [0|0] "" X
 SG_ DAS_TE_accTargetDx m6: 8|6@1+ (2,0) [0|0] "m" X
 SG_ DAS_TE_accTargetDy m6: 14|6@1+ (0.2,-6.4) [0|0] "m" X
 SG_ DAS_TE_accTargetRelVel m6: 20|7@1- (0.25,-15.75) [0|0] "m/s" X
 SG_ DAS_TE_accTargetRelA m6: 27|5@1- (0.5,-7.5) [0|0] "m/s^2" X
 SG_ DAS_TE_accMinAccel m6: 32|5@1- (0.5,-7.5) [0|0] "m/s^2" X
 SG_ DAS_TE_accMinJ m6: 37|5@1- (0.5,-7.5) [0|0] "m/s^3" X
 SG_ DAS_TE_fcmCounter m7: 5|3@1+ (1,0) [0|0] "" X
 SG_ DAS_TE_fcmTargetDx m7: 8|8@1+ (0.25,0) [0|0] "m" X
 SG_ DAS_TE_fcmTargetDy m7: 16|5@1+ (0.2,-3.2) [0|0] "m" X
 SG_ DAS_TE_fcmTargetVRel m7: 21|7@1+ (0.25,-31.75) [0|0] "m/s" X
 SG_ DAS_TE_fcmTargetAccel m7: 28|5@1+ (0.5,-15.5) [0|0] "m/s^2" X
 SG_ DAS_TE_fcmTargetProb m7: 33|5@1+ (5,0) [0|0] "%" X
 SG_ DAS_TE_fcmDecelReqInstant m7: 38|7@1- (0.1,-6.3) [0|0] "m/s^2" X
 SG_ DAS_TE_fcmDecelReqAeb m7: 45|7@1- (0.1,-6.3) [0|0] "m/s^2" X
 SG_ DAS_TE_meAebFlag m7: 52|1@1+ (1,0) [0|0] "" X
 SG_ DAS_TE_ipsoCounter m8: 5|3@1+ (1,0) [0|0] "" X
 SG_ DAS_TE_ipsoValid m8: 8|1@1+ (1,0) [0|0] "" X
 SG_ DAS_TE_ipsoConfidence m8: 9|7@1+ (1,0) [0|0] "" X
 SG_ DAS_TE_ipsoDx m8: 16|6@1+ (2,0) [0|0] "m" X
 SG_ DAS_TE_ipsoDy m8: 22|6@1+ (0.1,-3.2) [0|0] "m" X
 SG_ DAS_TE_vlDyAtIpsoDx m8: 28|6@1+ (0.1,-3.2) [0|0] "m" X
 SG_ DAS_TE_swaProjection m8: 34|6@1+ (0.1,-3.2) [0|0] "m" X
 SG_ DAS_TE_ipsoIsTarget1 m8: 40|1@1+ (1,0) [0|0] "" X
 SG_ DAS_TE_ipsoIsTarget5 m8: 41|1@1+ (1,0) [0|0] "" X
 SG_ DAS_TE_restrictedAccess m8: 42|1@1+ (1,0) [0|0] "" X
 SG_ DAS_TE_csaOfframpValid m8: 43|1@1+ (1,0) [0|0] "" X
 SG_ DAS_TE_accControlType m8: 44|4@1+ (1,0) [0|0] "" X
 SG_ DAS_TE_brakeCapacityWarning m8: 48|1@1+ (1,0) [0|0] "" X
 SG_ DAS_TE_emergencyBrake m8: 49|1@1+ (1,0) [0|0] "" X
 SG_ DAS_TE_extendedAccLimits m8: 50|1@1+ (1,0) [0|0] "" X
 SG_ DAS_TE_crashFront m8: 51|1@1+ (1,0) [0|0] "" X
 SG_ DAS_TE_crashLeft m8: 52|1@1+ (1,0) [0|0] "" X
 SG_ DAS_TE_crashRear m8: 53|1@1+ (1,0) [0|0] "" X
 SG_ DAS_TE_crashRight m8: 54|1@1+ (1,0) [0|0] "" X
 SG_ DAS_TE_crashRollover m8: 55|1@1+ (1,0) [0|0] "" X
 SG_ DAS_TE_crashPedPro m8: 56|1@1+ (1,0) [0|0] "" X
 SG_ DAS_TE_meIpsoValid m8: 57|1@1+ (1,0) [0|0] "" X
 SG_ DAS_TE_robCounter m9: 5|3@1+ (1,0) [0|0] "" X
 SG_ DAS_TE_robExceptionStart m9: 16|8@1+ (1,-95) [0|0] "m" X
 SG_ DAS_TE_robExceptionEnd m9: 24|8@1+ (1,0) [0|0] "m" X
 SG_ DAS_TE_robDistanceEllipse m9: 32|8@1+ (0.5,0) [0|0] "m" X
 SG_ DAS_TE_robEllipseOverlap m9: 40|8@1+ (0.1,-12.5) [0|0] "m" X
 SG_ DAS_TE_robEllipseAge m9: 48|3@1+ (1,0) [0|0] "" X
 SG_ DAS_TE_robInfrastructure m9: 51|1@1+ (1,0) [0|0] "" X
 SG_ DAS_TE_robTrustRadarMap m9: 52|1@1+ (1,0) [0|0] "" X
 SG_ DAS_TE_robActiveBraking m9: 53|1@1+ (1,0) [0|0] "" X

BO_ 945 DAS_telemetryFurniture: 8 VEH
 SG_ DAS_TF_multiplexer M: 0|5@1+ (1,0) [0|0] "" X
 SG_ DAS_TF_furnitureIndex0 m0: 5|8@1+ (1,0) [0|0] "" X
 SG_ DAS_TF_distTraveled m0: 13|11@1+ (0.1,0) [0|0] "m" X
 SG_ DAS_TF_llType m0: 24|3@1+ (1,0) [0|0] "" X
 SG_ DAS_TF_rlType m0: 27|3@1+ (1,0) [0|0] "" X
 SG_ DAS_TF_cipvDist m0: 30|9@1+ (0.1,0) [0|0] "m" X
 SG_ DAS_TF_timeOfDay m0: 39|3@1+ (1,0) [0|0] "" X
 SG_ DAS_TF_furnitureType m0: 42|3@1+ (1,0) [0|0] "" X
 SG_ DAS_TF_furnitureIndex1 m1: 5|8@1+ (1,0) [0|0] "" X
 SG_ DAS_TF_longitudinalDist m1: 13|12@1+ (0.1,0) [0|0] "m" X
 SG_ DAS_TF_lateralDist m1: 25|12@1+ (0.1,-204.8) [0|0] "m" X
 SG_ DAS_TF_height m1: 37|12@1+ (0.05,0) [0|0] "m" X
 SG_ DAS_TF_color m1: 49|3@1+ (1,0) [0|0] "" X
 SG_ DAS_TF_shape m1: 52|3@1+ (1,0) [0|0] "" X
 SG_ DAS_TF_orientation m1: 55|2@1+ (1,0) [0|0] "" X
 SG_ DAS_TF_transmissionStatus m1: 57|2@1+ (1,0) [0|0] "" X
 SG_ DAS_TF_isMain m1: 59|1@1+ (1,0) [0|0] "" X
 SG_ DAS_TF_isTeslaMain m1: 60|1@1+ (1,0) [0|0] "" X
 SG_ DAS_TF_furnitureIndex2 m2: 5|8@1+ (1,0) [0|0] "" X
 SG_ DAS_TF_juncStatus m2: 13|4@1+ (1,0) [0|0] "" X
 SG_ DAS_TF_juncDist m2: 17|11@1+ (0.2,-20) [0|0] "m" X
 SG_ DAS_TF_stopLineDist m2: 28|11@1+ (0.1,-10) [0|0] "m" X
 SG_ DAS_TF_ttc m2: 39|7@1+ (0.1,0) [0|0] "s" X

BO_ 890 DAS_telemetryPeriodic: 8 VEH
 SG_ DAS_TP_multiplexer M: 0|5@1+ (1,0) [0|0] "" X
 SG_ DAS_TP_counter m0: 5|3@1+ (1,0) [0|0] "" X
 SG_ DAS_TP_vlWidth m0: 8|8@1+ (0.05,0) [0|0] "m" X
 SG_ DAS_TP_hppError m0: 16|6@1+ (0.05,0) [0|0] "m" X
 SG_ DAS_TP_wipersActive m0: 22|1@1+ (1,0) [0|0] "" X
 SG_ DAS_TP_handsOn m0: 23|1@1+ (1,0) [0|0] "" X
 SG_ DAS_TP_sonicDistL m0: 24|9@1+ (0.01,0) [0|0] "m" X
 SG_ DAS_TP_sonicDistR m0: 33|9@1+ (0.01,0) [0|0] "m" X
 SG_ DAS_TP_hppValid m0: 42|1@1+ (1,0) [0|0] "" X
 SG_ DAS_TP_restrictedAccess m0: 43|1@1+ (1,0) [0|0] "" X
 SG_ DAS_TP_vehFuse m0: 44|1@1+ (1,0) [0|0] "" X
 SG_ DAS_TP_accRestricted m0: 46|1@1+ (1,0) [0|0] "" X
 SG_ DAS_TP_laneChange m0: 48|2@1+ (1,0) [0|0] "" X
 SG_ DAS_TP_llType m0: 50|3@1+ (1,0) [0|0] "" X
 SG_ DAS_TP_rlType m0: 53|3@1+ (1,0) [0|0] "" X
 SG_ DAS_TP_plannerState m0: 56|4@1+ (1,0) [0|0] "" X
 SG_ DAS_TP_lcState m0: 60|4@1+ (1,0) [0|0] "" X
 SG_ DAS_TP_llCounter m1: 5|3@1+ (1,0) [0|0] "" X
 SG_ DAS_TP_llC0 m1: 8|10@1- (0.02,0) [0|0] "m" X
 SG_ DAS_TP_llC1 m1: 18|9@1- (0.00195313,0) [0|0] "rad" X
 SG_ DAS_TP_llC2 m1: 27|14@1- (4e-06,0) [0|0] "1/m" X
 SG_ DAS_TP_llC3 m1: 41|14@1- (1.6e-08,0) [0|0] "1/m2" X
 SG_ DAS_TP_llQlty m1: 55|1@1+ (1,0) [0|0] "" X
 SG_ DAS_TP_llRange m1: 56|7@1+ (1,0) [0|0] "m" X
 SG_ DAS_TP_llFuse m1: 63|1@1+ (1,0) [0|0] "" X
 SG_ DAS_TP_rlCounter m2: 5|3@1+ (1,0) [0|0] "" X
 SG_ DAS_TP_rlC0 m2: 8|10@1- (0.02,0) [0|0] "m" X
 SG_ DAS_TP_rlC1 m2: 18|9@1- (0.00195313,0) [0|0] "rad" X
 SG_ DAS_TP_rlC2 m2: 27|14@1- (4e-06,0) [0|0] "1/m" X
 SG_ DAS_TP_rlC3 m2: 41|14@1- (1.6e-08,0) [0|0] "1/m2" X
 SG_ DAS_TP_rlQlty m2: 55|1@1+ (1,0) [0|0] "" X
 SG_ DAS_TP_rlRange m2: 56|7@1+ (1,0) [0|0] "m" X
 SG_ DAS_TP_rlFuse m2: 63|1@1+ (1,0) [0|0] "" X
 SG_ DAS_TP_hppCounter m3: 5|3@1+ (1,0) [0|0] "" X
 SG_ DAS_TP_hppC0 m3: 8|10@1- (0.02,0) [0|0] "m" X
 SG_ DAS_TP_hppC1 m3: 18|9@1- (0.00195313,0) [0|0] "rad" X
 SG_ DAS_TP_hppC2 m3: 27|14@1- (4e-06,0) [0|0] "1/m" X
 SG_ DAS_TP_hppC3 m3: 41|14@1- (1.6e-08,0) [0|0] "1/m2" X
 SG_ DAS_TP_hppQlty m3: 55|1@1+ (1,0) [0|0] "" X
 SG_ DAS_TP_hppRange m3: 56|7@1+ (1,0) [0|0] "m" X
 SG_ DAS_TP_hppFuse m3: 63|1@1+ (1,0) [0|0] "" X
 SG_ DAS_TP_navCounter m4: 5|3@1+ (1,0) [0|0] "" X
 SG_ DAS_TP_navC0 m4: 8|10@1- (0.02,0) [0|0] "m" X
 SG_ DAS_TP_navC1 m4: 18|9@1- (0.00195313,0) [0|0] "rad" X
 SG_ DAS_TP_navC2 m4: 27|14@1- (4e-06,0) [0|0] "1/m" X
 SG_ DAS_TP_navC3 m4: 41|14@1- (1.6e-08,0) [0|0] "1/m2" X
 SG_ DAS_TP_navQlty m4: 55|1@1+ (1,0) [0|0] "" X
 SG_ DAS_TP_navRange m4: 56|7@1+ (1,0) [0|0] "m" X
 SG_ DAS_TP_navFuse m4: 63|1@1+ (1,0) [0|0] "" X
 SG_ DAS_TP_vlCounter m5: 5|3@1+ (1,0) [0|0] "" X
 SG_ DAS_TP_vlC0 m5: 8|10@1- (0.02,0) [0|0] "m" X
 SG_ DAS_TP_vlC1 m5: 18|9@1- (0.00195313,0) [0|0] "rad" X
 SG_ DAS_TP_vlC2 m5: 27|14@1- (4e-06,0) [0|0] "1/m" X
 SG_ DAS_TP_vlC3 m5: 41|14@1- (1.6e-08,0) [0|0] "1/m2" X
 SG_ DAS_TP_vlQlty m5: 55|1@1+ (1,0) [0|0] "" X
 SG_ DAS_TP_vlRange m5: 56|7@1+ (1,0) [0|0] "m" X
 SG_ DAS_TP_vlFuse m5: 63|1@1+ (1,0) [0|0] "" X
 SG_ DAS_TP_bdlCounter m6: 5|3@1+ (1,0) [0|0] "" X
 SG_ DAS_TP_bdlC0 m6: 8|10@1- (0.02,0) [0|0] "m" X
 SG_ DAS_TP_bdlC1 m6: 18|9@1- (0.00195313,0) [0|0] "rad" X
 SG_ DAS_TP_bdlC2 m6: 27|14@1- (4e-06,0) [0|0] "1/m" X
 SG_ DAS_TP_bdlC3 m6: 41|14@1- (1.6e-08,0) [0|0] "1/m2" X
 SG_ DAS_TP_bdlQlty m6: 55|1@1+ (1,0) [0|0] "" X
 SG_ DAS_TP_bdlRange m6: 56|7@1+ (1,0) [0|0] "m" X
 SG_ DAS_TP_bdlFuse m6: 63|1@1+ (1,0) [0|0] "" X
 SG_ DAS_TP_bdrCounter m7: 5|3@1+ (1,0) [0|0] "" X
 SG_ DAS_TP_bdrC0 m7: 8|10@1- (0.02,0) [0|0] "m" X
 SG_ DAS_TP_bdrC1 m7: 18|9@1- (0.00195313,0) [0|0] "rad" X
 SG_ DAS_TP_bdrC2 m7: 27|14@1- (4e-06,0) [0|0] "1/m" X
 SG_ DAS_TP_bdrC3 m7: 41|14@1- (1.6e-08,0) [0|0] "1/m2" X
 SG_ DAS_TP_bdrQlty m7: 55|1@1+ (1,0) [0|0] "" X
 SG_ DAS_TP_bdrRange m7: 56|7@1+ (1,0) [0|0] "m" X
 SG_ DAS_TP_bdrFuse m7: 63|1@1+ (1,0) [0|0] "" X
 SG_ DAS_TP_laneCounter m8: 5|3@1+ (1,0) [0|0] "" X
 SG_ DAS_TP_llSegQ1 m8: 8|4@1+ (10,0) [0|0] "%" X
 SG_ DAS_TP_llSegQ2 m8: 12|4@1+ (10,0) [0|0] "%" X
 SG_ DAS_TP_llSegQ3 m8: 16|4@1+ (10,0) [0|0] "%" X
 SG_ DAS_TP_llSegQ4 m8: 20|4@1+ (10,0) [0|0] "%" X
 SG_ DAS_TP_rlSegQ1 m8: 24|4@1+ (10,0) [0|0] "%" X
 SG_ DAS_TP_rlSegQ2 m8: 28|4@1+ (10,0) [0|0] "%" X
 SG_ DAS_TP_rlSegQ3 m8: 32|4@1+ (10,0) [0|0] "%" X
 SG_ DAS_TP_rlSegQ4 m8: 36|4@1+ (10,0) [0|0] "%" X
 SG_ DAS_TP_llExist m8: 40|4@1+ (10,0) [0|0] "%" X
 SG_ DAS_TP_rlExist m8: 44|4@1+ (10,0) [0|0] "%" X
 SG_ DAS_TP_nllProb m8: 48|4@1+ (0.1,0) [0|0] "1" X
 SG_ DAS_TP_nrlProb m8: 52|4@1+ (0.1,0) [0|0] "1" X
 SG_ DAS_TP_llQltyME m8: 56|2@1+ (1,0) [0|0] "" X
 SG_ DAS_TP_rlQltyME m8: 58|2@1+ (1,0) [0|0] "" X
 SG_ DAS_TP_bdlQltyME m8: 60|2@1+ (1,0) [0|0] "" X
 SG_ DAS_TP_bdrQltyME m8: 62|2@1+ (1,0) [0|0] "" X
 SG_ DAS_TP_llrCounter m9: 5|3@1+ (1,0) [0|0] "" X
 SG_ DAS_TP_numLanes m9: 8|3@1+ (1,0) [0|0] "" X
 SG_ DAS_TP_lane1LLR m9: 11|6@1+ (0.3125,-10) [0|0] "1" X
 SG_ DAS_TP_lane2LLR m9: 17|6@1+ (0.3125,-10) [0|0] "1" X
 SG_ DAS_TP_lane3LLR m9: 23|6@1+ (0.3125,-10) [0|0] "1" X
 SG_ DAS_TP_lane4LLR m9: 29|6@1+ (0.3125,-10) [0|0] "1" X
 SG_ DAS_TP_lane5LLR m9: 35|6@1+ (0.3125,-10) [0|0] "1" X
 SG_ DAS_TP_lane6LLR m9: 41|6@1+ (0.3125,-10) [0|0] "1" X
 SG_ DAS_TP_lane7LLR m9: 47|6@1+ (0.3125,-10) [0|0] "1" X
 SG_ DAS_TP_lane8LLR m9: 53|6@1+ (0.3125,-10) [0|0] "1" X
 SG_ DAS_TP_egoLane m9: 59|3@1+ (1,0) [0|0] "" X

BO_ 1548 DAS_telemetryRadar: 8 VEH
 SG_ DAS_TR_Counter: 54|2@1+ (1,0) [0|0] "" X
 SG_ DAS_TR_ObjIndex M: 0|5@1+ (1,0) [0|0] "" X
 SG_ DAS_TR_Obj00_Class m0: 5|3@1+ (1,0) [0|0] "" X
 SG_ DAS_TR_Obj00_Dx m0: 8|10@1+ (0.15625,0) [0|0] "m" X
 SG_ DAS_TR_Obj00_Dy m0: 18|6@1+ (0.5,-15.5) [0|0] "m" X
 SG_ DAS_TR_Obj00_Vx m0: 24|8@1+ (0.5,-63.5) [0|0] "m/s" X
 SG_ DAS_TR_Obj00_RCS m0: 32|8@1+ (0.25,-14) [0|0] "dB" X
 SG_ DAS_TR_Obj00_Length m0: 40|6@1+ (0.125,0) [0|0] "m" X
 SG_ DAS_TR_Obj00_MovingState m0: 46|2@1+ (1,0) [0|0] "" X
 SG_ DAS_TR_Obj00_Dz m0: 48|6@1+ (0.25,-5) [0|0] "m" X
 SG_ DAS_TR_Obj00_Exist m0: 56|5@1+ (3.125,0) [0|0] "%" X
 SG_ DAS_TR_Obj01_Class m1: 5|3@1+ (1,0) [0|0] "" X
 SG_ DAS_TR_Obj01_Dx m1: 8|10@1+ (0.15625,0) [0|0] "m" X
 SG_ DAS_TR_Obj01_Dy m1: 18|6@1+ (0.5,-15.5) [0|0] "m" X
 SG_ DAS_TR_Obj01_Vx m1: 24|8@1+ (0.5,-63.5) [0|0] "m/s" X
 SG_ DAS_TR_Obj01_RCS m1: 32|8@1+ (0.25,-14) [0|0] "dB" X
 SG_ DAS_TR_Obj01_Length m1: 40|6@1+ (0.125,0) [0|0] "m" X
 SG_ DAS_TR_Obj01_MovingState m1: 46|2@1+ (1,0) [0|0] "" X
 SG_ DAS_TR_Obj01_Dz m1: 48|6@1+ (0.25,-5) [0|0] "m" X
 SG_ DAS_TR_Obj01_Exist m1: 56|5@1+ (3.125,0) [0|0] "%" X
 SG_ DAS_TR_Obj02_Class m2: 5|3@1+ (1,0) [0|0] "" X
 SG_ DAS_TR_Obj02_Dx m2: 8|10@1+ (0.15625,0) [0|0] "m" X
 SG_ DAS_TR_Obj02_Dy m2: 18|6@1+ (0.5,-15.5) [0|0] "m" X
 SG_ DAS_TR_Obj02_Vx m2: 24|8@1+ (0.5,-63.5) [0|0] "m/s" X
 SG_ DAS_TR_Obj02_RCS m2: 32|8@1+ (0.25,-14) [0|0] "dB" X
 SG_ DAS_TR_Obj02_Length m2: 40|6@1+ (0.125,0) [0|0] "m" X
 SG_ DAS_TR_Obj02_MovingState m2: 46|2@1+ (1,0) [0|0] "" X
 SG_ DAS_TR_Obj02_Dz m2: 48|6@1+ (0.25,-5) [0|0] "m" X
 SG_ DAS_TR_Obj02_Exist m2: 56|5@1+ (3.125,0) [0|0] "%" X
 SG_ DAS_TR_Obj03_Class m3: 5|3@1+ (1,0) [0|0] "" X
 SG_ DAS_TR_Obj03_Dx m3: 8|10@1+ (0.15625,0) [0|0] "m" X
 SG_ DAS_TR_Obj03_Dy m3: 18|6@1+ (0.5,-15.5) [0|0] "m" X
 SG_ DAS_TR_Obj03_Vx m3: 24|8@1+ (0.5,-63.5) [0|0] "m/s" X
 SG_ DAS_TR_Obj03_RCS m3: 32|8@1+ (0.25,-14) [0|0] "dB" X
 SG_ DAS_TR_Obj03_Length m3: 40|6@1+ (0.125,0) [0|0] "m" X
 SG_ DAS_TR_Obj03_MovingState m3: 46|2@1+ (1,0) [0|0] "" X
 SG_ DAS_TR_Obj03_Dz m3: 48|6@1+ (0.25,-5) [0|0] "m" X
 SG_ DAS_TR_Obj03_Exist m3: 56|5@1+ (3.125,0) [0|0] "%" X
 SG_ DAS_TR_Obj04_Class m4: 5|3@1+ (1,0) [0|0] "" X
 SG_ DAS_TR_Obj04_Dx m4: 8|10@1+ (0.15625,0) [0|0] "m" X
 SG_ DAS_TR_Obj04_Dy m4: 18|6@1+ (0.5,-15.5) [0|0] "m" X
 SG_ DAS_TR_Obj04_Vx m4: 24|8@1+ (0.5,-63.5) [0|0] "m/s" X
 SG_ DAS_TR_Obj04_RCS m4: 32|8@1+ (0.25,-14) [0|0] "dB" X
 SG_ DAS_TR_Obj04_Length m4: 40|6@1+ (0.125,0) [0|0] "m" X
 SG_ DAS_TR_Obj04_MovingState m4: 46|2@1+ (1,0) [0|0] "" X
 SG_ DAS_TR_Obj04_Dz m4: 48|6@1+ (0.25,-5) [0|0] "m" X
 SG_ DAS_TR_Obj04_Exist m4: 56|5@1+ (3.125,0) [0|0] "%" X
 SG_ DAS_TR_Obj05_Class m5: 5|3@1+ (1,0) [0|0] "" X
 SG_ DAS_TR_Obj05_Dx m5: 8|10@1+ (0.15625,0) [0|0] "m" X
 SG_ DAS_TR_Obj05_Dy m5: 18|6@1+ (0.5,-15.5) [0|0] "m" X
 SG_ DAS_TR_Obj05_Vx m5: 24|8@1+ (0.5,-63.5) [0|0] "m/s" X
 SG_ DAS_TR_Obj05_RCS m5: 32|8@1+ (0.25,-14) [0|0] "dB" X
 SG_ DAS_TR_Obj05_Length m5: 40|6@1+ (0.125,0) [0|0] "m" X
 SG_ DAS_TR_Obj05_MovingState m5: 46|2@1+ (1,0) [0|0] "" X
 SG_ DAS_TR_Obj05_Dz m5: 48|6@1+ (0.25,-5) [0|0] "m" X
 SG_ DAS_TR_Obj05_Exist m5: 56|5@1+ (3.125,0) [0|0] "%" X
 SG_ DAS_TR_Obj06_Class m6: 5|3@1+ (1,0) [0|0] "" X
 SG_ DAS_TR_Obj06_Dx m6: 8|10@1+ (0.15625,0) [0|0] "m" X
 SG_ DAS_TR_Obj06_Dy m6: 18|6@1+ (0.5,-15.5) [0|0] "m" X
 SG_ DAS_TR_Obj06_Vx m6: 24|8@1+ (0.5,-63.5) [0|0] "m/s" X
 SG_ DAS_TR_Obj06_RCS m6: 32|8@1+ (0.25,-14) [0|0] "dB" X
 SG_ DAS_TR_Obj06_Length m6: 40|6@1+ (0.125,0) [0|0] "m" X
 SG_ DAS_TR_Obj06_MovingState m6: 46|2@1+ (1,0) [0|0] "" X
 SG_ DAS_TR_Obj06_Dz m6: 48|6@1+ (0.25,-5) [0|0] "m" X
 SG_ DAS_TR_Obj06_Exist m6: 56|5@1+ (3.125,0) [0|0] "%" X
 SG_ DAS_TR_Obj07_Class m7: 5|3@1+ (1,0) [0|0] "" X
 SG_ DAS_TR_Obj07_Dx m7: 8|10@1+ (0.15625,0) [0|0] "m" X
 SG_ DAS_TR_Obj07_Dy m7: 18|6@1+ (0.5,-15.5) [0|0] "m" X
 SG_ DAS_TR_Obj07_Vx m7: 24|8@1+ (0.5,-63.5) [0|0] "m/s" X
 SG_ DAS_TR_Obj07_RCS m7: 32|8@1+ (0.25,-14) [0|0] "dB" X
 SG_ DAS_TR_Obj07_Length m7: 40|6@1+ (0.125,0) [0|0] "m" X
 SG_ DAS_TR_Obj07_MovingState m7: 46|2@1+ (1,0) [0|0] "" X
 SG_ DAS_TR_Obj07_Dz m7: 48|6@1+ (0.25,-5) [0|0] "m" X
 SG_ DAS_TR_Obj07_Exist m7: 56|5@1+ (3.125,0) [0|0] "%" X
 SG_ DAS_TR_Obj08_Class m8: 5|3@1+ (1,0) [0|0] "" X
 SG_ DAS_TR_Obj08_Dx m8: 8|10@1+ (0.15625,0) [0|0] "m" X
 SG_ DAS_TR_Obj08_Dy m8: 18|6@1+ (0.5,-15.5) [0|0] "m" X
 SG_ DAS_TR_Obj08_Vx m8: 24|8@1+ (0.5,-63.5) [0|0] "m/s" X
 SG_ DAS_TR_Obj08_RCS m8: 32|8@1+ (0.25,-14) [0|0] "dB" X
 SG_ DAS_TR_Obj08_Length m8: 40|6@1+ (0.125,0) [0|0] "m" X
 SG_ DAS_TR_Obj08_MovingState m8: 46|2@1+ (1,0) [0|0] "" X
 SG_ DAS_TR_Obj08_Dz m8: 48|6@1+ (0.25,-5) [0|0] "m" X
 SG_ DAS_TR_Obj08_Exist m8: 56|5@1+ (3.125,0) [0|0] "%" X
 SG_ DAS_TR_Obj09_Class m9: 5|3@1+ (1,0) [0|0] "" X
 SG_ DAS_TR_Obj09_Dx m9: 8|10@1+ (0.15625,0) [0|0] "m" X
 SG_ DAS_TR_Obj09_Dy m9: 18|6@1+ (0.5,-15.5) [0|0] "m" X
 SG_ DAS_TR_Obj09_Vx m9: 24|8@1+ (0.5,-63.5) [0|0] "m/s" X
 SG_ DAS_TR_Obj09_RCS m9: 32|8@1+ (0.25,-14) [0|0] "dB" X
 SG_ DAS_TR_Obj09_Length m9: 40|6@1+ (0.125,0) [0|0] "m" X
 SG_ DAS_TR_Obj09_MovingState m9: 46|2@1+ (1,0) [0|0] "" X
 SG_ DAS_TR_Obj09_Dz m9: 48|6@1+ (0.25,-5) [0|0] "m" X
 SG_ DAS_TR_Obj09_Exist m9: 56|5@1+ (3.125,0) [0|0] "%" X
 SG_ DAS_TR_Obj10_Class m10: 5|3@1+ (1,0) [0|0] "" X
 SG_ DAS_TR_Obj10_Dx m10: 8|10@1+ (0.15625,0) [0|0] "m" X
 SG_ DAS_TR_Obj10_Dy m10: 18|6@1+ (0.5,-15.5) [0|0] "m" X
 SG_ DAS_TR_Obj10_Vx m10: 24|8@1+ (0.5,-63.5) [0|0] "m/s" X
 SG_ DAS_TR_Obj10_RCS m10: 32|8@1+ (0.25,-14) [0|0] "dB" X
 SG_ DAS_TR_Obj10_Length m10: 40|6@1+ (0.125,0) [0|0] "m" X
 SG_ DAS_TR_Obj10_MovingState m10: 46|2@1+ (1,0) [0|0] "" X
 SG_ DAS_TR_Obj10_Dz m10: 48|6@1+ (0.25,-5) [0|0] "m" X
 SG_ DAS_TR_Obj10_Exist m10: 56|5@1+ (3.125,0) [0|0] "%" X
 SG_ DAS_TR_Obj11_Class m11: 5|3@1+ (1,0) [0|0] "" X
 SG_ DAS_TR_Obj11_Dx m11: 8|10@1+ (0.15625,0) [0|0] "m" X
 SG_ DAS_TR_Obj11_Dy m11: 18|6@1+ (0.5,-15.5) [0|0] "m" X
 SG_ DAS_TR_Obj11_Vx m11: 24|8@1+ (0.5,-63.5) [0|0] "m/s" X
 SG_ DAS_TR_Obj11_RCS m11: 32|8@1+ (0.25,-14) [0|0] "dB" X
 SG_ DAS_TR_Obj11_Length m11: 40|6@1+ (0.125,0) [0|0] "m" X
 SG_ DAS_TR_Obj11_MovingState m11: 46|2@1+ (1,0) [0|0] "" X
 SG_ DAS_TR_Obj11_Dz m11: 48|6@1+ (0.25,-5) [0|0] "m" X
 SG_ DAS_TR_Obj11_Exist m11: 56|5@1+ (3.125,0) [0|0] "%" X
 SG_ DAS_TR_Obj12_Class m12: 5|3@1+ (1,0) [0|0] "" X
 SG_ DAS_TR_Obj12_Dx m12: 8|10@1+ (0.15625,0) [0|0] "m" X
 SG_ DAS_TR_Obj12_Dy m12: 18|6@1+ (0.5,-15.5) [0|0] "m" X
 SG_ DAS_TR_Obj12_Vx m12: 24|8@1+ (0.5,-63.5) [0|0] "m/s" X
 SG_ DAS_TR_Obj12_RCS m12: 32|8@1+ (0.25,-14) [0|0] "dB" X
 SG_ DAS_TR_Obj12_Length m12: 40|6@1+ (0.125,0) [0|0] "m" X
 SG_ DAS_TR_Obj12_MovingState m12: 46|2@1+ (1,0) [0|0] "" X
 SG_ DAS_TR_Obj12_Dz m12: 48|6@1+ (0.25,-5) [0|0] "m" X
 SG_ DAS_TR_Obj12_Exist m12: 56|5@1+ (3.125,0) [0|0] "%" X
 SG_ DAS_TR_Obj13_Class m13: 5|3@1+ (1,0) [0|0] "" X
 SG_ DAS_TR_Obj13_Dx m13: 8|10@1+ (0.15625,0) [0|0] "m" X
 SG_ DAS_TR_Obj13_Dy m13: 18|6@1+ (0.5,-15.5) [0|0] "m" X
 SG_ DAS_TR_Obj13_Vx m13: 24|8@1+ (0.5,-63.5) [0|0] "m/s" X
 SG_ DAS_TR_Obj13_RCS m13: 32|8@1+ (0.25,-14) [0|0] "dB" X
 SG_ DAS_TR_Obj13_Length m13: 40|6@1+ (0.125,0) [0|0] "m" X
 SG_ DAS_TR_Obj13_MovingState m13: 46|2@1+ (1,0) [0|0] "" X
 SG_ DAS_TR_Obj13_Dz m13: 48|6@1+ (0.25,-5) [0|0] "m" X
 SG_ DAS_TR_Obj13_Exist m13: 56|5@1+ (3.125,0) [0|0] "%" X
 SG_ DAS_TR_Obj14_Class m14: 5|3@1+ (1,0) [0|0] "" X
 SG_ DAS_TR_Obj14_Dx m14: 8|10@1+ (0.15625,0) [0|0] "m" X
 SG_ DAS_TR_Obj14_Dy m14: 18|6@1+ (0.5,-15.5) [0|0] "m" X
 SG_ DAS_TR_Obj14_Vx m14: 24|8@1+ (0.5,-63.5) [0|0] "m/s" X
 SG_ DAS_TR_Obj14_RCS m14: 32|8@1+ (0.25,-14) [0|0] "dB" X
 SG_ DAS_TR_Obj14_Length m14: 40|6@1+ (0.125,0) [0|0] "m" X
 SG_ DAS_TR_Obj14_MovingState m14: 46|2@1+ (1,0) [0|0] "" X
 SG_ DAS_TR_Obj14_Dz m14: 48|6@1+ (0.25,-5) [0|0] "m" X
 SG_ DAS_TR_Obj14_Exist m14: 56|5@1+ (3.125,0) [0|0] "%" X
 SG_ DAS_TR_Obj15_Class m15: 5|3@1+ (1,0) [0|0] "" X
 SG_ DAS_TR_Obj15_Dx m15: 8|10@1+ (0.15625,0) [0|0] "m" X
 SG_ DAS_TR_Obj15_Dy m15: 18|6@1+ (0.5,-15.5) [0|0] "m" X
 SG_ DAS_TR_Obj15_Vx m15: 24|8@1+ (0.5,-63.5) [0|0] "m/s" X
 SG_ DAS_TR_Obj15_RCS m15: 32|8@1+ (0.25,-14) [0|0] "dB" X
 SG_ DAS_TR_Obj15_Length m15: 40|6@1+ (0.125,0) [0|0] "m" X
 SG_ DAS_TR_Obj15_MovingState m15: 46|2@1+ (1,0) [0|0] "" X
 SG_ DAS_TR_Obj15_Dz m15: 48|6@1+ (0.25,-5) [0|0] "m" X
 SG_ DAS_TR_Obj15_Exist m15: 56|5@1+ (3.125,0) [0|0] "%" X
 SG_ DAS_TR_Obj16_Class m16: 5|3@1+ (1,0) [0|0] "" X
 SG_ DAS_TR_Obj16_Dx m16: 8|10@1+ (0.15625,0) [0|0] "m" X
 SG_ DAS_TR_Obj16_Dy m16: 18|6@1+ (0.5,-15.5) [0|0] "m" X
 SG_ DAS_TR_Obj16_Vx m16: 24|8@1+ (0.5,-63.5) [0|0] "m/s" X
 SG_ DAS_TR_Obj16_RCS m16: 32|8@1+ (0.25,-14) [0|0] "dB" X
 SG_ DAS_TR_Obj16_Length m16: 40|6@1+ (0.125,0) [0|0] "m" X
 SG_ DAS_TR_Obj16_MovingState m16: 46|2@1+ (1,0) [0|0] "" X
 SG_ DAS_TR_Obj16_Dz m16: 48|6@1+ (0.25,-5) [0|0] "m" X
 SG_ DAS_TR_Obj16_Exist m16: 56|5@1+ (3.125,0) [0|0] "%" X
 SG_ DAS_TR_Obj17_Class m17: 5|3@1+ (1,0) [0|0] "" X
 SG_ DAS_TR_Obj17_Dx m17: 8|10@1+ (0.15625,0) [0|0] "m" X
 SG_ DAS_TR_Obj17_Dy m17: 18|6@1+ (0.5,-15.5) [0|0] "m" X
 SG_ DAS_TR_Obj17_Vx m17: 24|8@1+ (0.5,-63.5) [0|0] "m/s" X
 SG_ DAS_TR_Obj17_RCS m17: 32|8@1+ (0.25,-14) [0|0] "dB" X
 SG_ DAS_TR_Obj17_Length m17: 40|6@1+ (0.125,0) [0|0] "m" X
 SG_ DAS_TR_Obj17_MovingState m17: 46|2@1+ (1,0) [0|0] "" X
 SG_ DAS_TR_Obj17_Dz m17: 48|6@1+ (0.25,-5) [0|0] "m" X
 SG_ DAS_TR_Obj17_Exist m17: 56|5@1+ (3.125,0) [0|0] "%" X
 SG_ DAS_TR_Obj18_Class m18: 5|3@1+ (1,0) [0|0] "" X
 SG_ DAS_TR_Obj18_Dx m18: 8|10@1+ (0.15625,0) [0|0] "m" X
 SG_ DAS_TR_Obj18_Dy m18: 18|6@1+ (0.5,-15.5) [0|0] "m" X
 SG_ DAS_TR_Obj18_Vx m18: 24|8@1+ (0.5,-63.5) [0|0] "m/s" X
 SG_ DAS_TR_Obj18_RCS m18: 32|8@1+ (0.25,-14) [0|0] "dB" X
 SG_ DAS_TR_Obj18_Length m18: 40|6@1+ (0.125,0) [0|0] "m" X
 SG_ DAS_TR_Obj18_MovingState m18: 46|2@1+ (1,0) [0|0] "" X
 SG_ DAS_TR_Obj18_Dz m18: 48|6@1+ (0.25,-5) [0|0] "m" X
 SG_ DAS_TR_Obj18_Exist m18: 56|5@1+ (3.125,0) [0|0] "%" X
 SG_ DAS_TR_Obj19_Class m19: 5|3@1+ (1,0) [0|0] "" X
 SG_ DAS_TR_Obj19_Dx m19: 8|10@1+ (0.15625,0) [0|0] "m" X
 SG_ DAS_TR_Obj19_Dy m19: 18|6@1+ (0.5,-15.5) [0|0] "m" X
 SG_ DAS_TR_Obj19_Vx m19: 24|8@1+ (0.5,-63.5) [0|0] "m/s" X
 SG_ DAS_TR_Obj19_RCS m19: 32|8@1+ (0.25,-14) [0|0] "dB" X
 SG_ DAS_TR_Obj19_Length m19: 40|6@1+ (0.125,0) [0|0] "m" X
 SG_ DAS_TR_Obj19_MovingState m19: 46|2@1+ (1,0) [0|0] "" X
 SG_ DAS_TR_Obj19_Dz m19: 48|6@1+ (0.25,-5) [0|0] "m" X
 SG_ DAS_TR_Obj19_Exist m19: 56|5@1+ (3.125,0) [0|0] "%" X
 SG_ DAS_TR_Obj20_Class m20: 5|3@1+ (1,0) [0|0] "" X
 SG_ DAS_TR_Obj20_Dx m20: 8|10@1+ (0.15625,0) [0|0] "m" X
 SG_ DAS_TR_Obj20_Dy m20: 18|6@1+ (0.5,-15.5) [0|0] "m" X
 SG_ DAS_TR_Obj20_Vx m20: 24|8@1+ (0.5,-63.5) [0|0] "m/s" X
 SG_ DAS_TR_Obj20_RCS m20: 32|8@1+ (0.25,-14) [0|0] "dB" X
 SG_ DAS_TR_Obj20_Length m20: 40|6@1+ (0.125,0) [0|0] "m" X
 SG_ DAS_TR_Obj20_MovingState m20: 46|2@1+ (1,0) [0|0] "" X
 SG_ DAS_TR_Obj20_Dz m20: 48|6@1+ (0.25,-5) [0|0] "m" X
 SG_ DAS_TR_Obj20_Exist m20: 56|5@1+ (3.125,0) [0|0] "%" X
 SG_ DAS_TR_Obj21_Class m21: 5|3@1+ (1,0) [0|0] "" X
 SG_ DAS_TR_Obj21_Dx m21: 8|10@1+ (0.15625,0) [0|0] "m" X
 SG_ DAS_TR_Obj21_Dy m21: 18|6@1+ (0.5,-15.5) [0|0] "m" X
 SG_ DAS_TR_Obj21_Vx m21: 24|8@1+ (0.5,-63.5) [0|0] "m/s" X
 SG_ DAS_TR_Obj21_RCS m21: 32|8@1+ (0.25,-14) [0|0] "dB" X
 SG_ DAS_TR_Obj21_Length m21: 40|6@1+ (0.125,0) [0|0] "m" X
 SG_ DAS_TR_Obj21_MovingState m21: 46|2@1+ (1,0) [0|0] "" X
 SG_ DAS_TR_Obj21_Dz m21: 48|6@1+ (0.25,-5) [0|0] "m" X
 SG_ DAS_TR_Obj21_Exist m21: 56|5@1+ (3.125,0) [0|0] "%" X
 SG_ DAS_TR_Obj22_Class m22: 5|3@1+ (1,0) [0|0] "" X
 SG_ DAS_TR_Obj22_Dx m22: 8|10@1+ (0.15625,0) [0|0] "m" X
 SG_ DAS_TR_Obj22_Dy m22: 18|6@1+ (0.5,-15.5) [0|0] "m" X
 SG_ DAS_TR_Obj22_Vx m22: 24|8@1+ (0.5,-63.5) [0|0] "m/s" X
 SG_ DAS_TR_Obj22_RCS m22: 32|8@1+ (0.25,-14) [0|0] "dB" X
 SG_ DAS_TR_Obj22_Length m22: 40|6@1+ (0.125,0) [0|0] "m" X
 SG_ DAS_TR_Obj22_MovingState m22: 46|2@1+ (1,0) [0|0] "" X
 SG_ DAS_TR_Obj22_Dz m22: 48|6@1+ (0.25,-5) [0|0] "m" X
 SG_ DAS_TR_Obj22_Exist m22: 56|5@1+ (3.125,0) [0|0] "%" X
 SG_ DAS_TR_Obj23_Class m23: 5|3@1+ (1,0) [0|0] "" X
 SG_ DAS_TR_Obj23_Dx m23: 8|10@1+ (0.15625,0) [0|0] "m" X
 SG_ DAS_TR_Obj23_Dy m23: 18|6@1+ (0.5,-15.5) [0|0] "m" X
 SG_ DAS_TR_Obj23_Vx m23: 24|8@1+ (0.5,-63.5) [0|0] "m/s" X
 SG_ DAS_TR_Obj23_RCS m23: 32|8@1+ (0.25,-14) [0|0] "dB" X
 SG_ DAS_TR_Obj23_Length m23: 40|6@1+ (0.125,0) [0|0] "m" X
 SG_ DAS_TR_Obj23_MovingState m23: 46|2@1+ (1,0) [0|0] "" X
 SG_ DAS_TR_Obj23_Dz m23: 48|6@1+ (0.25,-5) [0|0] "m" X
 SG_ DAS_TR_Obj23_Exist m23: 56|5@1+ (3.125,0) [0|0] "%" X
 SG_ DAS_TR_Obj24_Class m24: 5|3@1+ (1,0) [0|0] "" X
 SG_ DAS_TR_Obj24_Dx m24: 8|10@1+ (0.15625,0) [0|0] "m" X
 SG_ DAS_TR_Obj24_Dy m24: 18|6@1+ (0.5,-15.5) [0|0] "m" X
 SG_ DAS_TR_Obj24_Vx m24: 24|8@1+ (0.5,-63.5) [0|0] "m/s" X
 SG_ DAS_TR_Obj24_RCS m24: 32|8@1+ (0.25,-14) [0|0] "dB" X
 SG_ DAS_TR_Obj24_Length m24: 40|6@1+ (0.125,0) [0|0] "m" X
 SG_ DAS_TR_Obj24_MovingState m24: 46|2@1+ (1,0) [0|0] "" X
 SG_ DAS_TR_Obj24_Dz m24: 48|6@1+ (0.25,-5) [0|0] "m" X
 SG_ DAS_TR_Obj24_Exist m24: 56|5@1+ (3.125,0) [0|0] "%" X
 SG_ DAS_TR_Obj25_Class m25: 5|3@1+ (1,0) [0|0] "" X
 SG_ DAS_TR_Obj25_Dx m25: 8|10@1+ (0.15625,0) [0|0] "m" X
 SG_ DAS_TR_Obj25_Dy m25: 18|6@1+ (0.5,-15.5) [0|0] "m" X
 SG_ DAS_TR_Obj25_Vx m25: 24|8@1+ (0.5,-63.5) [0|0] "m/s" X
 SG_ DAS_TR_Obj25_RCS m25: 32|8@1+ (0.25,-14) [0|0] "dB" X
 SG_ DAS_TR_Obj25_Length m25: 40|6@1+ (0.125,0) [0|0] "m" X
 SG_ DAS_TR_Obj25_MovingState m25: 46|2@1+ (1,0) [0|0] "" X
 SG_ DAS_TR_Obj25_Dz m25: 48|6@1+ (0.25,-5) [0|0] "m" X
 SG_ DAS_TR_Obj25_Exist m25: 56|5@1+ (3.125,0) [0|0] "%" X
 SG_ DAS_TR_Obj26_Class m26: 5|3@1+ (1,0) [0|0] "" X
 SG_ DAS_TR_Obj26_Dx m26: 8|10@1+ (0.15625,0) [0|0] "m" X
 SG_ DAS_TR_Obj26_Dy m26: 18|6@1+ (0.5,-15.5) [0|0] "m" X
 SG_ DAS_TR_Obj26_Vx m26: 24|8@1+ (0.5,-63.5) [0|0] "m/s" X
 SG_ DAS_TR_Obj26_RCS m26: 32|8@1+ (0.25,-14) [0|0] "dB" X
 SG_ DAS_TR_Obj26_Length m26: 40|6@1+ (0.125,0) [0|0] "m" X
 SG_ DAS_TR_Obj26_MovingState m26: 46|2@1+ (1,0) [0|0] "" X
 SG_ DAS_TR_Obj26_Dz m26: 48|6@1+ (0.25,-5) [0|0] "m" X
 SG_ DAS_TR_Obj26_Exist m26: 56|5@1+ (3.125,0) [0|0] "%" X
 SG_ DAS_TR_Obj27_Class m27: 5|3@1+ (1,0) [0|0] "" X
 SG_ DAS_TR_Obj27_Dx m27: 8|10@1+ (0.15625,0) [0|0] "m" X
 SG_ DAS_TR_Obj27_Dy m27: 18|6@1+ (0.5,-15.5) [0|0] "m" X
 SG_ DAS_TR_Obj27_Vx m27: 24|8@1+ (0.5,-63.5) [0|0] "m/s" X
 SG_ DAS_TR_Obj27_RCS m27: 32|8@1+ (0.25,-14) [0|0] "dB" X
 SG_ DAS_TR_Obj27_Length m27: 40|6@1+ (0.125,0) [0|0] "m" X
 SG_ DAS_TR_Obj27_MovingState m27: 46|2@1+ (1,0) [0|0] "" X
 SG_ DAS_TR_Obj27_Dz m27: 48|6@1+ (0.25,-5) [0|0] "m" X
 SG_ DAS_TR_Obj27_Exist m27: 56|5@1+ (3.125,0) [0|0] "%" X
 SG_ DAS_TR_Obj28_Class m28: 5|3@1+ (1,0) [0|0] "" X
 SG_ DAS_TR_Obj28_Dx m28: 8|10@1+ (0.15625,0) [0|0] "m" X
 SG_ DAS_TR_Obj28_Dy m28: 18|6@1+ (0.5,-15.5) [0|0] "m" X
 SG_ DAS_TR_Obj28_Vx m28: 24|8@1+ (0.5,-63.5) [0|0] "m/s" X
 SG_ DAS_TR_Obj28_RCS m28: 32|8@1+ (0.25,-14) [0|0] "dB" X
 SG_ DAS_TR_Obj28_Length m28: 40|6@1+ (0.125,0) [0|0] "m" X
 SG_ DAS_TR_Obj28_MovingState m28: 46|2@1+ (1,0) [0|0] "" X
 SG_ DAS_TR_Obj28_Dz m28: 48|6@1+ (0.25,-5) [0|0] "m" X
 SG_ DAS_TR_Obj28_Exist m28: 56|5@1+ (3.125,0) [0|0] "%" X
 SG_ DAS_TR_Obj29_Class m29: 5|3@1+ (1,0) [0|0] "" X
 SG_ DAS_TR_Obj29_Dx m29: 8|10@1+ (0.15625,0) [0|0] "m" X
 SG_ DAS_TR_Obj29_Dy m29: 18|6@1+ (0.5,-15.5) [0|0] "m" X
 SG_ DAS_TR_Obj29_Vx m29: 24|8@1+ (0.5,-63.5) [0|0] "m/s" X
 SG_ DAS_TR_Obj29_RCS m29: 32|8@1+ (0.25,-14) [0|0] "dB" X
 SG_ DAS_TR_Obj29_Length m29: 40|6@1+ (0.125,0) [0|0] "m" X
 SG_ DAS_TR_Obj29_MovingState m29: 46|2@1+ (1,0) [0|0] "" X
 SG_ DAS_TR_Obj29_Dz m29: 48|6@1+ (0.25,-5) [0|0] "m" X
 SG_ DAS_TR_Obj29_Exist m29: 56|5@1+ (3.125,0) [0|0] "%" X
 SG_ DAS_TR_Obj30_Class m30: 5|3@1+ (1,0) [0|0] "" X
 SG_ DAS_TR_Obj30_Dx m30: 8|10@1+ (0.15625,0) [0|0] "m" X
 SG_ DAS_TR_Obj30_Dy m30: 18|6@1+ (0.5,-15.5) [0|0] "m" X
 SG_ DAS_TR_Obj30_Vx m30: 24|8@1+ (0.5,-63.5) [0|0] "m/s" X
 SG_ DAS_TR_Obj30_RCS m30: 32|8@1+ (0.25,-14) [0|0] "dB" X
 SG_ DAS_TR_Obj30_Length m30: 40|6@1+ (0.125,0) [0|0] "m" X
 SG_ DAS_TR_Obj30_MovingState m30: 46|2@1+ (1,0) [0|0] "" X
 SG_ DAS_TR_Obj30_Dz m30: 48|6@1+ (0.25,-5) [0|0] "m" X
 SG_ DAS_TR_Obj30_Exist m30: 56|5@1+ (3.125,0) [0|0] "%" X
 SG_ DAS_TR_Obj31_Class m31: 5|3@1+ (1,0) [0|0] "" X
 SG_ DAS_TR_Obj31_Dx m31: 8|10@1+ (0.15625,0) [0|0] "m" X
 SG_ DAS_TR_Obj31_Dy m31: 18|6@1+ (0.5,-15.5) [0|0] "m" X
 SG_ DAS_TR_Obj31_Vx m31: 24|8@1+ (0.5,-63.5) [0|0] "m/s" X
 SG_ DAS_TR_Obj31_RCS m31: 32|8@1+ (0.25,-14) [0|0] "dB" X
 SG_ DAS_TR_Obj31_Length m31: 40|6@1+ (0.125,0) [0|0] "m" X
 SG_ DAS_TR_Obj31_MovingState m31: 46|2@1+ (1,0) [0|0] "" X
 SG_ DAS_TR_Obj31_Dz m31: 48|6@1+ (0.25,-5) [0|0] "m" X
 SG_ DAS_TR_Obj31_Exist m31: 56|5@1+ (3.125,0) [0|0] "%" X

BO_ 586 DAS_visualDebug: 8 CH
 SG_ DAS_accSmartSpeedActive: 48|1@1+ (1,0) [0|0] "" X
 SG_ DAS_accSmartSpeedState: 49|3@1+ (1,0) [0|0] "" X
 SG_ DAS_autosteerBottsDotsUsage: 12|2@1+ (1,0) [0|0] "" X
 SG_ DAS_autosteerHPPUsage: 6|2@1+ (1,0) [0|0] "" X
 SG_ DAS_autosteerHealthAnomalyLevel: 18|3@1+ (1,0) [0|0] "" X
 SG_ DAS_autosteerHealthState: 21|3@1+ (1,0) [0|0] "" X
 SG_ DAS_autosteerModelUsage: 10|2@1+ (1,0) [0|0] "" X
 SG_ DAS_autosteerNavigationUsage: 8|2@1+ (1,0) [0|0] "" X
 SG_ DAS_autosteerVehiclesUsage: 4|2@1+ (1,0) [0|0] "" X
 SG_ DAS_behaviorType: 56|2@1+ (1,0) [0|0] "" X
 SG_ DAS_devAppInterfaceEnabled: 38|1@1+ (1,0) [0|0] "" X
 SG_ DAS_lastAutosteerAbortReason: 32|6@1+ (1,0) [0|0] "" X
 SG_ DAS_lastLinePreferenceReason: 24|4@1+ (1,0) [0|0] "" X
 SG_ DAS_navAvailable: 39|1@1+ (1,0) [0|0] "" X
 SG_ DAS_navDistance: 40|8@1+ (100,0) [0|0] "km" X
 SG_ DAS_offsetSide: 14|2@1+ (1,0) [0|0] "" X
 SG_ DAS_plannerState: 28|4@1+ (1,0) [0|0] "" X
 SG_ DAS_roadSurfaceType: 16|2@1+ (1,0) [0|0] "" X
 SG_ DAS_ulcInProgress: 52|1@1+ (1,0) [0|0] "" X
 SG_ DAS_ulcType: 58|1@1+ (1,0) [0|0] "" X

BO_ 810 DAS_warningMatrix0: 8 VEH
 SG_ DAS_w002_ldwDisabled: 1|1@1+ (1,0) [0|0] "" X
 SG_ DAS_w003_isaDisabled: 2|1@1+ (1,0) [0|0] "" X
 SG_ DAS_w004_accDisabled: 3|1@1+ (1,0) [0|0] "" X
 SG_ DAS_w005_fcwCancelled: 4|1@1+ (1,0) [0|0] "" X
 SG_ DAS_w006_aebCancelled: 5|1@1+ (1,0) [0|0] "" X
 SG_ DAS_w007_ahlbDisabled: 6|1@1+ (1,0) [0|0] "" X
 SG_ DAS_w008_parkDisabled: 7|1@1+ (1,0) [0|0] "" X
 SG_ DAS_w009_aebFault: 8|1@1+ (1,0) [0|0] "" X
 SG_ DAS_w010_radcCalibIssue: 9|1@1+ (1,0) [0|0] "" X
 SG_ DAS_w011_scaEvent: 10|1@1+ (1,0) [0|0] "" X
 SG_ DAS_w012_Cam_BootFailure: 11|1@1+ (1,0) [0|0] "" X
 SG_ DAS_w013_Cam_Watchdog: 12|1@1+ (1,0) [0|0] "" X
 SG_ DAS_w014_swAssert: 13|1@1+ (1,0) [0|0] "" X
 SG_ DAS_w015_Camera_Failsafes: 14|1@1+ (1,0) [0|0] "" X
 SG_ DAS_w016_aeb_e_event: 15|1@1+ (1,0) [0|0] "" X
 SG_ DAS_w017_Cam_Msg_MIA: 16|1@1+ (1,0) [0|0] "" X
 SG_ DAS_w018_ECU_Power_Issue: 17|1@1+ (1,0) [0|0] "" X
 SG_ DAS_w019_ECU_Stack_Overflow: 18|1@1+ (1,0) [0|0] "" X
 SG_ DAS_w020_ECU_checkstopError: 19|1@1+ (1,0) [0|0] "" X
 SG_ DAS_w021_ECU_Temperature_Issue: 20|1@1+ (1,0) [0|0] "" X
 SG_ DAS_w022_ECU_EEPROM_Failure: 21|1@1+ (1,0) [0|0] "" X
 SG_ DAS_w023_ECU_Cam_Statemismatc: 22|1@1+ (1,0) [0|0] "" X
 SG_ DAS_w024_ECU_Watchdog_Reset: 23|1@1+ (1,0) [0|0] "" X
 SG_ DAS_w025_LC_Steering_Override: 24|1@1+ (1,0) [0|0] "" X
 SG_ DAS_w026_ECU_timingIssue: 25|1@1+ (1,0) [0|0] "" X
 SG_ DAS_w027_ECU_Reset_Fault: 26|1@1+ (1,0) [0|0] "" X
 SG_ DAS_w028_spi_rx_error: 27|1@1+ (1,0) [0|0] "" X
 SG_ DAS_w029_spi_tx_error: 28|1@1+ (1,0) [0|0] "" X
 SG_ DAS_w030_Heater_Issue: 29|1@1+ (1,0) [0|0] "" X
 SG_ DAS_w031_canRxError: 30|1@1+ (1,0) [0|0] "" X
 SG_ DAS_w032_canTxError: 31|1@1+ (1,0) [0|0] "" X
 SG_ DAS_w033_gtwMia: 32|1@1+ (1,0) [0|0] "" X
 SG_ DAS_w034_sccmMia: 33|1@1+ (1,0) [0|0] "" X
 SG_ DAS_w035_espMia: 34|1@1+ (1,0) [0|0] "" X
 SG_ DAS_w036_bdyMia: 35|1@1+ (1,0) [0|0] "" X
 SG_ DAS_w037_camTacIssue: 36|1@1+ (1,0) [0|0] "" X
 SG_ DAS_w038_camFailure: 37|1@1+ (1,0) [0|0] "" X
 SG_ DAS_w039_sdm_rcm_Mia: 38|1@1+ (1,0) [0|0] "" X
 SG_ DAS_w040_autopilotAngleSaturated: 39|1@1+ (1,0) [0|0] "" X
 SG_ DAS_w041_autopilotRateSaturated: 40|1@1+ (1,0) [0|0] "" X
 SG_ DAS_w042_autopilotAborting: 41|1@1+ (1,0) [0|0] "" X
 SG_ DAS_w043_camLongRunTime: 42|1@1+ (1,0) [0|0] "" X
 SG_ DAS_w044_appMobileyeFailure: 43|1@1+ (1,0) [0|0] "" X
 SG_ DAS_w045_radMia: 44|1@1+ (1,0) [0|0] "" X
 SG_ DAS_w046_eepromRecordAbsent: 45|1@1+ (1,0) [0|0] "" X
 SG_ DAS_w047_edrEvent: 46|1@1+ (1,0) [0|0] "" X
 SG_ DAS_w048_DAS_Features_Disabled: 47|1@1+ (1,0) [0|0] "" X
 SG_ DAS_w049_eyeqVersionMismatch: 48|1@1+ (1,0) [0|0] "" X
 SG_ DAS_w050_aeb_event: 49|1@1+ (1,0) [0|0] "" X
 SG_ DAS_w051_radcEcuIssue: 50|1@1+ (1,0) [0|0] "" X
 SG_ DAS_w052_radcSensorIssue: 51|1@1+ (1,0) [0|0] "" X
 SG_ DAS_w053_radcCommIssue: 52|1@1+ (1,0) [0|0] "" X
 SG_ DAS_w054_camAutofix: 53|1@1+ (1,0) [0|0] "" X
 SG_ DAS_w055_radcVersionMismatch: 54|1@1+ (1,0) [0|0] "" X
 SG_ DAS_w056_diMia: 55|1@1+ (1,0) [0|0] "" X
 SG_ DAS_w057_mcuMia: 56|1@1+ (1,0) [0|0] "" X
 SG_ DAS_w058_epbMia: 57|1@1+ (1,0) [0|0] "" X
 SG_ DAS_w059_parkMia: 58|1@1+ (1,0) [0|0] "" X
 SG_ DAS_w060_fcw_event: 59|1@1+ (1,0) [0|0] "" X
 SG_ DAS_w061_airSuspensionMia: 60|1@1+ (1,0) [0|0] "" X
 SG_ DAS_w062_radcAlignment: 61|1@1+ (1,0) [0|0] "" X
 SG_ DAS_w063_parkVersionMismatch: 62|1@1+ (1,0) [0|0] "" X
 SG_ DAS_w064_epasMia: 63|1@1+ (1,0) [0|0] "" X

BO_ 874 DAS_warningMatrix1: 8 VEH
 SG_ DAS_w065_deserializerOvercurrent: 0|1@1+ (1,0) [0|0] "" X
 SG_ DAS_w066_deserializerLockLost: 1|1@1+ (1,0) [0|0] "" X
 SG_ DAS_w067_steeringAlignment: 2|1@1+ (1,0) [0|0] "" X
 SG_ DAS_w068_vlInconsistency: 3|1@1+ (1,0) [0|0] "" X
 SG_ DAS_w069_apcSpaceMasked: 4|1@1+ (1,0) [0|0] "" X
 SG_ DAS_w070_apcIncompleteCal: 5|1@1+ (1,0) [0|0] "" X
 SG_ DAS_w071_selfparkStarted: 6|1@1+ (1,0) [0|0] "" X
 SG_ DAS_w072_selfparkComplete: 7|1@1+ (1,0) [0|0] "" X
 SG_ DAS_w073_issueEscalatedLDW: 8|1@1+ (1,0) [0|0] "" X
 SG_ DAS_w074_inPathStationaryObst: 9|1@1+ (1,0) [0|0] "" X
 SG_ DAS_w075_scMia: 10|1@1+ (1,0) [0|0] "" X
 SG_ DAS_w076_mobilEyeSetC: 11|1@1+ (1,0) [0|0] "" X
 SG_ DAS_w077_pmmActive: 12|1@1+ (1,0) [0|0] "" X
 SG_ DAS_w078_pmmActive2: 13|1@1+ (1,0) [0|0] "" X
 SG_ DAS_w079_edrAvailable: 14|1@1+ (1,0) [0|0] "" X
 SG_ DAS_w080_accFailedActivation: 15|1@1+ (1,0) [0|0] "" X
 SG_ DAS_w081_pmmActiveBraking: 16|1@1+ (1,0) [0|0] "" X
 SG_ DAS_w082_inPathFSviolation: 17|1@1+ (1,0) [0|0] "" X
 SG_ DAS_w083_inPathRADObject: 18|1@1+ (1,0) [0|0] "" X
 SG_ DAS_w084_pmmIPSO: 19|1@1+ (1,0) [0|0] "" X
 SG_ DAS_w085_pmmSteering: 20|1@1+ (1,0) [0|0] "" X
 SG_ DAS_w086_robCollision: 21|1@1+ (1,0) [0|0] "" X
 SG_ DAS_w087_DEPRECATED: 22|1@1+ (1,0) [0|0] "" X
 SG_ DAS_w088_DEPRECATED: 23|1@1+ (1,0) [0|0] "" X
 SG_ DAS_w089_DEPRECATED: 24|1@1+ (1,0) [0|0] "" X
 SG_ DAS_w090_DEPRECATED: 25|1@1+ (1,0) [0|0] "" X
 SG_ DAS_w091_DEPRECATED: 26|1@1+ (1,0) [0|0] "" X
 SG_ DAS_w092_DEPRECATED: 27|1@1+ (1,0) [0|0] "" X
 SG_ DAS_w093_DEPRECATED: 28|1@1+ (1,0) [0|0] "" X
 SG_ DAS_w094_DEPRECATED: 29|1@1+ (1,0) [0|0] "" X
 SG_ DAS_w095_DEPRECATED: 30|1@1+ (1,0) [0|0] "" X
 SG_ DAS_w096_DEPRECATED: 31|1@1+ (1,0) [0|0] "" X
 SG_ DAS_w097_DEPRECATED: 32|1@1+ (1,0) [0|0] "" X
 SG_ DAS_w098_DEPRECATED: 33|1@1+ (1,0) [0|0] "" X
 SG_ DAS_w099_DEPRECATED: 34|1@1+ (1,0) [0|0] "" X
 SG_ DAS_w100_DEPRECATED: 35|1@1+ (1,0) [0|0] "" X
 SG_ DAS_w101_DEPRECATED: 36|1@1+ (1,0) [0|0] "" X
 SG_ DAS_w102_DEPRECATED: 37|1@1+ (1,0) [0|0] "" X
 SG_ DAS_w103_robExperimentalAEB: 38|1@1+ (1,0) [0|0] "" X
 SG_ DAS_w104_DEPRECATED: 39|1@1+ (1,0) [0|0] "" X
 SG_ DAS_w105_DEPRECATED: 40|1@1+ (1,0) [0|0] "" X
 SG_ DAS_w106_torsionBarCalibrated: 41|1@1+ (1,0) [0|0] "" X

BO_ 841 DAS_warningMatrix2: 8 VEH
 SG_ DAS_w129_mainCamExtNotCal: 0|1@1+ (1,0) [0|0] "" X
 SG_ DAS_w130_narrowCamExtNotCal: 1|1@1+ (1,0) [0|0] "" X
 SG_ DAS_w131_mainCamCalSaved: 2|1@1+ (1,0) [0|0] "" X
 SG_ DAS_w132_narrowCamCalSaved: 3|1@1+ (1,0) [0|0] "" X
 SG_ DAS_w133_mainCamInitFault: 4|1@1+ (1,0) [0|0] "" X
 SG_ DAS_w134_narrowCamInitFault: 5|1@1+ (1,0) [0|0] "" X
 SG_ DAS_w135_fisheyeCamInitFault: 6|1@1+ (1,0) [0|0] "" X
 SG_ DAS_w136_lPillarCamInitFault: 7|1@1+ (1,0) [0|0] "" X
 SG_ DAS_w137_rPillarCamInitFault: 8|1@1+ (1,0) [0|0] "" X
 SG_ DAS_w138_lRepeatCamInitFault: 9|1@1+ (1,0) [0|0] "" X
 SG_ DAS_w139_rRepeatCamInitFault: 10|1@1+ (1,0) [0|0] "" X
 SG_ DAS_w140_backupCamInitFault: 11|1@1+ (1,0) [0|0] "" X
 SG_ DAS_w141_ECU_Thermal_Issue: 12|1@1+ (1,0) [0|0] "" X
 SG_ DAS_w142_fwdCamPitchProblem: 13|1@1+ (1,0) [0|0] "" X
 SG_ DAS_w143_IDF_event: 14|1@1+ (1,0) [0|0] "" X
 SG_ DAS_w144_selfieCamInitFault: 15|1@1+ (1,0) [0|0] "" X
 SG_ DAS_w171_fisheyeCamExtNotCal: 42|1@1+ (1,0) [0|0] "" X
 SG_ DAS_w172_lPillarCamExtNotCal: 43|1@1+ (1,0) [0|0] "" X
 SG_ DAS_w173_rPillarCamExtNotCal: 44|1@1+ (1,0) [0|0] "" X
 SG_ DAS_w174_lRepeatCamExtNotCal: 45|1@1+ (1,0) [0|0] "" X
 SG_ DAS_w175_rRepeatCamExtNotCal: 46|1@1+ (1,0) [0|0] "" X
 SG_ DAS_w177_fisheyeCamCalSaved: 48|1@1+ (1,0) [0|0] "" X
 SG_ DAS_w178_lPillarCamCalSaved: 49|1@1+ (1,0) [0|0] "" X
 SG_ DAS_w179_rPillarCamCalSaved: 50|1@1+ (1,0) [0|0] "" X
 SG_ DAS_w180_lRepeatCamCalSaved: 51|1@1+ (1,0) [0|0] "" X
 SG_ DAS_w181_rRepeatCamCalSaved: 52|1@1+ (1,0) [0|0] "" X

BO_ 1082 DAS_warningMatrix3: 8 VEH
 SG_ DAS_w193_camWindshieldUnclean: 0|1@1+ (1,0) [0|0] "" X
 SG_ DAS_w194_accDriverResumeRqrd: 1|1@1+ (1,0) [0|0] "" X
 SG_ DAS_w195_scwUnavailable: 2|1@1+ (1,0) [0|0] "" X
 SG_ DAS_w196_stopSignWarning: 3|1@1+ (1,0) [0|0] "" X
 SG_ DAS_w197_redLightWarning: 4|1@1+ (1,0) [0|0] "" X
 SG_ DAS_w198_tsrUnavailable: 5|1@1+ (1,0) [0|0] "" X
 SG_ DAS_w199_apcAbort: 6|1@1+ (1,0) [0|0] "" X
 SG_ DAS_w200_lcSlowdown: 7|1@1+ (1,0) [0|0] "" X
 SG_ DAS_w201_lcAborting: 8|1@1+ (1,0) [0|0] "" X
 SG_ DAS_w202_scwNoisyEnvironment: 9|1@1+ (1,0) [0|0] "" X
 SG_ DAS_w203_apcActivation: 10|1@1+ (1,0) [0|0] "" X
 SG_ DAS_w204_apcFinalFront: 11|1@1+ (1,0) [0|0] "" X
 SG_ DAS_w205_apcFinalRear: 12|1@1+ (1,0) [0|0] "" X
 SG_ DAS_w206_autosteerNotEnabled: 13|1@1+ (1,0) [0|0] "" X
 SG_ DAS_w207_autosteerUnavailable: 14|1@1+ (1,0) [0|0] "" X
 SG_ DAS_w208_rackDetected: 15|1@1+ (1,0) [0|0] "" X
 SG_ DAS_w209_autoSummonRequest: 16|1@1+ (1,0) [0|0] "" X
 SG_ DAS_w210_camObstrcted: 17|1@1+ (1,0) [0|0] "" X
 SG_ DAS_w211_accNoSeatBelt: 18|1@1+ (1,0) [0|0] "" X
 SG_ DAS_w212_lcUnavailableStrikeOut: 19|1@1+ (1,0) [0|0] "" X
 SG_ DAS_w213_autosteerStruckOut: 20|1@1+ (1,0) [0|0] "" X
 SG_ DAS_w214_driverNotIntracting: 21|1@1+ (1,0) [0|0] "" X
 SG_ DAS_w215_contDriverNotIntracting: 22|1@1+ (1,0) [0|0] "" X
 SG_ DAS_w216_driverOverriding: 23|1@1+ (1,0) [0|0] "" X
 SG_ DAS_w217_lcUnavailableSpeeding: 24|1@1+ (1,0) [0|0] "" X
 SG_ DAS_w218_lcSpeedExceededLimit: 25|1@1+ (1,0) [0|0] "" X
 SG_ DAS_w219_lcTempUnavailableSpeed: 26|1@1+ (1,0) [0|0] "" X
 SG_ DAS_w220_lcTempUnavailableRoad: 27|1@1+ (1,0) [0|0] "" X
 SG_ DAS_w221_accRadarBlind: 28|1@1+ (1,0) [0|0] "" X
 SG_ DAS_w222_accCameraBlind: 29|1@1+ (1,0) [0|0] "" X
 SG_ DAS_w223_accObjectInPath: 30|1@1+ (1,0) [0|0] "" X
 SG_ DAS_w224_accCameraCalibration: 31|1@1+ (1,0) [0|0] "" X
 SG_ DAS_w225_lcDegradedVisSpeedLmt: 32|1@1+ (1,0) [0|0] "" X
 SG_ DAS_w226_lcCamCalNeededSpeedLmt: 33|1@1+ (1,0) [0|0] "" X
 SG_ DAS_w227_virtualWallBlocked: 34|1@1+ (1,0) [0|0] "" X
 SG_ DAS_w228_DEPRECATED: 35|1@1+ (1,0) [0|0] "" X
 SG_ DAS_w229_alcUltrasoundDamaged: 36|1@1+ (1,0) [0|0] "" X
 SG_ DAS_w230_alcUltrasoundBlocked: 37|1@1+ (1,0) [0|0] "" X

BO_ 933 DIS_alertMatrix1: 8 VEH
 SG_ DIS_a001_hwPhaseAgateDrive: 0|1@1+ (1,0) [0|0] "" X
 SG_ DIS_a002_hwPhaseBgateDrive: 1|1@1+ (1,0) [0|0] "" X
 SG_ DIS_a003_hwPhaseCgateDrive: 2|1@1+ (1,0) [0|0] "" X
 SG_ DIS_a004_hwPhaseApeak: 3|1@1+ (1,0) [0|0] "" X
 SG_ DIS_a005_hwPhaseBpeak: 4|1@1+ (1,0) [0|0] "" X
 SG_ DIS_a006_hwPhaseCpeak: 5|1@1+ (1,0) [0|0] "" X
 SG_ DIS_a007_hwHvilNotPresent: 6|1@1+ (1,0) [0|0] "" X
 SG_ DIS_a008_hwEncoderA: 7|1@1+ (1,0) [0|0] "" X
 SG_ DIS_a009_hwEncoderB: 8|1@1+ (1,0) [0|0] "" X
 SG_ DIS_a011_swPowerStageNotReady: 10|1@1+ (1,0) [0|0] "" X
 SG_ DIS_a014_activeDamping: 13|1@1+ (1,0) [0|0] "" X
 SG_ DIS_a016_safeStateApplied: 15|1@1+ (1,0) [0|0] "" X
 SG_ DIS_a017_hwPedalMonitor: 16|1@1+ (1,0) [0|0] "" X
 SG_ DIS_a018_hw12vSupplyUV: 17|1@1+ (1,0) [0|0] "" X
 SG_ DIS_a019_hwAccelPedalPower: 18|1@1+ (1,0) [0|0] "" X
 SG_ DIS_a020_hwMotorEncoder: 19|1@1+ (1,0) [0|0] "" X
 SG_ DIS_a021_hwBusOV: 20|1@1+ (1,0) [0|0] "" X
 SG_ DIS_a022_hw5vSupplyUV: 21|1@1+ (1,0) [0|0] "" X
 SG_ DIS_a024_selfTest: 23|1@1+ (1,0) [0|0] "" X
 SG_ DIS_a025_phaseApeak: 24|1@1+ (1,0) [0|0] "" X
 SG_ DIS_a026_phaseBpeak: 25|1@1+ (1,0) [0|0] "" X
 SG_ DIS_a027_phaseCpeak: 26|1@1+ (1,0) [0|0] "" X
 SG_ DIS_a028_phaseArms: 27|1@1+ (1,0) [0|0] "" X
 SG_ DIS_a029_phaseBrms: 28|1@1+ (1,0) [0|0] "" X
 SG_ DIS_a030_phaseCrms: 29|1@1+ (1,0) [0|0] "" X
 SG_ DIS_a031_phaseAcurrentOffset: 30|1@1+ (1,0) [0|0] "" X
 SG_ DIS_a032_phaseBcurrentOffset: 31|1@1+ (1,0) [0|0] "" X
 SG_ DIS_a033_phaseAcurrentSensor: 32|1@1+ (1,0) [0|0] "" X
 SG_ DIS_a034_phaseBcurrentSensor: 33|1@1+ (1,0) [0|0] "" X
 SG_ DIS_a035_phaseCurrentBalance: 34|1@1+ (1,0) [0|0] "" X
 SG_ DIS_a036_busOV: 35|1@1+ (1,0) [0|0] "" X
 SG_ DIS_a037_busUV: 36|1@1+ (1,0) [0|0] "" X
 SG_ DIS_a038_busVsensor: 37|1@1+ (1,0) [0|0] "" X
 SG_ DIS_a040_disMIA: 39|1@1+ (1,0) [0|0] "" X
 SG_ DIS_a042_inletSensor: 41|1@1+ (1,0) [0|0] "" X
 SG_ DIS_a043_outletOT: 42|1@1+ (1,0) [0|0] "" X
 SG_ DIS_a044_outletUT: 43|1@1+ (1,0) [0|0] "" X
 SG_ DIS_a045_outletSensor: 44|1@1+ (1,0) [0|0] "" X
 SG_ DIS_a046_statorOT: 45|1@1+ (1,0) [0|0] "" X
 SG_ DIS_a047_statorSensor1: 46|1@1+ (1,0) [0|0] "" X
 SG_ DIS_a050_noStatorSensor: 49|1@1+ (1,0) [0|0] "" X
 SG_ DIS_a054_driveInverterOT: 53|1@1+ (1,0) [0|0] "" X
 SG_ DIS_a055_trqCrossCheck: 54|1@1+ (1,0) [0|0] "" X
 SG_ DIS_a056_ambientOT: 55|1@1+ (1,0) [0|0] "" X
 SG_ DIS_a057_ambientUT: 56|1@1+ (1,0) [0|0] "" X
 SG_ DIS_a058_ambientSensor: 57|1@1+ (1,0) [0|0] "" X
 SG_ DIS_a059_heatsinkOT: 58|1@1+ (1,0) [0|0] "" X
 SG_ DIS_a060_heatsinkUT: 59|1@1+ (1,0) [0|0] "" X
 SG_ DIS_a061_heatsinkSensor: 60|1@1+ (1,0) [0|0] "" X
 SG_ DIS_a062_systemLimpMode: 61|1@1+ (1,0) [0|0] "" X
 SG_ DIS_a064_torqueIntervention: 63|1@1+ (1,0) [0|0] "" X

BO_ 949 DIS_alertMatrix2: 8 VEH
 SG_ DIS_a065_canHardwareBusB: 0|1@1+ (1,0) [0|0] "" X
 SG_ DIS_a066_canDataBusB: 1|1@1+ (1,0) [0|0] "" X
 SG_ DIS_a067_canOverrunBusB: 2|1@1+ (1,0) [0|0] "" X
 SG_ DIS_a070_12vSupplySensor: 5|1@1+ (1,0) [0|0] "" X
 SG_ DIS_a071_busDisconnected: 6|1@1+ (1,0) [0|0] "" X
 SG_ DIS_a072_gateDriveFaultCounter: 7|1@1+ (1,0) [0|0] "" X
 SG_ DIS_a073_motorSpeed: 8|1@1+ (1,0) [0|0] "" X
 SG_ DIS_a074_motorEncoder: 9|1@1+ (1,0) [0|0] "" X
 SG_ DIS_a075_motorSpeedMismatch: 10|1@1+ (1,0) [0|0] "" X
 SG_ DIS_a076_12vSupplyOV: 11|1@1+ (1,0) [0|0] "" X
 SG_ DIS_a077_12vSupplyUV: 12|1@1+ (1,0) [0|0] "" X
 SG_ DIS_a078_adcRefLow: 13|1@1+ (1,0) [0|0] "" X
 SG_ DIS_a079_adcRefHigh: 14|1@1+ (1,0) [0|0] "" X
 SG_ DIS_a086_hvilNotPresent: 21|1@1+ (1,0) [0|0] "" X
 SG_ DIS_a087_gtwMIA: 22|1@1+ (1,0) [0|0] "" X
 SG_ DIS_a088_uiMIA: 23|1@1+ (1,0) [0|0] "" X
 SG_ DIS_a090_pmMIA: 25|1@1+ (1,0) [0|0] "" X
 SG_ DIS_a091_espMIA: 26|1@1+ (1,0) [0|0] "" X
 SG_ DIS_a092_bmsMIA: 27|1@1+ (1,0) [0|0] "" X
 SG_ DIS_a093_canHardwareBusA: 28|1@1+ (1,0) [0|0] "" X
 SG_ DIS_a094_canDataBusA: 29|1@1+ (1,0) [0|0] "" X
 SG_ DIS_a095_canOverrunBusA: 30|1@1+ (1,0) [0|0] "" X
 SG_ DIS_a096_memoryError: 31|1@1+ (1,0) [0|0] "" X
 SG_ DIS_a097_eepromError: 32|1@1+ (1,0) [0|0] "" X
 SG_ DIS_a098_intTimeTooLong: 33|1@1+ (1,0) [0|0] "" X
 SG_ DIS_a099_threadOverrun: 34|1@1+ (1,0) [0|0] "" X
 SG_ DIS_a100_assertion: 35|1@1+ (1,0) [0|0] "" X
 SG_ DIS_a103_lowFlow: 38|1@1+ (1,0) [0|0] "" X
 SG_ DIS_a106_absMIA: 41|1@1+ (1,0) [0|0] "" X
 SG_ DIS_a108_stateTrans: 43|1@1+ (1,0) [0|0] "" X
 SG_ DIS_a110_brakeMIA: 45|1@1+ (1,0) [0|0] "" X
 SG_ DIS_a112_noPhaseCurrent: 47|1@1+ (1,0) [0|0] "" X
 SG_ DIS_a113_noFuncHeatsinkSensor: 48|1@1+ (1,0) [0|0] "" X
 SG_ DIS_a114_noMotorSpeed: 49|1@1+ (1,0) [0|0] "" X
 SG_ DIS_a115_heatsinkTempImbalance: 50|1@1+ (1,0) [0|0] "" X
 SG_ DIS_a116_powerConvIrrational: 51|1@1+ (1,0) [0|0] "" X
 SG_ DIS_a117_diMIA: 52|1@1+ (1,0) [0|0] "" X
 SG_ DIS_a121_motorControlRegulation: 56|1@1+ (1,0) [0|0] "" X
 SG_ DIS_a122_highStackUsage: 57|1@1+ (1,0) [0|0] "" X
 SG_ DIS_a123_lossMotorControl: 58|1@1+ (1,0) [0|0] "" X
 SG_ DIS_a126_limpMode: 61|1@1+ (1,0) [0|0] "" X
 SG_ DIS_a127_gracefulPowerOff: 62|1@1+ (1,0) [0|0] "" X

BO_ 965 DIS_alertMatrix3: 8 VEH
 SG_ DIS_a129_epbNotApplied: 0|1@1+ (1,0) [0|0] "" X
 SG_ DIS_a131_highSpeedWearLimit: 2|1@1+ (1,0) [0|0] "" X
 SG_ DIS_a133_capacitorOT: 4|1@1+ (1,0) [0|0] "" X
 SG_ DIS_a134_wheelSpeedIrrational: 5|1@1+ (1,0) [0|0] "" X
 SG_ DIS_a136_spiError: 7|1@1+ (1,0) [0|0] "" X
 SG_ DIS_a142_highLashAngle: 13|1@1+ (1,0) [0|0] "" X
 SG_ DIS_a143_mcuLimitActive: 14|1@1+ (1,0) [0|0] "" X
 SG_ DIS_a144_configMismatch: 15|1@1+ (1,0) [0|0] "" X
 SG_ DIS_a147_highTorqueWearLimit: 18|1@1+ (1,0) [0|0] "" X
 SG_ DIS_a148_overtorqueUsed: 19|1@1+ (1,0) [0|0] "" X
 SG_ DIS_a149_oilPumpFailure: 20|1@1+ (1,0) [0|0] "" X
 SG_ DIS_a150_busVD: 21|1@1+ (1,0) [0|0] "" X
 SG_ DIS_a151_shockTorqueLimiter: 22|1@1+ (1,0) [0|0] "" X
 SG_ DIS_a152_linError: 23|1@1+ (1,0) [0|0] "" X
 SG_ DIS_a153_oilPump: 24|1@1+ (1,0) [0|0] "" X
 SG_ DIS_a154_resolver: 25|1@1+ (1,0) [0|0] "" X
 SG_ DIS_a155_vcfrontMIA: 26|1@1+ (1,0) [0|0] "" X
 SG_ DIS_a156_currentObserver: 27|1@1+ (1,0) [0|0] "" X
 SG_ DIS_a157_rcmMIA: 28|1@1+ (1,0) [0|0] "" X
 SG_ DIS_a158_ibstMIA: 29|1@1+ (1,0) [0|0] "" X
 SG_ DIS_a160_busVoltageAnomaly: 31|1@1+ (1,0) [0|0] "" X
 SG_ DIS_a161_epas3pMIA: 32|1@1+ (1,0) [0|0] "" X

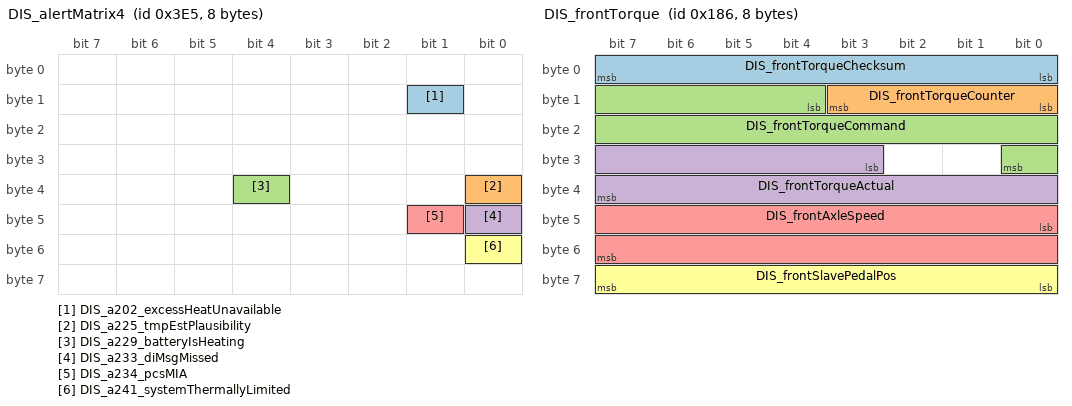
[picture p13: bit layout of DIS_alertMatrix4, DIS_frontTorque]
BO_ 997 DIS_alertMatrix4: 8 VEH
 SG_ DIS_a202_excessHeatUnavailable: 9|1@1+ (1,0) [0|0] "" X
 SG_ DIS_a225_tmpEstPlausibility: 32|1@1+ (1,0) [0|0] "" X
 SG_ DIS_a229_batteryIsHeating: 36|1@1+ (1,0) [0|0] "" X
 SG_ DIS_a233_diMsgMissed: 40|1@1+ (1,0) [0|0] "" X
 SG_ DIS_a234_pcsMIA: 41|1@1+ (1,0) [0|0] "" X
 SG_ DIS_a241_systemThermallyLimited: 48|1@1+ (1,0) [0|0] "" X

BO_ 392 DIS_capability2: 2 VEH
 SG_ DIS_heatPowerMax: 8|8@1+ (0.08,0) [0|0] "kW" X
 SG_ DIS_heatPowerOptimal: 0|8@1+ (0.08,0) [0|0] "kW" X

BO_ 821 DIS_info: 8 VEH
 SG_ DIS_infoIndex M: 0|8@1+ (1,0) [0|0] "" X
 SG_ DIS_buildType m10: 8|3@1+ (1,0) [0|0] "" X
 SG_ DIS_buildConfigurationId m10: 16|16@1+ (1,0) [0|0] "" X
 SG_ DIS_hardwareId m10: 32|8@1+ (1,0) [0|0] "" X
 SG_ DIS_componentId m10: 48|16@1+ (1,0) [0|0] "" X
 SG_ DIS_pcbaId m11: 16|8@1+ (1,0) [0|0] "" X
 SG_ DIS_assemblyId m11: 24|8@1+ (1,0) [0|0] "" X
 SG_ DIS_usageId m11: 32|16@1+ (1,0) [0|0] "" X
 SG_ DIS_subUsageId m11: 48|16@1+ (1,0) [0|0] "" X
 SG_ DIS_applicationSvnRevision m12: 8|24@1+ (1,0) [0|0] "" X
 SG_ DIS_applicationSvnUrlHash m12: 32|32@1+ (1,0) [0|0] "" X
 SG_ DIS_applicationCrc m13: 32|32@1+ (1,0) [0|0] "" X
 SG_ DIS_bootloaderSvnRevision m14: 8|24@1+ (1,0) [0|0] "" X
 SG_ DIS_bootloaderSvnUrlHash m14: 32|32@1+ (1,0) [0|0] "" X
 SG_ DIS_oilPumpBuildType m16: 8|3@1+ (1,0) [0|0] "" X
 SG_ DIS_oilPumpAppCrc m16: 16|32@1+ (1,0) [0|0] "" X
 SG_ DIS_appGitHash m17: 10|54@1+ (4,0) [0|0] "" X
 SG_ DIS_bootGitHash m18: 10|54@1+ (4,0) [0|0] "" X
 SG_ DIS_platformTyp m19: 8|8@1+ (1,0) [0|0] "" X
 SG_ DIS_infoBootLdUdsProtocolVersion m20: 8|8@1+ (1,0) [0|0] "" X
 SG_ DIS_bootloaderCrc m20: 32|32@1+ (1,0) [0|0] "" X
 SG_ DIS_subcomponentGitHash m31: 10|54@1+ (4,0) [0|0] "" X

BO_ 390 DIS_frontTorque: 8 VEH
 SG_ DIS_frontTorqueChecksum: 0|8@1+ (1,0) [0|0] "" X
 SG_ DIS_frontTorqueCounter: 8|4@1+ (1,0) [0|0] "" X
 SG_ DIS_frontTorqueCommand: 12|13@1- (2,0) [0|0] "Nm" X
 SG_ DIS_frontTorqueActual: 27|13@1- (2,0) [0|0] "Nm" X
 SG_ DIS_frontAxleSpeed: 40|16@1- (0.1,0) [0|0] "RPM" X
 SG_ DIS_frontSlavePedalPos : 56|8@1+ (0.4,0) [0|100] "%" X

BO_ 472 DIS_torque: 8 VEH
 SG_ DIS_torqueFlags: 0|8@1+ (1,0) [0|0] "" X
 SG_ DIS_torqueCommand: 8|15@1- (0.1,0) [0|0] "Nm" X
 SG_ DIS_torqueActual: 24|13@1- (2,0) [0|0] "Nm" X
 SG_ DIS_axleSpeed: 40|16@1- (0.1,0) [0|0] "RPM" X
 SG_ DIS_torqueChecksum: 56|8@1+ (1,0) [0|0] "" X
 SG_ DIS_torqueCounter: 53|3@1+ (1,0) [0|0] "" X

BO_ 854 DI_alertMatrix1: 8 VEH
 SG_ DI_a001_hwPhaseAgateDrive: 0|1@1+ (1,0) [0|0] "" X
 SG_ DI_a002_hwPhaseBgateDrive: 1|1@1+ (1,0) [0|0] "" X
 SG_ DI_a003_hwPhaseCgateDrive: 2|1@1+ (1,0) [0|0] "" X
 SG_ DI_a004_hwPhaseApeak: 3|1@1+ (1,0) [0|0] "" X
 SG_ DI_a005_hwPhaseBpeak: 4|1@1+ (1,0) [0|0] "" X
 SG_ DI_a006_hwPhaseCpeak: 5|1@1+ (1,0) [0|0] "" X
 SG_ DI_a007_hwHvilNotPresent: 6|1@1+ (1,0) [0|0] "" X
 SG_ DI_a008_hwEncoderA: 7|1@1+ (1,0) [0|0] "" X
 SG_ DI_a009_hwEncoderB: 8|1@1+ (1,0) [0|0] "" X
 SG_ DI_a011_swPowerStageNotReady: 10|1@1+ (1,0) [0|0] "" X
 SG_ DI_a012_accel5VSupply: 11|1@1+ (1,0) [0|0] "" X
 SG_ DI_a014_activeDamping: 13|1@1+ (1,0) [0|0] "" X
 SG_ DI_a015_immobilizer: 14|1@1+ (1,0) [0|0] "" X
 SG_ DI_a016_safeStateApplied: 15|1@1+ (1,0) [0|0] "" X
 SG_ DI_a017_hwPedalMonitor: 16|1@1+ (1,0) [0|0] "" X
 SG_ DI_a018_hw12vSupplyUV: 17|1@1+ (1,0) [0|0] "" X
 SG_ DI_a019_hwAccelPedalPower: 18|1@1+ (1,0) [0|0] "" X
 SG_ DI_a020_hwMotorEncoder: 19|1@1+ (1,0) [0|0] "" X
 SG_ DI_a021_hwBusOV: 20|1@1+ (1,0) [0|0] "" X
 SG_ DI_a022_hw5vSupplyUV: 21|1@1+ (1,0) [0|0] "" X
 SG_ DI_a023_carNotParked: 22|1@1+ (1,0) [0|0] "" X
 SG_ DI_a024_selfTest: 23|1@1+ (1,0) [0|0] "" X
 SG_ DI_a025_phaseApeak: 24|1@1+ (1,0) [0|0] "" X
 SG_ DI_a026_phaseBpeak: 25|1@1+ (1,0) [0|0] "" X
 SG_ DI_a027_phaseCpeak: 26|1@1+ (1,0) [0|0] "" X
 SG_ DI_a028_phaseArms: 27|1@1+ (1,0) [0|0] "" X
 SG_ DI_a029_phaseBrms: 28|1@1+ (1,0) [0|0] "" X
 SG_ DI_a030_phaseCrms: 29|1@1+ (1,0) [0|0] "" X
 SG_ DI_a031_phaseAcurrentOffset: 30|1@1+ (1,0) [0|0] "" X
 SG_ DI_a032_phaseBcurrentOffset: 31|1@1+ (1,0) [0|0] "" X
 SG_ DI_a033_phaseAcurrentSensor: 32|1@1+ (1,0) [0|0] "" X
 SG_ DI_a034_phaseBcurrentSensor: 33|1@1+ (1,0) [0|0] "" X
 SG_ DI_a035_phaseCurrentBalance: 34|1@1+ (1,0) [0|0] "" X
 SG_ DI_a036_busOV: 35|1@1+ (1,0) [0|0] "" X
 SG_ DI_a037_busUV: 36|1@1+ (1,0) [0|0] "" X
 SG_ DI_a038_busVsensor: 37|1@1+ (1,0) [0|0] "" X
 SG_ DI_a039_noRegen: 38|1@1+ (1,0) [0|0] "" X
 SG_ DI_a040_disMIA: 39|1@1+ (1,0) [0|0] "" X
 SG_ DI_a041_driverBrakeApplyCheck: 40|1@1+ (1,0) [0|0] "" X
 SG_ DI_a042_inletSensor: 41|1@1+ (1,0) [0|0] "" X
 SG_ DI_a043_outletOT: 42|1@1+ (1,0) [0|0] "" X
 SG_ DI_a044_outletUT: 43|1@1+ (1,0) [0|0] "" X
 SG_ DI_a045_outletSensor: 44|1@1+ (1,0) [0|0] "" X
 SG_ DI_a046_statorOT: 45|1@1+ (1,0) [0|0] "" X
 SG_ DI_a047_statorSensor1: 46|1@1+ (1,0) [0|0] "" X
 SG_ DI_a050_noStatorSensor: 49|1@1+ (1,0) [0|0] "" X
 SG_ DI_a051_batteryOvercurrent: 50|1@1+ (1,0) [0|0] "" X
 SG_ DI_a054_driveInverterOT: 53|1@1+ (1,0) [0|0] "" X
 SG_ DI_a055_trqCrossCheck: 54|1@1+ (1,0) [0|0] "" X
 SG_ DI_a056_ambientOT: 55|1@1+ (1,0) [0|0] "" X
 SG_ DI_a057_ambientUT: 56|1@1+ (1,0) [0|0] "" X
 SG_ DI_a058_ambientSensor: 57|1@1+ (1,0) [0|0] "" X
 SG_ DI_a059_heatsinkOT: 58|1@1+ (1,0) [0|0] "" X
 SG_ DI_a060_heatsinkUT: 59|1@1+ (1,0) [0|0] "" X
 SG_ DI_a061_heatsinkSensor: 60|1@1+ (1,0) [0|0] "" X
 SG_ DI_a062_systemLimpMode: 61|1@1+ (1,0) [0|0] "" X
 SG_ DI_a063_systemGracefulPowerOff: 62|1@1+ (1,0) [0|0] "" X
 SG_ DI_a064_torqueIntervention: 63|1@1+ (1,0) [0|0] "" X

BO_ 855 DI_alertMatrix2: 8 VEH
 SG_ DI_a065_canHardwareBusB: 0|1@1+ (1,0) [0|0] "" X
 SG_ DI_a066_canDataBusB: 1|1@1+ (1,0) [0|0] "" X
 SG_ DI_a067_canOverrunBusB: 2|1@1+ (1,0) [0|0] "" X
 SG_ DI_a070_12vSupplySensor: 5|1@1+ (1,0) [0|0] "" X
 SG_ DI_a071_busDisconnected: 6|1@1+ (1,0) [0|0] "" X
 SG_ DI_a072_gateDriveFaultCounter: 7|1@1+ (1,0) [0|0] "" X
 SG_ DI_a073_motorSpeed: 8|1@1+ (1,0) [0|0] "" X
 SG_ DI_a074_motorEncoder: 9|1@1+ (1,0) [0|0] "" X
 SG_ DI_a075_motorSpeedMismatch: 10|1@1+ (1,0) [0|0] "" X
 SG_ DI_a076_12vSupplyOV: 11|1@1+ (1,0) [0|0] "" X
 SG_ DI_a077_12vSupplyUV: 12|1@1+ (1,0) [0|0] "" X
 SG_ DI_a078_adcRefLow: 13|1@1+ (1,0) [0|0] "" X
 SG_ DI_a079_adcRefHigh: 14|1@1+ (1,0) [0|0] "" X
 SG_ DI_a080_accelSynch: 15|1@1+ (1,0) [0|0] "" X
 SG_ DI_a081_accelTrack1: 16|1@1+ (1,0) [0|0] "" X
 SG_ DI_a082_accelTrack2: 17|1@1+ (1,0) [0|0] "" X
 SG_ DI_a083_brakePedalSensor: 18|1@1+ (1,0) [0|0] "" X
 SG_ DI_a085_proximityInEnable: 20|1@1+ (1,0) [0|0] "" X
 SG_ DI_a086_hvilNotPresent: 21|1@1+ (1,0) [0|0] "" X
 SG_ DI_a087_gtwMIA: 22|1@1+ (1,0) [0|0] "" X
 SG_ DI_a088_uiMIA: 23|1@1+ (1,0) [0|0] "" X
 SG_ DI_a089_sccmMIA: 24|1@1+ (1,0) [0|0] "" X
 SG_ DI_a090_pmMIA: 25|1@1+ (1,0) [0|0] "" X
 SG_ DI_a091_espMIA: 26|1@1+ (1,0) [0|0] "" X
 SG_ DI_a092_bmsMIA: 27|1@1+ (1,0) [0|0] "" X
 SG_ DI_a093_canHardwareBusA: 28|1@1+ (1,0) [0|0] "" X
 SG_ DI_a094_canDataBusA: 29|1@1+ (1,0) [0|0] "" X
 SG_ DI_a095_canOverrunBusA: 30|1@1+ (1,0) [0|0] "" X
 SG_ DI_a096_memoryError: 31|1@1+ (1,0) [0|0] "" X
 SG_ DI_a097_eepromError: 32|1@1+ (1,0) [0|0] "" X
 SG_ DI_a098_intTimeTooLong: 33|1@1+ (1,0) [0|0] "" X
 SG_ DI_a099_threadOverrun: 34|1@1+ (1,0) [0|0] "" X
 SG_ DI_a100_assertion: 35|1@1+ (1,0) [0|0] "" X
 SG_ DI_a103_lowFlow: 38|1@1+ (1,0) [0|0] "" X
 SG_ DI_a104_proximityIrrational: 39|1@1+ (1,0) [0|0] "" X
 SG_ DI_a105_cpMIA: 40|1@1+ (1,0) [0|0] "" X
 SG_ DI_a106_absMIA: 41|1@1+ (1,0) [0|0] "" X
 SG_ DI_a108_stateTrans: 43|1@1+ (1,0) [0|0] "" X
 SG_ DI_a109_cruiseMIA: 44|1@1+ (1,0) [0|0] "" X
 SG_ DI_a110_brakeMIA: 45|1@1+ (1,0) [0|0] "" X
 SG_ DI_a112_noPhaseCurrent: 47|1@1+ (1,0) [0|0] "" X
 SG_ DI_a113_noFuncHeatsinkSensor: 48|1@1+ (1,0) [0|0] "" X
 SG_ DI_a114_noMotorSpeed: 49|1@1+ (1,0) [0|0] "" X
 SG_ DI_a115_heatsinkTempImbalance: 50|1@1+ (1,0) [0|0] "" X
 SG_ DI_a116_powerConvIrrational: 51|1@1+ (1,0) [0|0] "" X
 SG_ DI_a117_diMIA: 52|1@1+ (1,0) [0|0] "" X
 SG_ DI_a121_motorControlRegulation: 56|1@1+ (1,0) [0|0] "" X
 SG_ DI_a122_highStackUsage: 57|1@1+ (1,0) [0|0] "" X
 SG_ DI_a123_lossMotorControl: 58|1@1+ (1,0) [0|0] "" X
 SG_ DI_a124_cruiseFault: 59|1@1+ (1,0) [0|0] "" X
 SG_ DI_a125_noBatteryPower: 60|1@1+ (1,0) [0|0] "" X
 SG_ DI_a126_limpMode: 61|1@1+ (1,0) [0|0] "" X
 SG_ DI_a127_gracefulPowerOff: 62|1@1+ (1,0) [0|0] "" X

BO_ 858 DI_alertMatrix3: 8 VEH
 SG_ DI_a129_epbNotApplied: 0|1@1+ (1,0) [0|0] "" X
 SG_ DI_a130_aebFault: 1|1@1+ (1,0) [0|0] "" X
 SG_ DI_a131_highSpeedWearLimit: 2|1@1+ (1,0) [0|0] "" X
 SG_ DI_a133_capacitorOT: 4|1@1+ (1,0) [0|0] "" X
 SG_ DI_a134_wheelSpeedIrrational: 5|1@1+ (1,0) [0|0] "" X
 SG_ DI_a135_vehicleHoldFault: 6|1@1+ (1,0) [0|0] "" X
 SG_ DI_a136_spiError: 7|1@1+ (1,0) [0|0] "" X
 SG_ DI_a137_noCapableDriveUnits: 8|1@1+ (1,0) [0|0] "" X
 SG_ DI_a138_frontUnitDisabled: 9|1@1+ (1,0) [0|0] "" X
 SG_ DI_a139_rearUnitDisabled: 10|1@1+ (1,0) [0|0] "" X
 SG_ DI_a141_dasMIA: 12|1@1+ (1,0) [0|0] "" X
 SG_ DI_a142_highLashAngle: 13|1@1+ (1,0) [0|0] "" X
 SG_ DI_a143_mcuLimitActive: 14|1@1+ (1,0) [0|0] "" X
 SG_ DI_a144_configMismatch: 15|1@1+ (1,0) [0|0] "" X
 SG_ DI_a145_pbrkPanicSkid: 16|1@1+ (1,0) [0|0] "" X
 SG_ DI_a146_pbrkPanicEpbFault: 17|1@1+ (1,0) [0|0] "" X
 SG_ DI_a147_highTorqueWearLimit: 18|1@1+ (1,0) [0|0] "" X
 SG_ DI_a148_overtorqueUsed: 19|1@1+ (1,0) [0|0] "" X
 SG_ DI_a149_oilPumpFailure: 20|1@1+ (1,0) [0|0] "" X
 SG_ DI_a150_busVD: 21|1@1+ (1,0) [0|0] "" X
 SG_ DI_a151_shockTorqueLimiter: 22|1@1+ (1,0) [0|0] "" X
 SG_ DI_a152_linError: 23|1@1+ (1,0) [0|0] "" X
 SG_ DI_a153_oilPump: 24|1@1+ (1,0) [0|0] "" X
 SG_ DI_a154_resolver: 25|1@1+ (1,0) [0|0] "" X
 SG_ DI_a155_vcfrontMIA: 26|1@1+ (1,0) [0|0] "" X
 SG_ DI_a156_currentObserver: 27|1@1+ (1,0) [0|0] "" X
 SG_ DI_a157_rcmMIA: 28|1@1+ (1,0) [0|0] "" X
 SG_ DI_a158_ibstMIA: 29|1@1+ (1,0) [0|0] "" X
 SG_ DI_a159_cruiseSelfCheck: 30|1@1+ (1,0) [0|0] "" X
 SG_ DI_a160_busVoltageAnomaly: 31|1@1+ (1,0) [0|0] "" X
 SG_ DI_a161_epas3pMIA: 32|1@1+ (1,0) [0|0] "" X
 SG_ DI_a162_shiftDenied: 33|1@1+ (1,0) [0|0] "" X
 SG_ DI_a163_unparkReq: 34|1@1+ (1,0) [0|0] "" X
 SG_ DI_a164_brakeOverride: 35|1@1+ (1,0) [0|0] "" X
 SG_ DI_a165_cruiseCancelled: 36|1@1+ (1,0) [0|0] "" X
 SG_ DI_a166_driverLeft: 37|1@1+ (1,0) [0|0] "" X
 SG_ DI_a167_keyNotAuthenticated: 38|1@1+ (1,0) [0|0] "" X
 SG_ DI_a168_proximityDriveDenial: 39|1@1+ (1,0) [0|0] "" X
 SG_ DI_a169_regenOffOverride: 40|1@1+ (1,0) [0|0] "" X
 SG_ DI_a170_pedalFoul: 41|1@1+ (1,0) [0|0] "" X
 SG_ DI_a171_driveRailNotRequested: 42|1@1+ (1,0) [0|0] "" X
 SG_ DI_a172_accelPressedInNP: 43|1@1+ (1,0) [0|0] "" X
 SG_ DI_a173_bothPedalsPressed: 44|1@1+ (1,0) [0|0] "" X
 SG_ DI_a174_notOkToStartDrive: 45|1@1+ (1,0) [0|0] "" X
 SG_ DI_a175_crsNotAvailable: 46|1@1+ (1,0) [0|0] "" X
 SG_ DI_a176_EBRreleased: 47|1@1+ (1,0) [0|0] "" X
 SG_ DI_a177_tireFitmentChanged: 48|1@1+ (1,0) [0|0] "" X
 SG_ DI_a180_crsSeatbeltUnbuckled: 51|1@1+ (1,0) [0|0] "" X
 SG_ DI_a181_rearMotorMode: 52|1@1+ (1,0) [0|0] "" X
 SG_ DI_a182_frontMotorMode: 53|1@1+ (1,0) [0|0] "" X
 SG_ DI_a183_holdReleaseRqrd: 54|1@1+ (1,0) [0|0] "" X
 SG_ DI_a184_autoparkCanceled: 55|1@1+ (1,0) [0|0] "" X
 SG_ DI_a185_autoparkAborted: 56|1@1+ (1,0) [0|0] "" X
 SG_ DI_a186_brakeStand: 57|1@1+ (1,0) [0|0] "" X
 SG_ DI_a187_pedalMisapplication: 58|1@1+ (1,0) [0|0] "" X
 SG_ DI_a189_garageShiftWithPedal: 60|1@1+ (1,0) [0|0] "" X
 SG_ DI_a191_brakeShiftReq: 62|1@1+ (1,0) [0|0] "" X
 SG_ DI_a192_invalidOdometer: 63|1@1+ (1,0) [0|0] "" X

BO_ 859 DI_alertMatrix4: 8 VEH
 SG_ DI_a193_vdcEspBrakeTorqueFr: 0|1@1+ (1,0) [0|0] "" X
 SG_ DI_a194_vdcEspBrakeTorqueRe: 1|1@1+ (1,0) [0|0] "" X
 SG_ DI_a195_vdcEspSlipFr: 2|1@1+ (1,0) [0|0] "" X
 SG_ DI_a196_vdcEspSlipRe: 3|1@1+ (1,0) [0|0] "" X
 SG_ DI_a197_vdcEspWheelSaturations: 4|1@1+ (1,0) [0|0] "" X
 SG_ DI_a198_vdcEspMCPressAndSteering: 5|1@1+ (1,0) [0|0] "" X
 SG_ DI_a199_vdcFaulted: 6|1@1+ (1,0) [0|0] "" X
 SG_ DI_a200_vdcModelBasedPlausibility: 7|1@1+ (1,0) [0|0] "" X
 SG_ DI_a201_regenLimited: 8|1@1+ (1,0) [0|0] "" X
 SG_ DI_a202_excessHeatUnavailable: 9|1@1+ (1,0) [0|0] "" X
 SG_ DI_a203_TCReducedByADD: 10|1@1+ (1,0) [0|0] "" X
 SG_ DI_a204_vdcRcmLongitudinal: 11|1@1+ (1,0) [0|0] "" X
 SG_ DI_a205_vdcRcmLateral: 12|1@1+ (1,0) [0|0] "" X
 SG_ DI_a206_vdcRcmVertical: 13|1@1+ (1,0) [0|0] "" X
 SG_ DI_a207_vdcPowertrainTorqueFr: 14|1@1+ (1,0) [0|0] "" X
 SG_ DI_a208_vdcPowertrainTorqueRe: 15|1@1+ (1,0) [0|0] "" X
 SG_ DI_a209_vdcVehicleSpeed: 16|1@1+ (1,0) [0|0] "" X
 SG_ DI_a210_vdcOtherControllerStates: 17|1@1+ (1,0) [0|0] "" X
 SG_ DI_a211_vdcMotorSpeeds: 18|1@1+ (1,0) [0|0] "" X
 SG_ DI_a212_velEstWheelSpeedCGFr: 19|1@1+ (1,0) [0|0] "" X
 SG_ DI_a213_velEstWheelSpeedCGRe: 20|1@1+ (1,0) [0|0] "" X
 SG_ DI_a214_velEstWheelSpeedNonCGFr: 21|1@1+ (1,0) [0|0] "" X
 SG_ DI_a215_velEstWheelSpeedNonCGRe: 22|1@1+ (1,0) [0|0] "" X
 SG_ DI_a216_vdcMBPAlmostTripped: 23|1@1+ (1,0) [0|0] "" X
 SG_ DI_a217_vdcOutputIrrational: 24|1@1+ (1,0) [0|0] "" X
 SG_ DI_a218_vdcOSPreControlActive: 25|1@1+ (1,0) [0|0] "" X
 SG_ DI_a219_vdcOversteerdMzActive: 26|1@1+ (1,0) [0|0] "" X
 SG_ DI_a220_vdcUndersteerDecelActive: 27|1@1+ (1,0) [0|0] "" X
 SG_ DI_a221_vdcUndersteerdMzActive: 28|1@1+ (1,0) [0|0] "" X
 SG_ DI_a222_vdcDisabled: 29|1@1+ (1,0) [0|0] "" X
 SG_ DI_a223_tractionControlDisabled: 30|1@1+ (1,0) [0|0] "" X
 SG_ DI_a224_brakeOverTemp: 31|1@1+ (1,0) [0|0] "" X
 SG_ DI_a225_tmpEstPlausibility: 32|1@1+ (1,0) [0|0] "" X
 SG_ DI_a226_sysStartConditionNotMet: 33|1@1+ (1,0) [0|0] "" X
 SG_ DI_a227_contactorsNotClosed: 34|1@1+ (1,0) [0|0] "" X
 SG_ DI_a228_brakeTempEstUnavailable: 35|1@1+ (1,0) [0|0] "" X
 SG_ DI_a229_batteryIsHeating: 36|1@1+ (1,0) [0|0] "" X
 SG_ DI_a230_cmpMIA: 37|1@1+ (1,0) [0|0] "" X
 SG_ DI_a231_ptcMIA: 38|1@1+ (1,0) [0|0] "" X
 SG_ DI_a232_velocityEstimatorDegraded: 39|1@1+ (1,0) [0|0] "" X
 SG_ DI_a233_diMsgMissed: 40|1@1+ (1,0) [0|0] "" X
 SG_ DI_a234_pcsMIA: 41|1@1+ (1,0) [0|0] "" X
 SG_ DI_a235_trackModeActive: 42|1@1+ (1,0) [0|0] "" X
 SG_ DI_a238_brakeOverTempBrembo: 45|1@1+ (1,0) [0|0] "" X
 SG_ DI_a239_neutralRequestByPM: 46|1@1+ (1,0) [0|0] "" X
 SG_ DI_a241_systemThermallyLimited: 48|1@1+ (1,0) [0|0] "" X

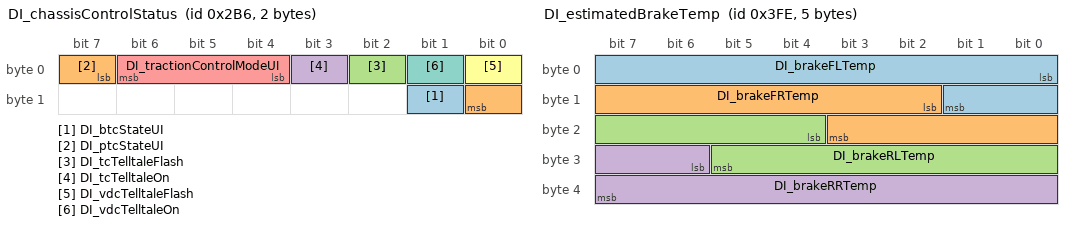
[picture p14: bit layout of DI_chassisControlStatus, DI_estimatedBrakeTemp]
BO_ 694 DI_chassisControlStatus: 2 VEH
 SG_ DI_btcStateUI: 9|1@1+ (1,0) [0|0] "" X
 SG_ DI_ptcStateUI: 7|2@1+ (1,0) [0|0] "" X
 SG_ DI_tcTelltaleFlash: 2|1@1+ (1,0) [0|0] "" X
 SG_ DI_tcTelltaleOn: 3|1@1+ (1,0) [0|0] "" X
 SG_ DI_tractionControlModeUI: 4|3@1+ (1,0) [0|0] "" X
 SG_ DI_vdcTelltaleFlash: 0|1@1+ (1,0) [0|0] "" X
 SG_ DI_vdcTelltaleOn: 1|1@1+ (1,0) [0|0] "" X

BO_ 2005 DI_debug: 8 VEH
 SG_ DI_debugSelector M: 0|8@1+ (1,0) [0|0] "" X
 SG_ DI_motorType m128: 8|5@1+ (1,0) [0|0] "" X
 SG_ DI_cpu1HzMin m128: 16|8@1+ (0.4,0) [0|0] "%" X
 SG_ DI_cpu1HzMax m128: 24|8@1+ (0.4,0) [0|0] "%" X
 SG_ DI_cpu1HzAvg m128: 32|8@1+ (0.4,0) [0|0] "%" X
 SG_ DI_muSurfHigh m2: 8|8@1+ (0.005,0) [0|0] "N/N" X
 SG_ DI_brakeCpScale m2: 16|9@1- (0.01,0.5) [0|0] "N/N" X
 SG_ DI_pedalPosFilt m2: 32|8@1+ (0.4,0) [0|0] "%" X
 SG_ DI_cpuIDWord0 m131: 16|16@1+ (1,0) [0|0] "" X
 SG_ DI_crc m131: 32|32@1+ (1,0) [0|0] "" X
 SG_ DI_cpuIDWord1 m132: 16|16@1+ (1,0) [0|0] "" X
 SG_ DI_cpuIDWord2 m132: 32|16@1+ (1,0) [0|0] "" X
 SG_ DI_cpuIDWord3 m132: 48|16@1+ (1,0) [0|0] "" X
 SG_ DI_offsetA m32: 8|8@1- (0.1,0) [0|0] "A" X
 SG_ DI_motorIA m32: 16|16@1+ (0.1,0) [0|0] "A" X
 SG_ DI_motorIB m32: 32|16@1+ (0.1,0) [0|0] "A" X
 SG_ DI_motorIC m32: 48|16@1+ (0.1,0) [0|0] "A" X
 SG_ DI_offsetB m33: 8|8@1- (0.1,0) [0|0] "A" X
 SG_ DI_statorIDref m33: 16|16@1- (0.1,0) [0|0] "A" X
 SG_ DI_statorIDfdb m33: 32|16@1- (0.1,0) [0|0] "A" X
 SG_ DI_torquePerAmp m33: 48|16@1+ (0.0001,0) [0|0] "Nm/A" X
 SG_ DI_rsScale m34: 8|8@1+ (0.01,0) [0|0] "scale" X
 SG_ DI_statorIQref m34: 16|16@1- (0.1,0) [0|0] "A" X
 SG_ DI_statorIQfdb m34: 32|16@1- (0.1,0) [0|0] "A" X
 SG_ DI_motorV m34: 48|16@1+ (2e-05,0) [0|0] "mindex" X
 SG_ DI_tqScaleDifferential m35: 8|8@1+ (0.4,0) [0|0] "%" X
 SG_ DI_statorFluxRef m35: 16|16@1+ (0.0001,0) [0|0] "Wb" X
 SG_ DI_statorFluxFdb m35: 32|16@1+ (0.0001,0) [0|0] "Wb" X
 SG_ DI_systemTorqueCommand m35: 48|16@1- (0.035,0) [0|0] "Nm" X
 SG_ DI_lmScale m36: 8|8@1+ (0.004,0) [0|0] "scale" X
 SG_ DI_statorVQ m36: 16|16@1- (4e-05,0) [0|0] "mindex" X
 SG_ DI_statorVD m36: 32|16@1- (4e-05,0) [0|0] "mindex" X
 SG_ DI_peakFlux m36: 48|16@1+ (0.0001,0) [0|0] "Wb" X
 SG_ DI_gainScale m37: 8|8@1+ (0.01,0) [0|0] "scale" X
 SG_ DI_dcCableCurrentEst m37: 16|16@1- (0.1,0) [0|0] "A" X
 SG_ DI_loadAngleMargin m37: 32|16@1- (0.0003,0) [0|0] "rad" X
 SG_ DI_internalAngleFilt m37: 48|16@1+ (0.0003,0) [0|0] "rad" X
 SG_ DI_ssmState m38: 8|4@1+ (1,0) [0|0] "" X
 SG_ DI_usmState m38: 12|3@1+ (1,0) [0|0] "" X
 SG_ DI_peakIQref m38: 16|16@1+ (0.1,0) [0|0] "A" X
 SG_ DI_motorIAavg m38: 32|16@1- (0.1,0) [0|0] "A" X
 SG_ DI_motorIBavg m38: 48|16@1- (0.1,0) [0|0] "A" X
 SG_ DI_tqSatThermal m39: 8|8@1+ (0.4,0) [0|0] "%" X
 SG_ DI_pwrSatMaxDischargePower m39: 16|8@1+ (0.4,0) [0|0] "%" X
 SG_ DI_pwrSatMaxRegenPower m39: 24|8@1+ (0.4,0) [0|0] "%" X
 SG_ DI_tqSatMotorVoltage m39: 32|8@1+ (0.4,0) [0|0] "%" X
 SG_ DI_tqSatMotorCurrent m39: 40|8@1+ (0.4,0) [0|0] "%" X
 SG_ DI_pwrSatMaxBusVoltage m39: 48|8@1+ (0.4,0) [0|0] "%" X
 SG_ DI_pwrSatMinBusVoltage m39: 56|8@1+ (0.4,0) [0|0] "%" X
 SG_ DI_pwrSatDischargeCurrent m40: 8|8@1+ (0.4,0) [0|0] "%" X
 SG_ DI_tcMaxRequest m40: 16|8@1+ (5,0) [0|0] "Nm" X
 SG_ DI_tcMinRequest m40: 24|8@1+ (5,0) [0|0] "Nm" X
 SG_ DI_tqSatUiDriveTorque m40: 32|8@1+ (0.4,0) [0|0] "%" X
 SG_ DI_tqSatUiRegenTorque m40: 40|8@1+ (0.4,0) [0|0] "%" X
 SG_ DI_tqScaleMaxMotorSpeed m40: 48|8@1+ (0.4,0) [0|0] "%" X
 SG_ DI_tqScaleShift m40: 56|8@1+ (0.4,0) [0|0] "%" X
 SG_ DI_veMassInvRaw m41: 8|12@1+ (1e-07,0.0001) [0|0] "1/kg" X
 SG_ DI_veResForce m41: 20|12@1- (0.0005,0) [0|0] "G" X
 SG_ DI_currentLimit m41: 32|16@1+ (0.1,0) [0|0] "A" X
 SG_ DI_wasteCurrentLimit m41: 48|16@1+ (0.1,0) [0|0] "A" X
 SG_ DI_pwrSatChargeCurrent m42: 8|8@1+ (0.4,0) [0|0] "%" X
 SG_ DI_fluxState m42: 16|4@1+ (1,0) [0|0] "" X
 SG_ DI_llsScale m42: 24|8@1+ (0.004,0) [0|0] "scale" X
 SG_ DI_llrScale m42: 32|8@1+ (0.015,0) [0|0] "scale" X
 SG_ DI_loadAngle m42: 40|16@1- (0.0003,0) [0|0] "rad" X
 SG_ DI_brakeSwitchNO m42: 62|1@1+ (1,0) [0|0] "" X
 SG_ DI_brakeSwitchNC m42: 63|1@1+ (1,0) [0|0] "" X
 SG_ DI_sysPedalMinTorque m44: 8|14@1+ (0.1,-1638.3) [0|0] "Nm" X
 SG_ DI_sysPedalMaxTorque m44: 22|14@1+ (0.1,0) [0|0] "Nm" X
 SG_ DI_sysPostPedalMinTorque m44: 36|14@1+ (0.1,-1638.3) [0|0] "Nm" X
 SG_ DI_sysPostPedalMaxTorque m44: 50|14@1+ (0.1,0) [0|0] "Nm" X
 SG_ DI_aebFaultReason m45: 16|4@1+ (1,0) [0|0] "" X
 SG_ DI_aebUnavailableReason m45: 24|4@1+ (1,0) [0|0] "" X
 SG_ DI_aebCancelReason m45: 32|8@1+ (1,0) [0|0] "" X
 SG_ DI_oilPumpPhaseCurrent m46: 8|8@1+ (0.1,0) [0|0] "A" X
 SG_ DI_oilPumpPhaseVoltage m46: 16|8@1+ (0.1,0) [0|0] "V" X
 SG_ DI_oilPumpPhaseAdvance m46: 24|8@1+ (0.4,0) [0|0] "%" X
 SG_ DI_oilPumpPressureEstimate m46: 32|8@1+ (2,0) [0|0] "kPa" X
 SG_ DI_rotorFlux m47: 16|16@1+ (0.0001,0) [0|0] "Wb" X
 SG_ DI_dcCableHeat m47: 32|16@1+ (0.001,0) [0|0] "kA2s" X
 SG_ DI_magnetTempEst m47: 48|8@1+ (1,-40) [0|0] "DegC" X
 SG_ DI_magnetTempEst_SFO m47: 56|8@1+ (1,-40) [0|0] "DegC" X
 SG_ DI_resolverOffsetCos m48: 8|8@1+ (0.015,0) [0|0] "V" X
 SG_ DI_resolverOffsetSin m48: 16|8@1+ (0.015,0) [0|0] "V" X
 SG_ DI_resolverPhaseOffset m48: 24|8@1+ (0.1,7.5) [0|0] "us" X
 SG_ DI_resolverCommonGain m48: 32|8@1+ (0.025,0) [0|0] "1" X
 SG_ DI_resolverReady m48: 40|1@1+ (1,0) [0|0] "" X
 SG_ DI_resolverNoCarrier m48: 41|1@1+ (1,0) [0|0] "" X
 SG_ DI_resolverNoPhaseLock m48: 42|1@1+ (1,0) [0|0] "" X
 SG_ DI_resolverClaMIA m48: 43|1@1+ (1,0) [0|0] "" X
 SG_ DI_soptTimeToTrip m49: 8|8@1+ (0.05,0) [0|0] "ms" X
 SG_ DI_soptTripDelay m49: 16|8@1+ (0.05,0) [0|0] "ms" X
 SG_ DI_soptTimeToOff m49: 24|11@1+ (0.05,0) [0|0] "ms" X
 SG_ DI_soptMaxCurrentMagSqrd m49: 40|16@1+ (100,0) [0|0] "A2" X
 SG_ DI_gateDriveSupplyState m50: 8|2@1+ (1,0) [0|0] "" X
 SG_ DI_gateDriveState m50: 10|3@1+ (1,0) [0|0] "" X
 SG_ DI_powerStageSafeState m50: 13|2@1+ (1,0) [0|0] "" X
 SG_ DI_sysHeatPowerOptimal m50: 16|8@1+ (0.08,0) [0|0] "kW" X
 SG_ DI_brkStState m50: 24|3@1+ (1,0) [0|0] "" X
 SG_ DI_torquePedalMin m51: 16|12@1+ (2,-7500) [0|0] "Nm" X
 SG_ DI_torquePedalMax m51: 28|12@1+ (2,0) [0|0] "Nm" X
 SG_ DI_torquePostPedalMin m51: 40|12@1+ (2,-7500) [0|0] "Nm" X
 SG_ DI_torquePostPedalMax m51: 52|12@1+ (2,0) [0|0] "Nm" X
 SG_ DI_dcCapTemp m64: 8|8@1+ (1,-40) [0|0] "DegC" X
 SG_ DI_busbarTemp m64: 16|8@1+ (1,-40) [0|0] "DegC" X
 SG_ DI_pcsTemp m64: 24|8@1+ (1,-40) [0|0] "DegC" X
 SG_ DI_statorTemp1 m64: 32|8@1+ (1,-40) [0|0] "DegC" X
 SG_ DI_statorTemp2 m64: 40|8@1+ (1,-40) [0|0] "DegC" X
 SG_ DI_immobilizerCondition m64: 63|1@1+ (1,0) [0|0] "" X
 SG_ DI_velocityEstimatorState m65: 8|3@1+ (1,0) [0|0] "" X
 SG_ DI_hvilCurrent m65: 16|10@1+ (0.025,0) [0|0] "mA" X
 SG_ DI_hvilCmVoltage m65: 32|10@1+ (0.02,0) [0|0] "V" X
 SG_ DI_cpu10HzMin m66: 8|8@1+ (0.4,0) [0|0] "%" X
 SG_ DI_cpu10HzMax m66: 16|8@1+ (0.4,0) [0|0] "%" X
 SG_ DI_cpu10HzAvg m66: 24|8@1+ (0.4,0) [0|0] "%" X
 SG_ DI_cpu100HzMin m66: 32|8@1+ (0.4,0) [0|0] "%" X
 SG_ DI_cpu100HzMax m66: 40|8@1+ (0.4,0) [0|0] "%" X
 SG_ DI_cpu100HzAvg m66: 48|8@1+ (0.4,0) [0|0] "%" X
 SG_ DI_module10HzStack m66: 56|8@1+ (0.4,0) [0|0] "%" X
 SG_ DI_cpu1kHzMin m67: 8|8@1+ (0.4,0) [0|0] "%" X
 SG_ DI_cpu1kHzMax m67: 16|8@1+ (0.4,0) [0|0] "%" X
 SG_ DI_cpu1kHzAvg m67: 24|8@1+ (0.4,0) [0|0] "%" X
 SG_ DI_cpu20kHzMin m67: 32|8@1+ (0.4,0) [0|0] "%" X
 SG_ DI_cpu20kHzMax m67: 40|8@1+ (0.4,0) [0|0] "%" X
 SG_ DI_cpu20kHzAvg m67: 48|8@1+ (0.4,0) [0|0] "%" X
 SG_ DI_controlStack m67: 56|8@1+ (0.4,0) [0|0] "%" X
 SG_ DI_systemStack m68: 8|8@1+ (0.4,0) [0|0] "%" X
 SG_ DI_idleStack m68: 16|8@1+ (0.4,0) [0|0] "%" X
 SG_ DI_decodeHardwareStack m68: 24|8@1+ (0.4,0) [0|0] "%" X
 SG_ DI_eepromStack m68: 32|8@1+ (0.4,0) [0|0] "%" X
 SG_ DI_udsStack m68: 40|8@1+ (0.4,0) [0|0] "%" X
 SG_ DI_xcpStack m68: 48|8@1+ (0.4,0) [0|0] "%" X
 SG_ DI_immobilizerStack m68: 56|8@1+ (0.4,0) [0|0] "%" X
 SG_ DI_hwFaultCounter m69: 8|4@1+ (1,0) [0|0] "" X
 SG_ DI_driveUnitOdometer m69: 32|32@1+ (10,0) [0|0] "rev" X
 SG_ DI_phaseOutBusbarTemp m70: 8|8@1+ (1,-40) [0|0] "DegC" X
 SG_ DI_phaseOutBusbarWeldTemp m70: 16|8@1+ (1,-40) [0|0] "DegC" X
 SG_ DI_phaseOutLugTemp m70: 24|8@1+ (1,-40) [0|0] "DegC" X
 SG_ DI_dcLinkCapTemp m70: 32|8@1+ (1,-40) [0|0] "DegC" X
 SG_ DI_hvDcCableTemp m70: 40|8@1+ (1,-40) [0|0] "DegC" X
 SG_ DI_negDcBusbarTemp m70: 48|8@1+ (1,-40) [0|0] "DegC" X
 SG_ DI_posDcBusbarTemp m70: 56|8@1+ (1,-40) [0|0] "DegC" X
 SG_ DI_statorEndWindingTemp m72: 8|8@1+ (1,-40) [0|0] "DegC" X
 SG_ DI_rotorMaxMagnetTemp m72: 16|8@1+ (1,-40) [0|0] "DegC" X

BO_ 1880 DI_dyno: 8 VEH
 SG_ DI_dynoSelector M: 0|8@1+ (1,0) [0|0] "" X
 SG_ DI_Isx m0: 16|16@1+ (1.5259e-05,0) [0|0] "A" X
 SG_ DI_Isy m0: 32|16@1+ (1.5259e-05,0) [0|0] "A" X
 SG_ DI_IsMag m0: 48|16@1- (0.1,0) [0|0] "A" X
 SG_ DI_Vsx m1: 16|16@1- (4e-05,0) [0|0] "mindex" X
 SG_ DI_Vsy m1: 32|16@1- (4e-05,0) [0|0] "mindex" X
 SG_ DI_voltageForFlux m1: 48|16@1+ (0.00762951,0) [0|0] "V" X
 SG_ DI_torqueMotor m2: 16|13@1- (0.25,0) [0|0] "Nm" X
 SG_ DI_state m2: 29|3@1+ (1,0) [0|0] "" X
 SG_ DI_motorRPM m2: 32|16@1- (1,0) [0|0] "RPM" X
 SG_ DI_torqueEstimate m2: 48|13@1- (0.25,0) [0|0] "Nm" X
 SG_ DI_pedalMinTorque m32: 8|12@1+ (0.25,-750) [0|0] "Nm" X
 SG_ DI_pedalMaxTorque m32: 20|12@1+ (0.25,0) [0|0] "Nm" X
 SG_ DI_postPedalMinTorque m32: 32|12@1+ (0.25,-750) [0|0] "Nm" X
 SG_ DI_postPedalMaxTorque m32: 44|12@1+ (0.25,0) [0|0] "Nm" X
 SG_ DI_slipEstimate m33: 8|10@1- (0.02,0) [0|0] "Hz" X
 SG_ DI_mechToElcFactor m64: 8|4@1- (1,0) [0|0] "" X

BO_ 1022 DI_estimatedBrakeTemp: 5 VEH
 SG_ DI_brakeFLTemp: 0|10@1+ (1,-40) [0|0] "DegC" X
 SG_ DI_brakeFRTemp: 10|10@1+ (1,-40) [0|0] "DegC" X
 SG_ DI_brakeRLTemp: 20|10@1+ (1,-40) [0|0] "DegC" X
 SG_ DI_brakeRRTemp: 30|10@1+ (1,-40) [0|0] "DegC" X

BO_ 1622 DI_info: 8 VEH
 SG_ DI_infoIndex M: 0|8@1+ (1,0) [0|0] "" X
 SG_ DI_buildType m10: 8|3@1+ (1,0) [0|0] "" X
 SG_ DI_buildConfigurationId m10: 16|16@1+ (1,0) [0|0] "" X
 SG_ DI_hardwareId m10: 32|8@1+ (1,0) [0|0] "" X
 SG_ DI_componentId m10: 48|16@1+ (1,0) [0|0] "" X
 SG_ DI_pcbaId m11: 16|8@1+ (1,0) [0|0] "" X
 SG_ DI_assemblyId m11: 24|8@1+ (1,0) [0|0] "" X
 SG_ DI_usageId m11: 32|16@1+ (1,0) [0|0] "" X
 SG_ DI_subUsageId m11: 48|16@1+ (1,0) [0|0] "" X
 SG_ DI_applicationSvnRevision m12: 8|24@1+ (1,0) [0|0] "" X
 SG_ DI_applicationSvnUrlHash m12: 32|32@1+ (1,0) [0|0] "" X
 SG_ DI_applicationCrc m13: 32|32@1+ (1,0) [0|0] "" X
 SG_ DI_bootloaderSvnRevision m14: 8|24@1+ (1,0) [0|0] "" X
 SG_ DI_bootloaderSvnUrlHash m14: 32|32@1+ (1,0) [0|0] "" X
 SG_ DI_oilPumpBuildType m16: 8|3@1+ (1,0) [0|0] "" X
 SG_ DI_oilPumpAppCrc m16: 16|32@1+ (1,0) [0|0] "" X
 SG_ DI_appGitHash m17: 10|54@1+ (4,0) [0|0] "" X
 SG_ DI_bootGitHash m18: 10|54@1+ (4,0) [0|0] "" X
 SG_ DI_platformTyp m19: 8|8@1+ (1,0) [0|0] "" X
 SG_ DI_infoBootLdUdsProtocolVersion m20: 8|8@1+ (1,0) [0|0] "" X
 SG_ DI_bootloaderCrc m20: 32|32@1+ (1,0) [0|0] "" X
 SG_ DI_subcomponentGitHash m31: 10|54@1+ (4,0) [0|0] "" X

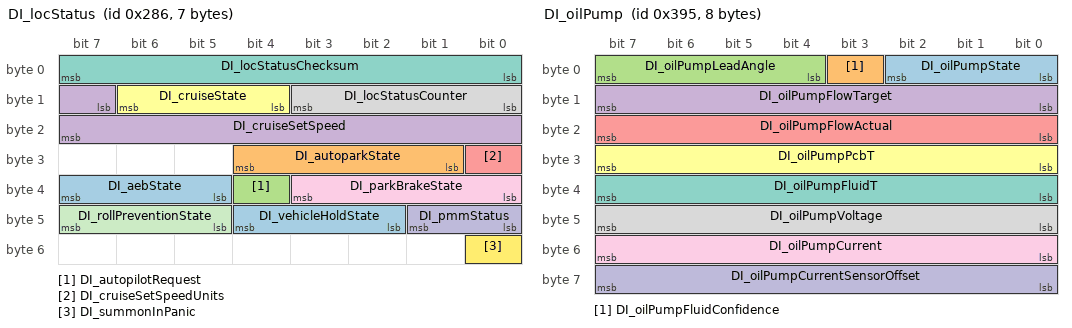
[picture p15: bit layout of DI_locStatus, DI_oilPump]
BO_ 646 DI_locStatus: 7 VEH
 SG_ DI_aebState: 37|3@1+ (1,0) [0|0] "" X
 SG_ DI_autoparkState: 25|4@1+ (1,0) [0|0] "" X
 SG_ DI_autopilotRequest: 36|1@1+ (1,0) [0|0] "" X
 SG_ DI_cruiseSetSpeed: 15|9@1+ (0.5,0) [0|0] "speed" X
 SG_ DI_cruiseSetSpeedUnits: 24|1@1+ (1,0) [0|0] "" X
 SG_ DI_cruiseState: 12|3@1+ (1,0) [0|0] "" X
 SG_ DI_locStatusChecksum: 0|8@1+ (1,0) [0|0] "" X
 SG_ DI_locStatusCounter: 8|4@1+ (1,0) [0|0] "" X
 SG_ DI_parkBrakeState: 32|4@1+ (1,0) [0|0] "" X
 SG_ DI_pmmStatus: 40|2@1+ (1,0) [0|0] "" X
 SG_ DI_rollPreventionState: 45|3@1+ (1,0) [0|0] "" X
 SG_ DI_summonInPanic: 48|1@1+ (1,0) [0|0] "" X
 SG_ DI_vehicleHoldState: 42|3@1+ (1,0) [0|0] "" X

BO_ 822 DI_maxRatedPower: 3 VEH
 SG_ DI_sysDrivePowerRated: 0|9@1+ (1,0) [0|0] "kW" X
 SG_ DI_sysRegenPowerRated: 16|8@1+ (1,-100) [0|0] "kW" X

BO_ 950 DI_odometerStatus: 4 VEH
 SG_ DI_odometer: 0|32@1+ (0.001,0) [0|0] "km" X

BO_ 917 DI_oilPump: 8 VEH
 SG_ DI_oilPumpState: 0|3@1+ (1,0) [0|0] "" X
 SG_ DI_oilPumpFluidConfidence : 3|1@1+ (1,0) [0|0] "" X
 SG_ DI_oilPumpLeadAngle : 4|4@1+ (1.875,0) [0|28.125] "deg" X
 SG_ DI_oilPumpFlowTarget: 8|8@1+ (0.06,0) [0|0] "LPM" X
 SG_ DI_oilPumpFlowActual: 16|8@1+ (0.06,0) [0|0] "LPM" X
 SG_ DI_oilPumpPcbT: 24|8@1+ (1,-40) [0|0] "DegC" X
 SG_ DI_oilPumpFluidT: 32|8@1+ (1,-40) [0|0] "DegC" X
 SG_ DI_oilPumpVoltage: 40|8@1+ (0.1,0) [0|0] "V" X
 SG_ DI_oilPumpCurrent: 48|8@1+ (0.1,0) [0|0] "A" X
 SG_ DI_oilPumpCurrentSensorOffset: 56|8@1+ (0.005,0) [0|0] "A" X

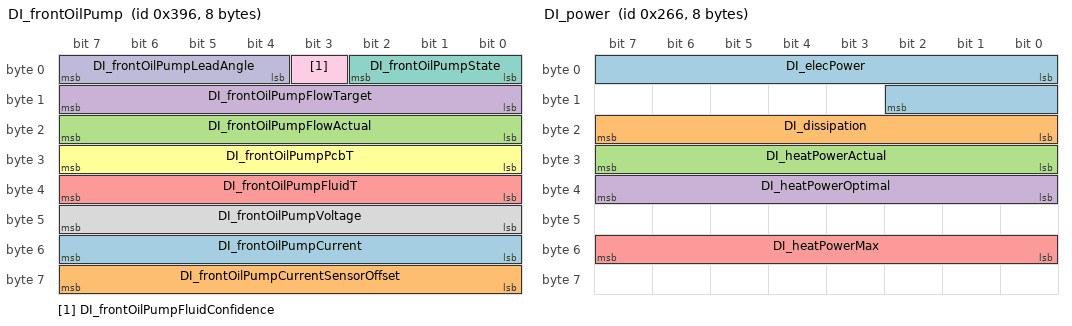
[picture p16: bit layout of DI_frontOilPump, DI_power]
BO_ 918 DI_frontOilPump: 8 VEH
 SG_ DI_frontOilPumpCurrent: 48|8@1+ (0.1,0) [0|0] "A" X
 SG_ DI_frontOilPumpCurrentSensorOffset: 56|8@1+ (0.005,0) [0|0] "A" X
 SG_ DI_frontOilPumpFlowActual: 16|8@1+ (0.06,0) [0|0] "LPM" X
 SG_ DI_frontOilPumpFlowTarget: 8|8@1+ (0.06,0) [0|0] "LPM" X
 SG_ DI_frontOilPumpFluidT: 32|8@1+ (1,-40) [0|0] "DegC" X
 SG_ DI_frontOilPumpPcbT: 24|8@1+ (1,-40) [0|0] "DegC" X
 SG_ DI_frontOilPumpState: 0|3@1+ (1,0) [0|0] "" X
 SG_ DI_frontOilPumpVoltage: 40|8@1+ (0.1,0) [0|0] "V" X
 SG_ DI_frontOilPumpFluidConfidence : 3|1@1+ (1,0) [0|0] "" X
 SG_ DI_frontOilPumpLeadAngle : 4|4@1+ (1.875,0) [0|28.125] "deg" X

BO_ 614 DI_power: 8 VEH
 SG_ DI_elecPower: 0|11@1- (0.5,0) [0|0] "kW" X
 SG_ DI_dissipation: 16|8@1+ (125,0) [0|0] "W" X
 SG_ DI_heatPowerActual: 24|8@1+ (0.08,0) [0|0] "kW" X
 SG_ DI_heatPowerOptimal: 32|8@1+ (0.08,0) [0|0] "kW" X
 SG_ DI_heatPowerMax: 48|8@1+ (0.08,0) [0|0] "kW" X

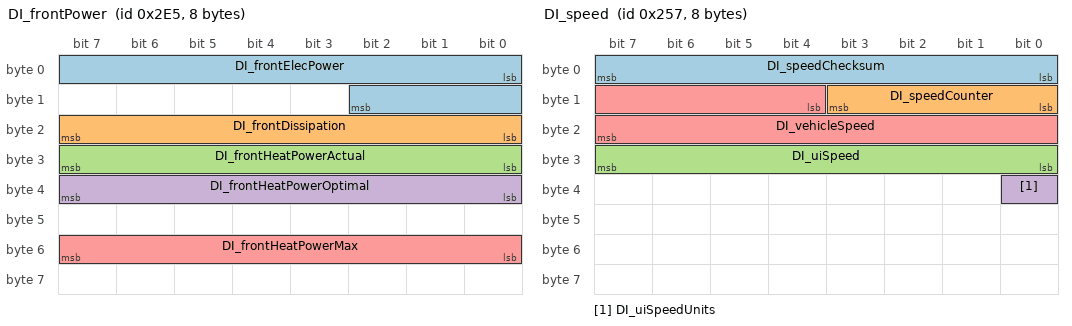
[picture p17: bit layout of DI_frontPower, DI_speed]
BO_ 741 DI_frontPower: 8 VEH
 SG_ DI_frontElecPower: 0|11@1- (0.5,0) [0|0] "kW" X
 SG_ DI_frontDissipation: 16|8@1+ (125,0) [0|0] "W" X
 SG_ DI_frontHeatPowerActual: 24|8@1+ (0.08,0) [0|0] "kW" X
 SG_ DI_frontHeatPowerOptimal: 32|8@1+ (0.08,0) [0|0] "kW" X
 SG_ DI_frontHeatPowerMax: 48|8@1+ (0.08,0) [0|0] "kW" X

BO_ 294 DI_hvBusStatus: 7 VEH
 SG_ DI_voltage : 0|10@1+ (0.5,0) [0|500] "V" X
 SG_ DI_current : 11|11@1+ (1,0) [0|2047] "A" X

BO_ 421 DI_frontHvBusStatus: 7 VEH
 SG_ DI_frontVoltage : 0|10@1+ (0.5,0) [0|500] "V" X
 SG_ DI_frontCurrent : 11|11@1+ (1,0) [0|2047] "A" X

BO_ 599 DI_speed: 8 VEH
 SG_ DI_speedChecksum: 0|8@1+ (1,0) [0|0] "" X
 SG_ DI_speedCounter: 8|4@1+ (1,0) [0|0] "" X
 SG_ DI_uiSpeed: 24|8@1+ (1,0) [0|0] "" X
 SG_ DI_uiSpeedUnits: 32|1@1+ (1,0) [0|0] "" X
 SG_ DI_vehicleSpeed: 12|12@1+ (0.08,-40) [0|0] "kph" X

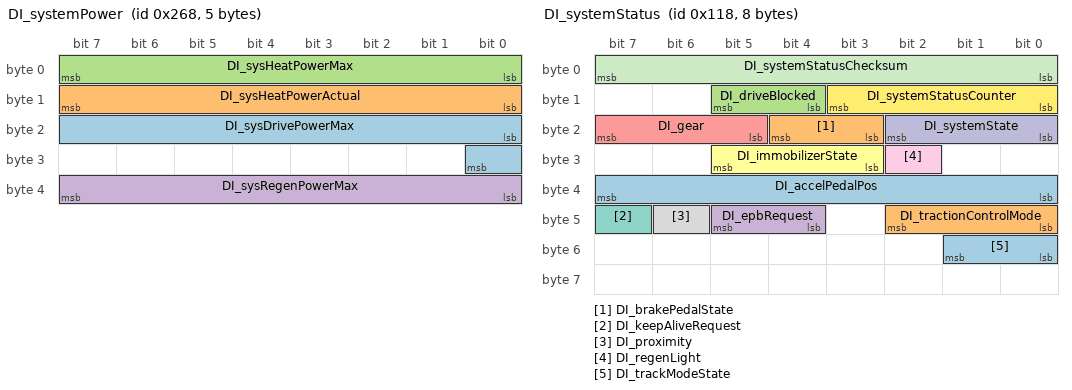
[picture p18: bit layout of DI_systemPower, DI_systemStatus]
BO_ 616 DI_systemPower: 5 VEH
 SG_ DI_sysDrivePowerMax: 16|9@1+ (1,0) [0|0] "kW" X
 SG_ DI_sysHeatPowerActual: 8|8@1+ (0.08,0) [0|0] "kW" X
 SG_ DI_sysHeatPowerMax: 0|8@1+ (0.08,0) [0|0] "kW" X
 SG_ DI_sysRegenPowerMax: 32|8@1+ (1,-100) [0|0] "kW" X

BO_ 280 DI_systemStatus: 8 VEH
 SG_ DI_accelPedalPos: 32|8@1+ (0.4,0) [0|0] "%" X
 SG_ DI_brakePedalState: 19|2@1+ (1,0) [0|0] "" X
 SG_ DI_driveBlocked : 12|2@1+ (1,0) [0|2] "" X
 SG_ DI_epbRequest: 44|2@1+ (1,0) [0|0] "" X
 SG_ DI_gear: 21|3@1+ (1,0) [0|0] "" X
 SG_ DI_immobilizerState: 27|3@1+ (1,0) [0|0] "" X
 SG_ DI_keepAliveRequest: 47|1@1+ (1,0) [0|0] "" X
 SG_ DI_proximity: 46|1@1+ (1,0) [0|0] "" X
 SG_ DI_regenLight: 26|1@1+ (1,0) [0|0] "" X
 SG_ DI_systemState: 16|3@1+ (1,0) [0|0] "" X
 SG_ DI_systemStatusChecksum: 0|8@1+ (1,0) [0|0] "" X
 SG_ DI_systemStatusCounter: 8|4@1+ (1,0) [0|0] "" X
 SG_ DI_trackModeState: 48|2@1+ (1,0) [0|0] "" X
 SG_ DI_tractionControlMode: 40|3@1+ (1,0) [0|0] "" X

BO_ 886 DI_frontInverterTemperature: 8 VEH
 SG_ DI_frontDcCapT: 24|8@1+ (1,-40) [0|0] "DegC" X
 SG_ DI_frontHeatsinkT: 32|8@1+ (1,-40) [0|0] "DegC" X
 SG_ DI_frontInverterT: 8|8@1+ (1,-40) [0|0] "DegC" X
 SG_ DI_frontInverterTQF: 56|2@1+ (1,0) [0|0] "" X
 SG_ DI_frontInverterTpct: 40|8@1+ (0.4,0) [0|0] "%" X
 SG_ DI_frontPcbT: 0|8@1+ (1,-40) [0|0] "DegC" X
 SG_ DI_frontStatorT: 16|8@1+ (1,-40) [0|0] "DegC" X
 SG_ DI_frontStatorTpct: 48|8@1+ (0.4,0) [0|0] "%" X
 SG_ DI_frontInverterTQF: 56|2@1+ (1,0) [0|0] "" X

BO_ 789 DI_temperature: 8 VEH
 SG_ DI_temperatureIndex M: 0|1@1+ (1,0) [0|1] "" X
 SG_ DI_inverterT m0: 8|8@1+ (1,-40) [0|0] "DegC" X
 SG_ DI_statorT m0: 16|8@1+ (1,-40) [0|0] "DegC" X
 SG_ DI_dcCapT m0: 24|8@1+ (1,-40) [0|0] "DegC" X
 SG_ DI_heatsinkT m0: 32|8@1+ (1,-40) [0|0] "DegC" X
 SG_ DI_inverterTpct m0: 40|8@1+ (0.4,0) [0|0] "%" X
 SG_ DI_statorTpct m0: 48|8@1+ (0.4,0) [0|0] "%" X
 SG_ DI_inverterTQF m0: 56|2@1+ (1,0) [0|3] "" X

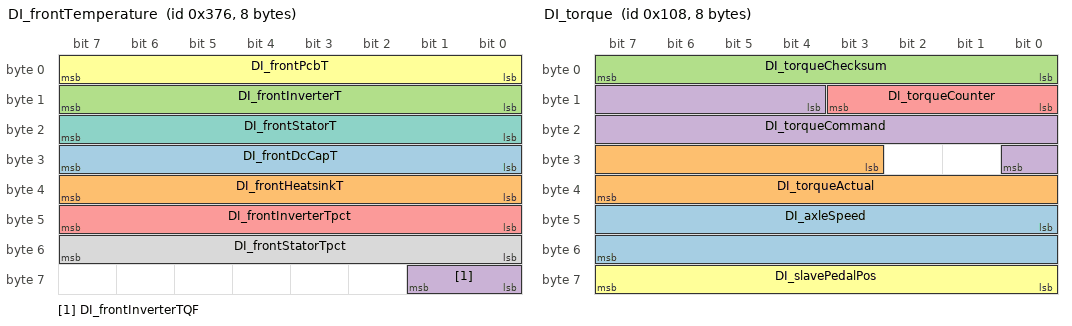
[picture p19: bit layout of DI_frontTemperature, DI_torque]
BO_ 886 DI_frontTemperature: 8 VEH
 SG_ DI_frontDcCapT: 24|8@1+ (1,-40) [0|0] "DegC" X
 SG_ DI_frontHeatsinkT: 32|8@1+ (1,-40) [0|0] "DegC" X
 SG_ DI_frontInverterT: 8|8@1+ (1,-40) [0|0] "DegC" X
 SG_ DI_frontInverterTQF: 56|2@1+ (1,0) [0|0] "" X
 SG_ DI_frontInverterTpct: 40|8@1+ (0.4,0) [0|0] "%" X
 SG_ DI_frontPcbT: 0|8@1+ (1,-40) [0|0] "DegC" X
 SG_ DI_frontStatorT: 16|8@1+ (1,-40) [0|0] "DegC" X
 SG_ DI_frontStatorTpct: 48|8@1+ (0.4,0) [0|0] "%" X

BO_ 1367 DI_frontThermalControl: 4 VEH
 SG_ DI_frontActiveInletTempReq : 8|8@1+ (1,-40) [-40|120] "C" X
 SG_ DI_frontCoolantFlowReq : 16|8@1+ (0.2,0) [0|50] "LPM" X
 SG_ DI_frontOilFlowReq : 24|8@1+ (0.06,0) [0|15] "LPM" X
 SG_ DI_frontPassiveInletTempReq : 0|8@1+ (1,-40) [-40|120] "C" X

BO_ 1495 DI_thermalControl: 3 VEH
 SG_ DI_activeInletTempReq: 8|8@1+ (1,-40) [0|0] "DegC" X
 SG_ DI_coolantFlowReq: 16|8@1+ (0.2,0) [0|0] "LPM" X
 SG_ DI_oilFlowReq : 24|8@1+ (0.06,0) [0|15] "LPM" X
 SG_ DI_passiveInletTempReq: 0|8@1+ (1,-40) [0|0] "DegC" X

BO_ 264 DI_torque: 8 VEH
 SG_ DI_axleSpeed: 40|16@1- (0.1,0) [0|0] "RPM" X
 SG_ DI_torqueActual: 27|13@1- (2,0) [0|0] "Nm" X
 SG_ DI_torqueChecksum: 0|8@1+ (1,0) [0|0] "" X
 SG_ DI_torqueCommand: 12|13@1- (2,0) [0|0] "Nm" X
 SG_ DI_torqueCounter: 8|4@1+ (1,0) [0|0] "" X
 SG_ DI_slavePedalPos : 56|8@1+ (0.4,0) [0|100] "%" X
